VERSION ""

NS_ :

BS_:

BU_: ServiceTool DUT

BO_ 2566764030 DM23: 22 Vector__XXX
 SG_ FlashRedStopLamp : 12|2@1+ (1,0) [0|3] "" Vector__XXX
 SG_ FlashProtectLamp : 8|2@1+ (1,0) [0|3] "" Vector__XXX
 SG_ FlashMalfuncIndicatorLamp : 14|2@1+ (1,0) [0|3] "" Vector__XXX
 SG_ FlashAmberWarningLamp : 10|2@1+ (1,0) [0|3] "" Vector__XXX
 SG_ MalfunctionIndicatorLampStatus : 6|2@1+ (1,0) [0|3] "" Vector__XXX
 SG_ RedStopLampState : 4|2@1+ (1,0) [0|3] "" Vector__XXX
 SG_ AmberWarningLampStatus : 2|2@1+ (1,0) [0|3] "" Vector__XXX
 SG_ ProtectLampStatus : 0|2@1+ (1,0) [0|3] "" Vector__XXX
 SG_ DTC5 : 144|32@1+ (1,0) [0|4294967295] "" Vector__XXX
 SG_ DTC4 : 112|32@1+ (1,0) [0|4294967295] "" Vector__XXX
 SG_ DTC3 : 80|32@1+ (1,0) [0|4294967295] "" Vector__XXX
 SG_ DTC2 : 48|32@1+ (1,0) [0|4294967295] "" Vector__XXX
 SG_ DTC1 : 16|32@1+ (1,0) [0|4294967295] "" Vector__XXX

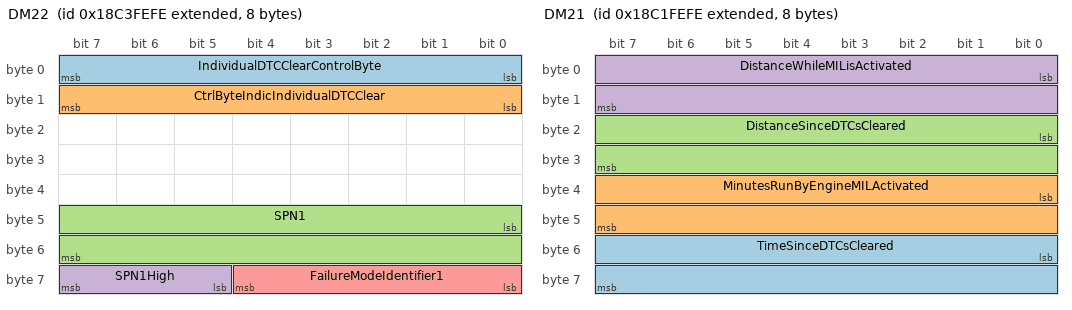
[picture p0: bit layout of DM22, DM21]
BO_ 2562981630 DM22: 8 Vector__XXX
 SG_ IndividualDTCClearControlByte : 0|8@1+ (1,0) [0|255] "" Vector__XXX
 SG_ CtrlByteIndicIndividualDTCClear : 8|8@1+ (1,0) [0|255] "" Vector__XXX
 SG_ SPN1 : 40|16@1+ (1,0) [0|65536] "" Vector__XXX
 SG_ SPN1High : 61|3@1+ (1,0) [0|7] "" Vector__XXX
 SG_ FailureModeIdentifier1 : 56|5@1+ (1,0) [0|0] "" Vector__XXX

BO_ 2562850558 DM21: 8 Vector__XXX
 SG_ TimeSinceDTCsCleared : 48|16@1+ (1,0) [0|64255] "mins" Vector__XXX
 SG_ MinutesRunByEngineMILActivated : 32|16@1+ (1,0) [0|64255] "mins" Vector__XXX
 SG_ DistanceSinceDTCsCleared : 16|16@1+ (1,0) [0|64255] "km" Vector__XXX
 SG_ DistanceWhileMILisActivated : 0|16@1+ (1,0) [0|64255] "km" Vector__XXX

BO_ 2562916094 DM20: 11 Vector__XXX
 SG_ ApplSysMonitorDenominator : 72|16@1+ (1,0) [0|65535] "" Vector__XXX
 SG_ ApplSysMonitorNumerator : 56|16@1+ (1,0) [0|65535] "" Vector__XXX
 SG_ SPNofApplSysMonitor : 32|24@1+ (1,0) [0|524287] "" Vector__XXX
 SG_ OBDMonitoringCondEncountered : 16|16@1+ (1,0) [0|65535] "" Vector__XXX
 SG_ IgnitionCycleCounter : 0|16@1+ (1,0) [0|65535] "" Vector__XXX

BO_ 2566835198 DM2: 22 Vector__XXX
 SG_ MalfunctionIndicatorLampStatus : 6|2@1+ (1,0) [0|3] "" Vector__XXX
 SG_ RedStopLampState : 4|2@1+ (1,0) [0|3] "" Vector__XXX
 SG_ AmberWarningLampStatus : 2|2@1+ (1,0) [0|3] "" Vector__XXX
 SG_ ProtectLampStatus : 0|2@1+ (1,0) [0|3] "" Vector__XXX
 SG_ FlashRedStopLamp : 12|2@1+ (1,0) [0|3] "" Vector__XXX
 SG_ FlashProtectLamp : 8|2@1+ (1,0) [0|3] "" Vector__XXX
 SG_ FlashMalfuncIndicatorLamp : 14|2@1+ (1,0) [0|3] "" Vector__XXX
 SG_ FlashAmberWarningLamp : 10|2@1+ (1,0) [0|3] "" Vector__XXX
 SG_ DTC5 : 144|32@1+ (1,0) [0|4294967295] "" Vector__XXX
 SG_ DTC4 : 112|32@1+ (1,0) [0|4294967295] "" Vector__XXX
 SG_ DTC3 : 80|32@1+ (1,0) [0|4294967295] "" Vector__XXX
 SG_ DTC2 : 48|32@1+ (1,0) [0|4294967295] "" Vector__XXX
 SG_ DTC1 : 16|32@1+ (1,0) [0|4294967295] "" Vector__XXX

BO_ 2564030206 DM19: 20 Vector__XXX
 SG_ CalibrationID4 : 128|32@1+ (1,0) [0|4294967295] "" Vector__XXX
 SG_ CalibrationID3 : 96|32@1+ (1,0) [0|4294967295] "" Vector__XXX
 SG_ CalibrationID2 : 64|32@1+ (1,0) [0|4294967295] "" Vector__XXX
 SG_ CalibrationID1 : 32|32@1+ (1,0) [0|4294967295] "" Vector__XXX
 SG_ CalibrationVerificationNumber : 0|32@1+ (1,0) [0|4294967295] "" Vector__XXX

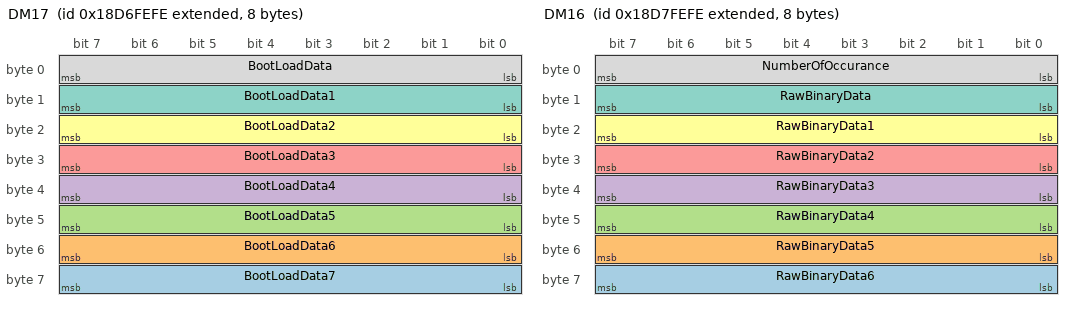
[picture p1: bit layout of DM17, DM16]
BO_ 2564226814 DM17: 8 Vector__XXX
 SG_ BootLoadData7 : 56|8@1- (1,0) [0|0] "" Vector__XXX
 SG_ BootLoadData6 : 48|8@1- (1,0) [0|0] "" Vector__XXX
 SG_ BootLoadData5 : 40|8@1- (1,0) [0|0] "" Vector__XXX
 SG_ BootLoadData4 : 32|8@1- (1,0) [0|0] "" Vector__XXX
 SG_ BootLoadData3 : 24|8@1- (1,0) [0|0] "" Vector__XXX
 SG_ BootLoadData2 : 16|8@1- (1,0) [0|0] "" Vector__XXX
 SG_ BootLoadData1 : 8|8@1- (1,0) [0|0] "" Vector__XXX
 SG_ BootLoadData : 0|8@1- (1,0) [0|0] "" Vector__XXX

BO_ 2564292350 DM16: 8 Vector__XXX
 SG_ RawBinaryData6 : 56|8@1- (1,0) [0|0] "" Vector__XXX
 SG_ RawBinaryData5 : 48|8@1- (1,0) [0|0] "" Vector__XXX
 SG_ RawBinaryData4 : 40|8@1- (1,0) [0|0] "" Vector__XXX
 SG_ RawBinaryData3 : 32|8@1- (1,0) [0|0] "" Vector__XXX
 SG_ RawBinaryData2 : 24|8@1- (1,0) [0|0] "" Vector__XXX
 SG_ RawBinaryData1 : 16|8@1- (1,0) [0|0] "" Vector__XXX
 SG_ RawBinaryData : 8|8@1- (1,0) [0|0] "" Vector__XXX
 SG_ NumberOfOccurance : 0|8@1+ (1,0) [0|0] "" Vector__XXX

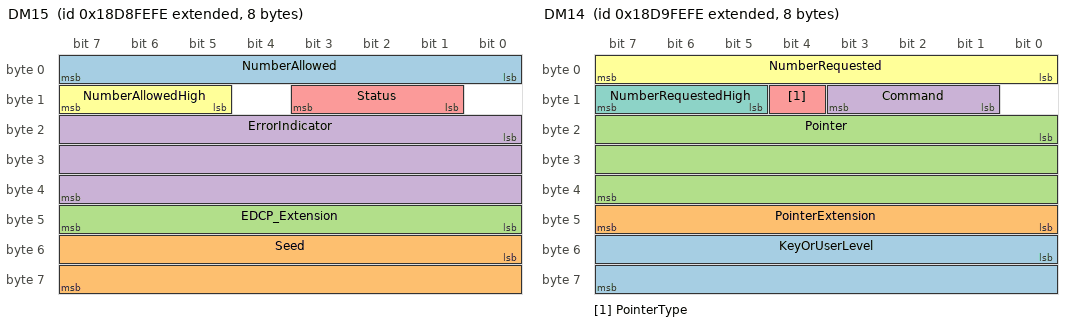
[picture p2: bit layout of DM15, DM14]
BO_ 2564357886 DM15: 8 Vector__XXX
 SG_ NumberAllowed : 0|8@1+ (1,0) [0|2047] "" Vector__XXX
 SG_ Seed : 48|16@1+ (1,0) [0|65535] "" Vector__XXX
 SG_ EDCP_Extension : 40|8@1+ (1,0) [0|255] "" Vector__XXX
 SG_ ErrorIndicator : 16|24@1+ (1,0) [0|16777215] "" Vector__XXX
 SG_ Status : 9|3@1+ (1,0) [0|7] "" Vector__XXX
 SG_ NumberAllowedHigh : 13|3@1+ (1,0) [0|7] "" Vector__XXX

BO_ 2564423422 DM14: 8 Vector__XXX
 SG_ KeyOrUserLevel : 48|16@1+ (1,0) [0|65535] "" Vector__XXX
 SG_ PointerExtension : 40|8@1+ (1,0) [0|255] "" Vector__XXX
 SG_ Pointer : 16|24@1+ (1,0) [0|16777215] "" Vector__XXX
 SG_ Command : 9|3@1+ (1,0) [0|7] "" Vector__XXX
 SG_ PointerType : 12|1@1+ (1,0) [0|1] "" Vector__XXX
 SG_ NumberRequested : 0|8@1+ (1,0) [0|2047] "" Vector__XXX
 SG_ NumberRequestedHigh : 13|3@1+ (1,0) [0|7] "" Vector__XXX

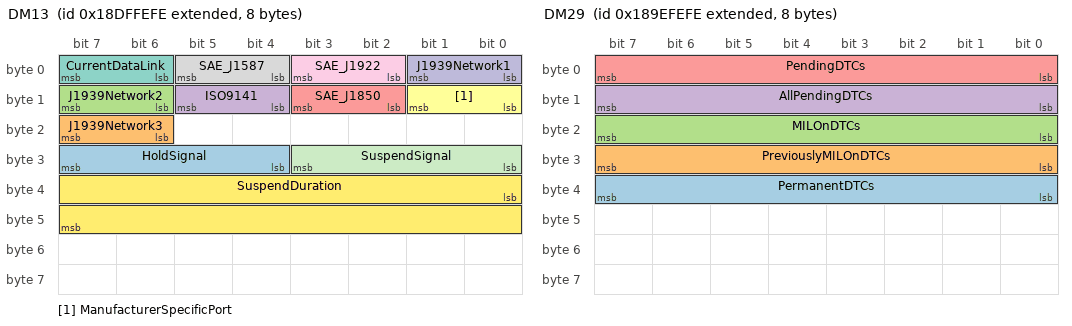
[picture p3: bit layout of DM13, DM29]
BO_ 2564816638 DM13: 8 Vector__XXX
 SG_ HoldSignal : 28|4@1+ (1,0) [0|15] "" Vector__XXX
 SG_ J1939Network3 : 22|2@1+ (1,0) [0|3] "" Vector__XXX
 SG_ J1939Network2 : 14|2@1+ (1,0) [0|3] "" Vector__XXX
 SG_ ISO9141 : 12|2@1+ (1,0) [0|3] "" Vector__XXX
 SG_ SAE_J1850 : 10|2@1+ (1,0) [0|3] "" Vector__XXX
 SG_ ManufacturerSpecificPort : 8|2@1+ (1,0) [0|3] "" Vector__XXX
 SG_ CurrentDataLink : 6|2@1+ (1,0) [0|3] "" Vector__XXX
 SG_ SAE_J1587 : 4|2@1+ (1,0) [0|3] "" Vector__XXX
 SG_ SAE_J1922 : 2|2@1+ (1,0) [0|3] "" Vector__XXX
 SG_ J1939Network1 : 0|2@1+ (1,0) [0|3] "" Vector__XXX
 SG_ SuspendSignal : 24|4@1+ (1,0) [0|15] "" Vector__XXX
 SG_ SuspendDuration : 32|16@1+ (1,0) [0|64255] "sec" Vector__XXX

BO_ 2566837502 DM12: 22 Vector__XXX
 SG_ FlashRedStopLamp : 12|2@1+ (1,0) [0|3] "" Vector__XXX
 SG_ FlashProtectLamp : 8|2@1+ (1,0) [0|3] "" Vector__XXX
 SG_ MalfunctionIndicatorLampStatus : 6|2@1+ (1,0) [0|3] "" Vector__XXX
 SG_ RedStopLampState : 4|2@1+ (1,0) [0|3] "" Vector__XXX
 SG_ AmberWarningLampStatus : 2|2@1+ (1,0) [0|3] "" Vector__XXX
 SG_ ProtectLampStatus : 0|2@1+ (1,0) [0|3] "" Vector__XXX
 SG_ FlashMalfuncIndicatorLamp : 14|2@1+ (1,0) [0|3] "" Vector__XXX
 SG_ FlashAmberWarningLamp : 10|2@1+ (1,0) [0|3] "" Vector__XXX
 SG_ DTC5 : 144|32@1+ (1,0) [0|4294967295] "" Vector__XXX
 SG_ DTC4 : 112|32@1+ (1,0) [0|4294967295] "" Vector__XXX
 SG_ DTC3 : 80|32@1+ (1,0) [0|4294967295] "" Vector__XXX
 SG_ DTC2 : 48|32@1+ (1,0) [0|4294967295] "" Vector__XXX
 SG_ DTC1 : 16|32@1+ (1,0) [0|4294967295] "" Vector__XXX

BO_ 2566837246 DM11: 0 Vector__XXX

BO_ 2566836990 DM10: 8 Vector__XXX
 SG_ TestIdentifierSupported : 0|64@1+ (1,0) [1|1.844674407371E+019] "" Vector__XXX

BO_ 2566834942 DM1: 22 Vector__XXX
 SG_ FlashRedStopLamp : 12|2@1+ (1,0) [0|3] "" Vector__XXX
 SG_ FlashProtectLamp : 8|2@1+ (1,0) [0|3] "" Vector__XXX
 SG_ FlashMalfuncIndicatorLamp : 14|2@1+ (1,0) [0|3] "" Vector__XXX
 SG_ FlashAmberWarningLamp : 10|2@1+ (1,0) [0|3] "" Vector__XXX
 SG_ MalfunctionIndicatorLampStatus : 6|2@1+ (1,0) [0|3] "" Vector__XXX
 SG_ AmberWarningLampStatus : 2|2@1+ (1,0) [0|3] "" Vector__XXX
 SG_ RedStopLampState : 4|2@1+ (1,0) [0|3] "" Vector__XXX
 SG_ ProtectLampStatus : 0|2@1+ (1,0) [0|3] "" Vector__XXX
 SG_ DTC5 : 144|32@1+ (1,0) [0|4294967295] "" Vector__XXX
 SG_ DTC4 : 112|32@1+ (1,0) [0|4294967295] "" Vector__XXX
 SG_ DTC3 : 80|32@1+ (1,0) [0|4294967295] "" Vector__XXX
 SG_ DTC2 : 48|32@1+ (1,0) [0|4294967295] "" Vector__XXX
 SG_ DTC1 : 16|32@1+ (1,0) [0|4294967295] "" Vector__XXX

BO_ 2566838526 CA: 9 Vector__XXX
 SG_ AddressAssignment : 64|8@1+ (1,0) [0|255] "" Vector__XXX
 SG_ ArbitraryAddressCapable : 63|1@1+ (1,0) [0|1] "" Vector__XXX
 SG_ IndustryGroup M : 60|3@1+ (1,0) [0|7] "" Vector__XXX
 SG_ VehicleSystemInstance : 56|4@1+ (1,0) [0|15] "" Vector__XXX
 SG_ Function : 40|8@1+ (1,0) [0|255] "" Vector__XXX
 SG_ VehicleSystem m0 : 49|7@1+ (1,0) [0|127] "" Vector__XXX
 SG_ FunctionInstance : 35|5@1+ (1,0) [0|31] "" Vector__XXX
 SG_ ECUInstance : 32|3@1+ (1,0) [0|7] "" Vector__XXX
 SG_ ManufacturerCode : 21|11@1+ (1,0) [0|2047] "" Vector__XXX
 SG_ IdentityNumber : 0|21@1+ (1,0) [0|2097152] "" Vector__XXX
 SG_ VehicleSystem5 m5 : 49|7@1+ (1,0) [0|127] "" Vector__XXX
 SG_ VehicleSystem4 m4 : 49|7@1+ (1,0) [0|127] "" Vector__XXX
 SG_ VehicleSystem3 m3 : 49|7@1+ (1,0) [0|127] "" Vector__XXX
 SG_ VehicleSystem2 m2 : 49|7@1+ (1,0) [0|127] "" Vector__XXX
 SG_ VehicleSystem1 m1 : 49|7@1+ (1,0) [0|127] "" Vector__XXX

BO_ 2632711934 TPDT: 8 Vector__XXX
 SG_ SequenceNumber : 0|8@1+ (1,0) [0|255] "" Vector__XXX

BO_ 2632777470 TPCM: 8 Vector__XXX
 SG_ TotalNumberOfPacketsEoMA m19 : 24|8@1+ (1,0) [0|255] "" Vector__XXX
 SG_ TotalMessageSizeEoMA m19 : 8|16@1+ (1,0) [0|64255] "counts" Vector__XXX
 SG_ TotalMessageSizeBAM m32 : 8|16@1+ (1,0) [0|64255] "counts" Vector__XXX
 SG_ TotalNumberOfPacketsBAM m32 : 24|8@1+ (1,0) [0|255] "" Vector__XXX
 SG_ ConnectionAbortReason m255 : 8|8@1+ (1,0) [0|255] "" Vector__XXX
 SG_ NextPacketNumberToBeSent m17 : 16|8@1+ (1,0) [0|255] "" Vector__XXX
 SG_ NumberOfPacketsThatCanBeSent m17 : 8|8@1+ (1,0) [0|255] "" Vector__XXX
 SG_ PGNumber : 40|24@1+ (1,0) [0|16777200] "" Vector__XXX
 SG_ MaximumNumberOfPackets m16 : 32|8@1+ (1,0) [0|255] "" Vector__XXX
 SG_ TotalNumberOfPackets m16 : 24|8@1+ (1,0) [0|255] "" Vector__XXX
 SG_ TotalMessageSize m16 : 8|16@1+ (1,0) [0|64255] "counts" Vector__XXX
 SG_ ControlByte M : 0|8@1+ (1,0) [0|255] "" Vector__XXX

BO_ 2565537534 RQST: 3 Vector__XXX
 SG_ ParameterGroupNumber : 0|24@1+ (1,0) [0|16777215] "" Vector__XXX

BO_ 2566739198 DM52: 22 Vector__XXX
 SG_ FlashRedStopLamp : 12|2@1+ (1,0) [0|3] "" Vector__XXX
 SG_ FlashProtectLamp : 8|2@1+ (1,0) [0|3] "" Vector__XXX
 SG_ FlashMalfuncIndicatorLamp : 14|2@1+ (1,0) [0|3] "" Vector__XXX
 SG_ FlashAmberWarningLamp : 10|2@1+ (1,0) [0|3] "" Vector__XXX
 SG_ MalfunctionIndicatorLampStatus : 6|2@1+ (1,0) [0|3] "" Vector__XXX
 SG_ AmberWarningLampStatus : 2|2@1+ (1,0) [0|3] "" Vector__XXX
 SG_ RedStopLampState : 4|2@1+ (1,0) [0|3] "" Vector__XXX
 SG_ ProtectLampStatus : 0|2@1+ (1,0) [0|3] "" Vector__XXX
 SG_ DTC5 : 144|32@1+ (1,0) [0|4294967295] "" Vector__XXX
 SG_ DTC4 : 112|32@1+ (1,0) [0|4294967295] "" Vector__XXX
 SG_ DTC3 : 80|32@1+ (1,0) [0|4294967295] "" Vector__XXX
 SG_ DTC2 : 48|32@1+ (1,0) [0|4294967295] "" Vector__XXX
 SG_ DTC1 : 16|32@1+ (1,0) [0|4294967295] "" Vector__XXX

BO_ 2566739454 DM51: 22 Vector__XXX
 SG_ FlashRedStopLamp : 12|2@1+ (1,0) [0|3] "" Vector__XXX
 SG_ FlashProtectLamp : 8|2@1+ (1,0) [0|3] "" Vector__XXX
 SG_ FlashMalfuncIndicatorLamp : 14|2@1+ (1,0) [0|3] "" Vector__XXX
 SG_ FlashAmberWarningLamp : 10|2@1+ (1,0) [0|3] "" Vector__XXX
 SG_ MalfunctionIndicatorLampStatus : 6|2@1+ (1,0) [0|3] "" Vector__XXX
 SG_ AmberWarningLampStatus : 2|2@1+ (1,0) [0|3] "" Vector__XXX
 SG_ RedStopLampState : 4|2@1+ (1,0) [0|3] "" Vector__XXX
 SG_ ProtectLampStatus : 0|2@1+ (1,0) [0|3] "" Vector__XXX
 SG_ DTC5 : 144|32@1+ (1,0) [0|4294967295] "" Vector__XXX
 SG_ DTC4 : 112|32@1+ (1,0) [0|4294967295] "" Vector__XXX
 SG_ DTC3 : 80|32@1+ (1,0) [0|4294967295] "" Vector__XXX
 SG_ DTC2 : 48|32@1+ (1,0) [0|4294967295] "" Vector__XXX
 SG_ DTC1 : 16|32@1+ (1,0) [0|4294967295] "" Vector__XXX

BO_ 2566739710 DM50: 22 Vector__XXX
 SG_ FlashRedStopLamp : 12|2@1+ (1,0) [0|3] "" Vector__XXX
 SG_ FlashProtectLamp : 8|2@1+ (1,0) [0|3] "" Vector__XXX
 SG_ FlashMalfuncIndicatorLamp : 14|2@1+ (1,0) [0|3] "" Vector__XXX
 SG_ FlashAmberWarningLamp : 10|2@1+ (1,0) [0|3] "" Vector__XXX
 SG_ MalfunctionIndicatorLampStatus : 6|2@1+ (1,0) [0|3] "" Vector__XXX
 SG_ AmberWarningLampStatus : 2|2@1+ (1,0) [0|3] "" Vector__XXX
 SG_ RedStopLampState : 4|2@1+ (1,0) [0|3] "" Vector__XXX
 SG_ ProtectLampStatus : 0|2@1+ (1,0) [0|3] "" Vector__XXX
 SG_ DTC5 : 144|32@1+ (1,0) [0|4294967295] "" Vector__XXX
 SG_ DTC4 : 112|32@1+ (1,0) [0|4294967295] "" Vector__XXX
 SG_ DTC3 : 80|32@1+ (1,0) [0|4294967295] "" Vector__XXX
 SG_ DTC2 : 48|32@1+ (1,0) [0|4294967295] "" Vector__XXX
 SG_ DTC1 : 16|32@1+ (1,0) [0|4294967295] "" Vector__XXX

BO_ 2566739966 DM49: 22 Vector__XXX
 SG_ FlashRedStopLamp : 12|2@1+ (1,0) [0|3] "" Vector__XXX
 SG_ FlashProtectLamp : 8|2@1+ (1,0) [0|3] "" Vector__XXX
 SG_ FlashMalfuncIndicatorLamp : 14|2@1+ (1,0) [0|3] "" Vector__XXX
 SG_ FlashAmberWarningLamp : 10|2@1+ (1,0) [0|3] "" Vector__XXX
 SG_ MalfunctionIndicatorLampStatus : 6|2@1+ (1,0) [0|3] "" Vector__XXX
 SG_ AmberWarningLampStatus : 2|2@1+ (1,0) [0|3] "" Vector__XXX
 SG_ RedStopLampState : 4|2@1+ (1,0) [0|3] "" Vector__XXX
 SG_ ProtectLampStatus : 0|2@1+ (1,0) [0|3] "" Vector__XXX
 SG_ DTC5 : 144|32@1+ (1,0) [0|4294967295] "" Vector__XXX
 SG_ DTC4 : 112|32@1+ (1,0) [0|4294967295] "" Vector__XXX
 SG_ DTC3 : 80|32@1+ (1,0) [0|4294967295] "" Vector__XXX
 SG_ DTC2 : 48|32@1+ (1,0) [0|4294967295] "" Vector__XXX
 SG_ DTC1 : 16|32@1+ (1,0) [0|4294967295] "" Vector__XXX

BO_ 2566740222 DM48: 22 Vector__XXX
 SG_ FlashRedStopLamp : 12|2@1+ (1,0) [0|3] "" Vector__XXX
 SG_ FlashProtectLamp : 8|2@1+ (1,0) [0|3] "" Vector__XXX
 SG_ FlashMalfuncIndicatorLamp : 14|2@1+ (1,0) [0|3] "" Vector__XXX
 SG_ FlashAmberWarningLamp : 10|2@1+ (1,0) [0|3] "" Vector__XXX
 SG_ MalfunctionIndicatorLampStatus : 6|2@1+ (1,0) [0|3] "" Vector__XXX
 SG_ AmberWarningLampStatus : 2|2@1+ (1,0) [0|3] "" Vector__XXX
 SG_ RedStopLampState : 4|2@1+ (1,0) [0|3] "" Vector__XXX
 SG_ ProtectLampStatus : 0|2@1+ (1,0) [0|3] "" Vector__XXX
 SG_ DTC5 : 144|32@1+ (1,0) [0|4294967295] "" Vector__XXX
 SG_ DTC4 : 112|32@1+ (1,0) [0|4294967295] "" Vector__XXX
 SG_ DTC3 : 80|32@1+ (1,0) [0|4294967295] "" Vector__XXX
 SG_ DTC2 : 48|32@1+ (1,0) [0|4294967295] "" Vector__XXX
 SG_ DTC1 : 16|32@1+ (1,0) [0|4294967295] "" Vector__XXX

BO_ 2566740478 DM47: 22 Vector__XXX
 SG_ FlashRedStopLamp : 12|2@1+ (1,0) [0|3] "" Vector__XXX
 SG_ FlashProtectLamp : 8|2@1+ (1,0) [0|3] "" Vector__XXX
 SG_ FlashMalfuncIndicatorLamp : 14|2@1+ (1,0) [0|3] "" Vector__XXX
 SG_ FlashAmberWarningLamp : 10|2@1+ (1,0) [0|3] "" Vector__XXX
 SG_ MalfunctionIndicatorLampStatus : 6|2@1+ (1,0) [0|3] "" Vector__XXX
 SG_ AmberWarningLampStatus : 2|2@1+ (1,0) [0|3] "" Vector__XXX
 SG_ RedStopLampState : 4|2@1+ (1,0) [0|3] "" Vector__XXX
 SG_ ProtectLampStatus : 0|2@1+ (1,0) [0|3] "" Vector__XXX
 SG_ DTC5 : 144|32@1+ (1,0) [0|4294967295] "" Vector__XXX
 SG_ DTC4 : 112|32@1+ (1,0) [0|4294967295] "" Vector__XXX
 SG_ DTC3 : 80|32@1+ (1,0) [0|4294967295] "" Vector__XXX
 SG_ DTC2 : 48|32@1+ (1,0) [0|4294967295] "" Vector__XXX
 SG_ DTC1 : 16|32@1+ (1,0) [0|4294967295] "" Vector__XXX

BO_ 2566740734 DM46: 22 Vector__XXX
 SG_ FlashRedStopLamp : 12|2@1+ (1,0) [0|3] "" Vector__XXX
 SG_ FlashProtectLamp : 8|2@1+ (1,0) [0|3] "" Vector__XXX
 SG_ FlashMalfuncIndicatorLamp : 14|2@1+ (1,0) [0|3] "" Vector__XXX
 SG_ FlashAmberWarningLamp : 10|2@1+ (1,0) [0|3] "" Vector__XXX
 SG_ MalfunctionIndicatorLampStatus : 6|2@1+ (1,0) [0|3] "" Vector__XXX
 SG_ AmberWarningLampStatus : 2|2@1+ (1,0) [0|3] "" Vector__XXX
 SG_ RedStopLampState : 4|2@1+ (1,0) [0|3] "" Vector__XXX
 SG_ ProtectLampStatus : 0|2@1+ (1,0) [0|3] "" Vector__XXX
 SG_ DTC5 : 144|32@1+ (1,0) [0|4294967295] "" Vector__XXX
 SG_ DTC4 : 112|32@1+ (1,0) [0|4294967295] "" Vector__XXX
 SG_ DTC3 : 80|32@1+ (1,0) [0|4294967295] "" Vector__XXX
 SG_ DTC2 : 48|32@1+ (1,0) [0|4294967295] "" Vector__XXX
 SG_ DTC1 : 16|32@1+ (1,0) [0|4294967295] "" Vector__XXX

BO_ 2566740990 DM45: 22 Vector__XXX
 SG_ FlashRedStopLamp : 12|2@1+ (1,0) [0|3] "" Vector__XXX
 SG_ FlashProtectLamp : 8|2@1+ (1,0) [0|3] "" Vector__XXX
 SG_ FlashMalfuncIndicatorLamp : 14|2@1+ (1,0) [0|3] "" Vector__XXX
 SG_ FlashAmberWarningLamp : 10|2@1+ (1,0) [0|3] "" Vector__XXX
 SG_ MalfunctionIndicatorLampStatus : 6|2@1+ (1,0) [0|3] "" Vector__XXX
 SG_ AmberWarningLampStatus : 2|2@1+ (1,0) [0|3] "" Vector__XXX
 SG_ RedStopLampState : 4|2@1+ (1,0) [0|3] "" Vector__XXX
 SG_ ProtectLampStatus : 0|2@1+ (1,0) [0|3] "" Vector__XXX
 SG_ DTC5 : 144|32@1+ (1,0) [0|4294967295] "" Vector__XXX
 SG_ DTC4 : 112|32@1+ (1,0) [0|4294967295] "" Vector__XXX
 SG_ DTC3 : 80|32@1+ (1,0) [0|4294967295] "" Vector__XXX
 SG_ DTC2 : 48|32@1+ (1,0) [0|4294967295] "" Vector__XXX
 SG_ DTC1 : 16|32@1+ (1,0) [0|4294967295] "" Vector__XXX

BO_ 2566741246 DM44: 22 Vector__XXX
 SG_ FlashRedStopLamp : 12|2@1+ (1,0) [0|3] "" Vector__XXX
 SG_ FlashProtectLamp : 8|2@1+ (1,0) [0|3] "" Vector__XXX
 SG_ FlashMalfuncIndicatorLamp : 14|2@1+ (1,0) [0|3] "" Vector__XXX
 SG_ FlashAmberWarningLamp : 10|2@1+ (1,0) [0|3] "" Vector__XXX
 SG_ MalfunctionIndicatorLampStatus : 6|2@1+ (1,0) [0|3] "" Vector__XXX
 SG_ AmberWarningLampStatus : 2|2@1+ (1,0) [0|3] "" Vector__XXX
 SG_ RedStopLampState : 4|2@1+ (1,0) [0|3] "" Vector__XXX
 SG_ ProtectLampStatus : 0|2@1+ (1,0) [0|3] "" Vector__XXX
 SG_ DTC5 : 144|32@1+ (1,0) [0|4294967295] "" Vector__XXX
 SG_ DTC4 : 112|32@1+ (1,0) [0|4294967295] "" Vector__XXX
 SG_ DTC3 : 80|32@1+ (1,0) [0|4294967295] "" Vector__XXX
 SG_ DTC2 : 48|32@1+ (1,0) [0|4294967295] "" Vector__XXX
 SG_ DTC1 : 16|32@1+ (1,0) [0|4294967295] "" Vector__XXX

BO_ 2566741502 DM43: 22 Vector__XXX
 SG_ FlashRedStopLamp : 12|2@1+ (1,0) [0|3] "" Vector__XXX
 SG_ FlashProtectLamp : 8|2@1+ (1,0) [0|3] "" Vector__XXX
 SG_ FlashMalfuncIndicatorLamp : 14|2@1+ (1,0) [0|3] "" Vector__XXX
 SG_ FlashAmberWarningLamp : 10|2@1+ (1,0) [0|3] "" Vector__XXX
 SG_ MalfunctionIndicatorLampStatus : 6|2@1+ (1,0) [0|3] "" Vector__XXX
 SG_ AmberWarningLampStatus : 2|2@1+ (1,0) [0|3] "" Vector__XXX
 SG_ RedStopLampState : 4|2@1+ (1,0) [0|3] "" Vector__XXX
 SG_ ProtectLampStatus : 0|2@1+ (1,0) [0|3] "" Vector__XXX
 SG_ DTC5 : 144|32@1+ (1,0) [0|4294967295] "" Vector__XXX
 SG_ DTC4 : 112|32@1+ (1,0) [0|4294967295] "" Vector__XXX
 SG_ DTC3 : 80|32@1+ (1,0) [0|4294967295] "" Vector__XXX
 SG_ DTC2 : 48|32@1+ (1,0) [0|4294967295] "" Vector__XXX
 SG_ DTC1 : 16|32@1+ (1,0) [0|4294967295] "" Vector__XXX

BO_ 2566741758 DM42: 22 Vector__XXX
 SG_ FlashRedStopLamp : 12|2@1+ (1,0) [0|3] "" Vector__XXX
 SG_ FlashProtectLamp : 8|2@1+ (1,0) [0|3] "" Vector__XXX
 SG_ FlashMalfuncIndicatorLamp : 14|2@1+ (1,0) [0|3] "" Vector__XXX
 SG_ FlashAmberWarningLamp : 10|2@1+ (1,0) [0|3] "" Vector__XXX
 SG_ MalfunctionIndicatorLampStatus : 6|2@1+ (1,0) [0|3] "" Vector__XXX
 SG_ AmberWarningLampStatus : 2|2@1+ (1,0) [0|3] "" Vector__XXX
 SG_ RedStopLampState : 4|2@1+ (1,0) [0|3] "" Vector__XXX
 SG_ ProtectLampStatus : 0|2@1+ (1,0) [0|3] "" Vector__XXX
 SG_ DTC5 : 144|32@1+ (1,0) [0|4294967295] "" Vector__XXX
 SG_ DTC4 : 112|32@1+ (1,0) [0|4294967295] "" Vector__XXX
 SG_ DTC3 : 80|32@1+ (1,0) [0|4294967295] "" Vector__XXX
 SG_ DTC2 : 48|32@1+ (1,0) [0|4294967295] "" Vector__XXX
 SG_ DTC1 : 16|32@1+ (1,0) [0|4294967295] "" Vector__XXX

BO_ 2566742014 DM41: 22 Vector__XXX
 SG_ FlashRedStopLamp : 12|2@1+ (1,0) [0|3] "" Vector__XXX
 SG_ FlashProtectLamp : 8|2@1+ (1,0) [0|3] "" Vector__XXX
 SG_ FlashMalfuncIndicatorLamp : 14|2@1+ (1,0) [0|3] "" Vector__XXX
 SG_ FlashAmberWarningLamp : 10|2@1+ (1,0) [0|3] "" Vector__XXX
 SG_ MalfunctionIndicatorLampStatus : 6|2@1+ (1,0) [0|3] "" Vector__XXX
 SG_ AmberWarningLampStatus : 2|2@1+ (1,0) [0|3] "" Vector__XXX
 SG_ RedStopLampState : 4|2@1+ (1,0) [0|3] "" Vector__XXX
 SG_ ProtectLampStatus : 0|2@1+ (1,0) [0|3] "" Vector__XXX
 SG_ DTC5 : 144|32@1+ (1,0) [0|4294967295] "" Vector__XXX
 SG_ DTC4 : 112|32@1+ (1,0) [0|4294967295] "" Vector__XXX
 SG_ DTC3 : 80|32@1+ (1,0) [0|4294967295] "" Vector__XXX
 SG_ DTC2 : 48|32@1+ (1,0) [0|4294967295] "" Vector__XXX
 SG_ DTC1 : 16|32@1+ (1,0) [0|4294967295] "" Vector__XXX

BO_ 2560622334 DM35: 22 Vector__XXX
 SG_ FlashRedStopLamp : 12|2@1+ (1,0) [0|3] "" Vector__XXX
 SG_ FlashProtectLamp : 8|2@1+ (1,0) [0|3] "" Vector__XXX
 SG_ FlashMalfuncIndicatorLamp : 14|2@1+ (1,0) [0|3] "" Vector__XXX
 SG_ FlashAmberWarningLamp : 10|2@1+ (1,0) [0|3] "" Vector__XXX
 SG_ MalfunctionIndicatorLampStatus : 6|2@1+ (1,0) [0|3] "" Vector__XXX
 SG_ AmberWarningLampStatus : 2|2@1+ (1,0) [0|3] "" Vector__XXX
 SG_ RedStopLampState : 4|2@1+ (1,0) [0|3] "" Vector__XXX
 SG_ ProtectLampStatus : 0|2@1+ (1,0) [0|3] "" Vector__XXX
 SG_ DTC5 : 144|32@1+ (1,0) [0|4294967295] "" Vector__XXX
 SG_ DTC4 : 112|32@1+ (1,0) [0|4294967295] "" Vector__XXX
 SG_ DTC3 : 80|32@1+ (1,0) [0|4294967295] "" Vector__XXX
 SG_ DTC2 : 48|32@1+ (1,0) [0|4294967295] "" Vector__XXX
 SG_ DTC1 : 16|32@1+ (1,0) [0|4294967295] "" Vector__XXX

BO_ 2560556798 DM29: 8 Vector__XXX
 SG_ PermanentDTCs : 32|8@1+ (1,0) [0|255] "" Vector__XXX
 SG_ PreviouslyMILOnDTCs : 24|8@1+ (1,0) [0|255] "" Vector__XXX
 SG_ MILOnDTCs : 16|8@1+ (1,0) [0|255] "" Vector__XXX
 SG_ AllPendingDTCs : 8|8@1+ (1,0) [0|255] "" Vector__XXX
 SG_ PendingDTCs : 0|8@1+ (1,0) [0|255] "" Vector__XXX

BO_ 2566750462 DM28: 22 Vector__XXX
 SG_ FlashRedStopLamp : 12|2@1+ (1,0) [0|3] "" Vector__XXX
 SG_ FlashProtectLamp : 8|2@1+ (1,0) [0|3] "" Vector__XXX
 SG_ FlashMalfuncIndicatorLamp : 14|2@1+ (1,0) [0|3] "" Vector__XXX
 SG_ FlashAmberWarningLamp : 10|2@1+ (1,0) [0|3] "" Vector__XXX
 SG_ MalfunctionIndicatorLampStatus : 6|2@1+ (1,0) [0|3] "" Vector__XXX
 SG_ AmberWarningLampStatus : 2|2@1+ (1,0) [0|3] "" Vector__XXX
 SG_ RedStopLampState : 4|2@1+ (1,0) [0|3] "" Vector__XXX
 SG_ ProtectLampStatus : 0|2@1+ (1,0) [0|3] "" Vector__XXX
 SG_ DTC5 : 144|32@1+ (1,0) [0|4294967295] "" Vector__XXX
 SG_ DTC4 : 112|32@1+ (1,0) [0|4294967295] "" Vector__XXX
 SG_ DTC3 : 80|32@1+ (1,0) [0|4294967295] "" Vector__XXX
 SG_ DTC2 : 48|32@1+ (1,0) [0|4294967295] "" Vector__XXX
 SG_ DTC1 : 16|32@1+ (1,0) [0|4294967295] "" Vector__XXX

BO_ 2566750974 DM27: 22 Vector__XXX
 SG_ FlashRedStopLamp : 12|2@1+ (1,0) [0|3] "" Vector__XXX
 SG_ FlashProtectLamp : 8|2@1+ (1,0) [0|3] "" Vector__XXX
 SG_ FlashMalfuncIndicatorLamp : 14|2@1+ (1,0) [0|3] "" Vector__XXX
 SG_ FlashAmberWarningLamp : 10|2@1+ (1,0) [0|3] "" Vector__XXX
 SG_ MalfunctionIndicatorLampStatus : 6|2@1+ (1,0) [0|3] "" Vector__XXX
 SG_ AmberWarningLampStatus : 2|2@1+ (1,0) [0|3] "" Vector__XXX
 SG_ RedStopLampState : 4|2@1+ (1,0) [0|3] "" Vector__XXX
 SG_ ProtectLampStatus : 0|2@1+ (1,0) [0|3] "" Vector__XXX
 SG_ DTC5 : 144|32@1+ (1,0) [0|4294967295] "" Vector__XXX
 SG_ DTC4 : 112|32@1+ (1,0) [0|4294967295] "" Vector__XXX
 SG_ DTC3 : 80|32@1+ (1,0) [0|4294967295] "" Vector__XXX
 SG_ DTC2 : 48|32@1+ (1,0) [0|4294967295] "" Vector__XXX
 SG_ DTC1 : 16|32@1+ (1,0) [0|4294967295] "" Vector__XXX

CM_ BO_ 2566764030 "Previously active emission related faults.";
CM_ SG_ 2566764030 FlashRedStopLamp "This parameter provides the capability to flash the RSL (SPN 3039).";
CM_ SG_ 2566764030 FlashProtectLamp "This parameter provides the capability to flash the engine protect lamp (SPN 3041).";
CM_ SG_ 2566764030 FlashMalfuncIndicatorLamp "This parameter provides the capability to flash the MIL (SPN 3038).";
CM_ SG_ 2566764030 FlashAmberWarningLamp "This parameter provides the capability to flash the AWL (SPN 3040). ";
CM_ SG_ 2566764030 MalfunctionIndicatorLampStatus "A lamp used to relay only emissions-related trouble code information.";
CM_ SG_ 2566764030 RedStopLampState "This lamp is uesed to relay trouble code information that is of a severe enought condition that it warrants stopping the vehicle.";
CM_ SG_ 2566764030 AmberWarningLampStatus "This lamp is used to relay trouble code information that is reporting a problem with the vehicle system but the vehicle need
not be immediately stopped.";
CM_ SG_ 2566764030 ProtectLampStatus "This lamp is used to relay trouble code informatio that is reporting a problem with a vehicle system that is most
probably not electronic subsystem related.";
CM_ SG_ 2566764030 DTC5 "Diagnostic Trouble Code";
CM_ SG_ 2566764030 DTC4 "Diagnostic Trouble Code";
CM_ SG_ 2566764030 DTC3 "Diagnostic Trouble Code";
CM_ SG_ 2566764030 DTC2 "Diagnostic Trouble Code";
CM_ SG_ 2566764030 DTC1 "Diagnostic Trouble Code";
CM_ BO_ 2562981630 "Individual Clear/Reset of active and previously active DTC.";
CM_ SG_ 2562981630 SPN1 "SPN #1 (Conversion Version 4)";
CM_ SG_ 2562981630 SPN1High "SPN #1 (Conversion Version 4)";
CM_ SG_ 2562981630 FailureModeIdentifier1 "The FMI defines the type of failure detected in the subsystem identified by an SPN.";
CM_ BO_ 2562850558 "Diagnostic readiness 2";
CM_ SG_ 2562850558 TimeSinceDTCsCleared "Time accumulated since DTCs were cleared (via an external test equipment or possibly, a battery disconnect) (SPN=?).";
CM_ SG_ 2562850558 MinutesRunByEngineMILActivated "Accumulated count (in minutes) while the MIL is activated (on) (SPN=?).";
CM_ SG_ 2562850558 DistanceSinceDTCsCleared "Distance accumulated since DTCs were cleared (SPN=?).";
CM_ SG_ 2562850558 DistanceWhileMILisActivated "The kilometers accumulated while the MIL is activated (SPN 3060).";
CM_ BO_ 2562916094 "Monitor Performance Ratio";
CM_ SG_ 2562916094 ApplSysMonitorDenominator "The number of times a vehicle has been operated that constitutes a driving cycle where this Applicable System Monitor could be operated per regulatory requirements (SPN 3068).";
CM_ SG_ 2562916094 ApplSysMonitorNumerator "The number of times a vehicle has been operated such that all conditions necessary for the Applicable System Monitor to detect a malfunction have been encountered (SPN 3067).";
CM_ SG_ 2562916094 SPNofApplSysMonitor "Contain the SPN of the system monitor for which Monitor ratio is being reported (SPN 3066).";
CM_ SG_ 2562916094 OBDMonitoringCondEncountered "Displays the number of times that the vehicle has been operated in the specified OBD monitoring conditions (SPN 3049).";
CM_ SG_ 2562916094 IgnitionCycleCounter "A single counter that defines the number of ignition cycles (SPN 3048).";
CM_ BO_ 2566835198 "Previously active diagnostic trouble codes";
CM_ SG_ 2566835198 MalfunctionIndicatorLampStatus "A lamp used to relay only emissions-related trouble code information.";
CM_ SG_ 2566835198 RedStopLampState "This lamp is uesed to relay trouble code information that is of a severe enought condition that it warrants stopping the vehicle.";
CM_ SG_ 2566835198 AmberWarningLampStatus "This lamp is used to relay trouble code information that is reporting a problem with the vehicle system but the vehicle need
not be immediately stopped.";
CM_ SG_ 2566835198 ProtectLampStatus "This lamp is used to relay trouble code informatio that is reporting a problem with a vehicle system that is most
probably not electronic subsystem related.";
CM_ SG_ 2566835198 FlashRedStopLamp "This parameter provides the capability to flash the RSL (SPN 3039).";
CM_ SG_ 2566835198 FlashProtectLamp "This parameter provides the capability to flash the engine protect lamp (SPN 3041).";
CM_ SG_ 2566835198 FlashMalfuncIndicatorLamp "This parameter provides the capability to flash the MIL (SPN 3038).";
CM_ SG_ 2566835198 FlashAmberWarningLamp "This parameter provides the capability to flash the AWL (SPN 3040). ";
CM_ SG_ 2566835198 DTC5 "Diagnostic Trouble Code";
CM_ SG_ 2566835198 DTC4 "Diagnostic Trouble Code";
CM_ SG_ 2566835198 DTC3 "Diagnostic Trouble Code";
CM_ SG_ 2566835198 DTC2 "Diagnostic Trouble Code";
CM_ SG_ 2566835198 DTC1 "Diagnostic Trouble Code";
CM_ BO_ 2564030206 "Calibration Information";
CM_ BO_ 2564226814 "Boot Load Data";
CM_ BO_ 2564292350 "Binary Data Transfer";
CM_ SG_ 2564292350 NumberOfOccurance "Number of occurance of raw binary data";
CM_ BO_ 2564357886 "Memory Access Response";
CM_ SG_ 2564357886 ErrorIndicator "Error Indicator/EDC Parameter";
CM_ BO_ 2564423422 "Memory Access Request";
CM_ SG_ 2564423422 KeyOrUserLevel "Key/User Level";
CM_ SG_ 2564423422 NumberRequested "Length/Number Requested";
CM_ SG_ 2564423422 NumberRequestedHigh "Length/Number Requested";
CM_ BO_ 2564816638 "Stop start broadcast";
CM_ SG_ 2564816638 HoldSignal "Indicator to all nodes that the communication ports that have been acted upon by the 'Stop start broadcast'
PGN are remaining in the modified state.";
CM_ SG_ 2564816638 J1939Network3 "Identifies the action to be performed on the SAE J1939 Network #3.";
CM_ SG_ 2564816638 J1939Network2 "Identifies the action to be performed on the SAE J1939 Network #2.";
CM_ SG_ 2564816638 ISO9141 "Identifies the action to be performed on the ISO9141 communications port.";
CM_ SG_ 2564816638 SAE_J1850 "Identifies the action to be performed on the SAE J1850 communications port.";
CM_ SG_ 2564816638 ManufacturerSpecificPort "Identifies the action to be performed on 'Other, manufacturer specific port' communications port.";
CM_ SG_ 2564816638 CurrentDataLink "Identifies the action to be performed on the communications port that this parameter was received.";
CM_ SG_ 2564816638 SAE_J1587 "Identifies the action to be performed on the SAE J1587 communications port.";
CM_ SG_ 2564816638 SAE_J1922 "Identifies the action to be performed on the SAE J1922 communications port.";
CM_ SG_ 2564816638 J1939Network1 "Identifies the action to be performed on the SAE J1939 Network #1, Primary vehicle communications port.";
CM_ BO_ 2566837502 "Emissions-related active diagnostic trouble codes.";
CM_ SG_ 2566837502 FlashRedStopLamp "This parameter provides the capability to flash the RSL (SPN 3039).";
CM_ SG_ 2566837502 FlashProtectLamp "This parameter provides the capability to flash the engine protect lamp (SPN 3041).";
CM_ SG_ 2566837502 MalfunctionIndicatorLampStatus "A lamp used to relay only emissions-related trouble code information.";
CM_ SG_ 2566837502 RedStopLampState "This lamp is uesed to relay trouble code information that is of a severe enought condition that it warrants stopping the vehicle.";
CM_ SG_ 2566837502 AmberWarningLampStatus "This lamp is used to relay trouble code information that is reporting a problem with the vehicle system but the vehicle need
not be immediately stopped.";
CM_ SG_ 2566837502 ProtectLampStatus "This lamp is used to relay trouble code informatio that is reporting a problem with a vehicle system that is most
probably not electronic subsystem related.";
CM_ SG_ 2566837502 FlashMalfuncIndicatorLamp "This parameter provides the capability to flash the MIL (SPN 3038).";
CM_ SG_ 2566837502 FlashAmberWarningLamp "This parameter provides the capability to flash the AWL (SPN 3040). ";
CM_ SG_ 2566837502 DTC5 "Diagnostic Trouble Code";
CM_ SG_ 2566837502 DTC4 "Diagnostic Trouble Code";
CM_ SG_ 2566837502 DTC3 "Diagnostic Trouble Code";
CM_ SG_ 2566837502 DTC2 "Diagnostic Trouble Code";
CM_ SG_ 2566837502 DTC1 "Diagnostic Trouble Code";
CM_ BO_ 2566837246 "Diagnostic data clear/Reset for active DTCs";
CM_ BO_ 2566836990 "Non-continously monitored systems test identifiers support";
CM_ SG_ 2566836990 TestIdentifierSupported "Indicates the test identifiers that the controller supports.";
CM_ BO_ 2566834942 "Active diagnostic trouble codes";
CM_ SG_ 2566834942 FlashRedStopLamp "This parameter provides the capability to flash the RSL (SPN 3039).";
CM_ SG_ 2566834942 FlashProtectLamp "This parameter provides the capability to flash the engine protect lamp (SPN 3041).";
CM_ SG_ 2566834942 FlashMalfuncIndicatorLamp "This parameter provides the capability to flash the MIL (SPN 3038).";
CM_ SG_ 2566834942 FlashAmberWarningLamp "This parameter provides the capability to flash the AWL (SPN 3040). ";
CM_ SG_ 2566834942 MalfunctionIndicatorLampStatus "A lamp used to relay only emissions-related trouble code information.";
CM_ SG_ 2566834942 AmberWarningLampStatus "This lamp is used to relay trouble code information that is reporting a problem with the vehicle system but the vehicle need
not be immediately stopped.";
CM_ SG_ 2566834942 RedStopLampState "This lamp is uesed to relay trouble code information that is of a severe enought condition that it warrants stopping the vehicle.";
CM_ SG_ 2566834942 ProtectLampStatus "This lamp is used to relay trouble code informatio that is reporting a problem with a vehicle system that is most
probably not electronic subsystem related.";
CM_ SG_ 2566834942 DTC5 "Diagnostic Trouble Code";
CM_ SG_ 2566834942 DTC4 "Diagnostic Trouble Code";
CM_ SG_ 2566834942 DTC3 "Diagnostic Trouble Code";
CM_ SG_ 2566834942 DTC2 "Diagnostic Trouble Code";
CM_ SG_ 2566834942 DTC1 "Diagnostic Trouble Code";
CM_ BO_ 2566838526 "Commanded Address";
CM_ SG_ 2566838526 AddressAssignment "The source address that is to be assigned to the CA that has the NAME corresponding to the one conveyed in the first eight bytes of this Commanded Address message.";
CM_ SG_ 2566838526 IndustryGroup "0 = Global; 
   1  = On-Highway; 
   2  = Agricultural and Forestry; 
   3  = Construction; 
   4  = Marine;
   5  = Industrial - Process
          Control - Stationary (Gen-Sets)
   6  = Reserve for SAE
   7  = Reserve for SAE";
CM_ SG_ 2566838526 ManufacturerCode "Assigned by NMEA 2000 Committee";
CM_ BO_ 2632711934 "Transport Protocol - Data Transfer";
CM_ BO_ 2632777470 "Transport Protocol - Connection Management";
CM_ SG_ 2632777470 TotalNumberOfPacketsEoMA "Total number of packets for BAM message.Total number of packets received for RTS/CTS message.Total number of packets for RTS/CTS message.";
CM_ SG_ 2632777470 TotalMessageSizeEoMA "Total message size (in bytes) for BAM message.Total message size (in bytes) for RTS/CTS message.Total message size (in bytes) for RTS/CTS message.";
CM_ SG_ 2632777470 TotalMessageSizeBAM "Total message size (in bytes) for BAM message.Total message size (in bytes) for RTS/CTS message.Total message size (in bytes) for RTS/CTS message.";
CM_ SG_ 2632777470 TotalNumberOfPacketsBAM "Total number of packets for BAM message.Total number of packets received for RTS/CTS message.Total number of packets for RTS/CTS message.";
CM_ SG_ 2632777470 ConnectionAbortReason "Reason for connection abort message.";
CM_ SG_ 2632777470 NextPacketNumberToBeSent "Next Packet Number to be sent (TP.CM_CTS)";
CM_ SG_ 2632777470 NumberOfPacketsThatCanBeSent "Number of Packets that can be sent (TP.CM_CTS)";
CM_ SG_ 2632777470 MaximumNumberOfPackets "Maximum number of packets for RTS/CTS message.";
CM_ SG_ 2632777470 TotalNumberOfPackets "Total number of packets for BAM message.Total number of packets received for RTS/CTS message.Total number of packets for RTS/CTS message.";
CM_ SG_ 2632777470 TotalMessageSize "Total message size (in bytes) for BAM message.Total message size (in bytes) for RTS/CTS message.Total message size (in bytes) for RTS/CTS message.";
CM_ BO_ 2565537534 "Request";
CM_ SG_ 2565537534 ParameterGroupNumber "PGN which is requested by Request2 message";
CM_ BO_ 2566739198 "Class C, Previously Active";
CM_ SG_ 2566739198 FlashRedStopLamp "This parameter provides the capability to flash the RSL (SPN 3039).";
CM_ SG_ 2566739198 FlashProtectLamp "This parameter provides the capability to flash the engine protect lamp (SPN 3041).";
CM_ SG_ 2566739198 FlashMalfuncIndicatorLamp "This parameter provides the capability to flash the MIL (SPN 3038).";
CM_ SG_ 2566739198 FlashAmberWarningLamp "This parameter provides the capability to flash the AWL (SPN 3040). ";
CM_ SG_ 2566739198 MalfunctionIndicatorLampStatus "A lamp used to relay only emissions-related trouble code information.";
CM_ SG_ 2566739198 AmberWarningLampStatus "This lamp is used to relay trouble code information that is reporting a problem with the vehicle system but the vehicle need
not be immediately stopped.";
CM_ SG_ 2566739198 RedStopLampState "This lamp is uesed to relay trouble code information that is of a severe enought condition that it warrants stopping the vehicle.";
CM_ SG_ 2566739198 ProtectLampStatus "This lamp is used to relay trouble code informatio that is reporting a problem with a vehicle system that is most
probably not electronic subsystem related.";
CM_ SG_ 2566739198 DTC5 "Diagnostic Trouble Code";
CM_ SG_ 2566739198 DTC4 "Diagnostic Trouble Code";
CM_ SG_ 2566739198 DTC3 "Diagnostic Trouble Code";
CM_ SG_ 2566739198 DTC2 "Diagnostic Trouble Code";
CM_ SG_ 2566739198 DTC1 "Diagnostic Trouble Code";
CM_ BO_ 2566739454 "Class C, Confirmed and Active";
CM_ SG_ 2566739454 FlashRedStopLamp "This parameter provides the capability to flash the RSL (SPN 3039).";
CM_ SG_ 2566739454 FlashProtectLamp "This parameter provides the capability to flash the engine protect lamp (SPN 3041).";
CM_ SG_ 2566739454 FlashMalfuncIndicatorLamp "This parameter provides the capability to flash the MIL (SPN 3038).";
CM_ SG_ 2566739454 FlashAmberWarningLamp "This parameter provides the capability to flash the AWL (SPN 3040). ";
CM_ SG_ 2566739454 MalfunctionIndicatorLampStatus "A lamp used to relay only emissions-related trouble code information.";
CM_ SG_ 2566739454 AmberWarningLampStatus "This lamp is used to relay trouble code information that is reporting a problem with the vehicle system but the vehicle need
not be immediately stopped.";
CM_ SG_ 2566739454 RedStopLampState "This lamp is uesed to relay trouble code information that is of a severe enought condition that it warrants stopping the vehicle.";
CM_ SG_ 2566739454 ProtectLampStatus "This lamp is used to relay trouble code informatio that is reporting a problem with a vehicle system that is most
probably not electronic subsystem related.";
CM_ SG_ 2566739454 DTC5 "Diagnostic Trouble Code";
CM_ SG_ 2566739454 DTC4 "Diagnostic Trouble Code";
CM_ SG_ 2566739454 DTC3 "Diagnostic Trouble Code";
CM_ SG_ 2566739454 DTC2 "Diagnostic Trouble Code";
CM_ SG_ 2566739454 DTC1 "Diagnostic Trouble Code";
CM_ BO_ 2566739710 "Class C, Pending";
CM_ SG_ 2566739710 FlashRedStopLamp "This parameter provides the capability to flash the RSL (SPN 3039).";
CM_ SG_ 2566739710 FlashProtectLamp "This parameter provides the capability to flash the engine protect lamp (SPN 3041).";
CM_ SG_ 2566739710 FlashMalfuncIndicatorLamp "This parameter provides the capability to flash the MIL (SPN 3038).";
CM_ SG_ 2566739710 FlashAmberWarningLamp "This parameter provides the capability to flash the AWL (SPN 3040). ";
CM_ SG_ 2566739710 MalfunctionIndicatorLampStatus "A lamp used to relay only emissions-related trouble code information.";
CM_ SG_ 2566739710 AmberWarningLampStatus "This lamp is used to relay trouble code information that is reporting a problem with the vehicle system but the vehicle need
not be immediately stopped.";
CM_ SG_ 2566739710 RedStopLampState "This lamp is uesed to relay trouble code information that is of a severe enought condition that it warrants stopping the vehicle.";
CM_ SG_ 2566739710 ProtectLampStatus "This lamp is used to relay trouble code informatio that is reporting a problem with a vehicle system that is most
probably not electronic subsystem related.";
CM_ SG_ 2566739710 DTC5 "Diagnostic Trouble Code";
CM_ SG_ 2566739710 DTC4 "Diagnostic Trouble Code";
CM_ SG_ 2566739710 DTC3 "Diagnostic Trouble Code";
CM_ SG_ 2566739710 DTC2 "Diagnostic Trouble Code";
CM_ SG_ 2566739710 DTC1 "Diagnostic Trouble Code";
CM_ BO_ 2566739966 "Class B2, Previously Active";
CM_ SG_ 2566739966 FlashRedStopLamp "This parameter provides the capability to flash the RSL (SPN 3039).";
CM_ SG_ 2566739966 FlashProtectLamp "This parameter provides the capability to flash the engine protect lamp (SPN 3041).";
CM_ SG_ 2566739966 FlashMalfuncIndicatorLamp "This parameter provides the capability to flash the MIL (SPN 3038).";
CM_ SG_ 2566739966 FlashAmberWarningLamp "This parameter provides the capability to flash the AWL (SPN 3040). ";
CM_ SG_ 2566739966 MalfunctionIndicatorLampStatus "A lamp used to relay only emissions-related trouble code information.";
CM_ SG_ 2566739966 AmberWarningLampStatus "This lamp is used to relay trouble code information that is reporting a problem with the vehicle system but the vehicle need
not be immediately stopped.";
CM_ SG_ 2566739966 RedStopLampState "This lamp is uesed to relay trouble code information that is of a severe enought condition that it warrants stopping the vehicle.";
CM_ SG_ 2566739966 ProtectLampStatus "This lamp is used to relay trouble code informatio that is reporting a problem with a vehicle system that is most
probably not electronic subsystem related.";
CM_ SG_ 2566739966 DTC5 "Diagnostic Trouble Code";
CM_ SG_ 2566739966 DTC4 "Diagnostic Trouble Code";
CM_ SG_ 2566739966 DTC3 "Diagnostic Trouble Code";
CM_ SG_ 2566739966 DTC2 "Diagnostic Trouble Code";
CM_ SG_ 2566739966 DTC1 "Diagnostic Trouble Code";
CM_ BO_ 2566740222 "Class B2, Confirmed and Active";
CM_ SG_ 2566740222 FlashRedStopLamp "This parameter provides the capability to flash the RSL (SPN 3039).";
CM_ SG_ 2566740222 FlashProtectLamp "This parameter provides the capability to flash the engine protect lamp (SPN 3041).";
CM_ SG_ 2566740222 FlashMalfuncIndicatorLamp "This parameter provides the capability to flash the MIL (SPN 3038).";
CM_ SG_ 2566740222 FlashAmberWarningLamp "This parameter provides the capability to flash the AWL (SPN 3040). ";
CM_ SG_ 2566740222 MalfunctionIndicatorLampStatus "A lamp used to relay only emissions-related trouble code information.";
CM_ SG_ 2566740222 AmberWarningLampStatus "This lamp is used to relay trouble code information that is reporting a problem with the vehicle system but the vehicle need
not be immediately stopped.";
CM_ SG_ 2566740222 RedStopLampState "This lamp is uesed to relay trouble code information that is of a severe enought condition that it warrants stopping the vehicle.";
CM_ SG_ 2566740222 ProtectLampStatus "This lamp is used to relay trouble code informatio that is reporting a problem with a vehicle system that is most
probably not electronic subsystem related.";
CM_ SG_ 2566740222 DTC5 "Diagnostic Trouble Code";
CM_ SG_ 2566740222 DTC4 "Diagnostic Trouble Code";
CM_ SG_ 2566740222 DTC3 "Diagnostic Trouble Code";
CM_ SG_ 2566740222 DTC2 "Diagnostic Trouble Code";
CM_ SG_ 2566740222 DTC1 "Diagnostic Trouble Code";
CM_ BO_ 2566740478 "Class B2, Pending";
CM_ SG_ 2566740478 FlashRedStopLamp "This parameter provides the capability to flash the RSL (SPN 3039).";
CM_ SG_ 2566740478 FlashProtectLamp "This parameter provides the capability to flash the engine protect lamp (SPN 3041).";
CM_ SG_ 2566740478 FlashMalfuncIndicatorLamp "This parameter provides the capability to flash the MIL (SPN 3038).";
CM_ SG_ 2566740478 FlashAmberWarningLamp "This parameter provides the capability to flash the AWL (SPN 3040). ";
CM_ SG_ 2566740478 MalfunctionIndicatorLampStatus "A lamp used to relay only emissions-related trouble code information.";
CM_ SG_ 2566740478 AmberWarningLampStatus "This lamp is used to relay trouble code information that is reporting a problem with the vehicle system but the vehicle need
not be immediately stopped.";
CM_ SG_ 2566740478 RedStopLampState "This lamp is uesed to relay trouble code information that is of a severe enought condition that it warrants stopping the vehicle.";
CM_ SG_ 2566740478 ProtectLampStatus "This lamp is used to relay trouble code informatio that is reporting a problem with a vehicle system that is most
probably not electronic subsystem related.";
CM_ SG_ 2566740478 DTC5 "Diagnostic Trouble Code";
CM_ SG_ 2566740478 DTC4 "Diagnostic Trouble Code";
CM_ SG_ 2566740478 DTC3 "Diagnostic Trouble Code";
CM_ SG_ 2566740478 DTC2 "Diagnostic Trouble Code";
CM_ SG_ 2566740478 DTC1 "Diagnostic Trouble Code";
CM_ BO_ 2566740734 "Class B1, Previously Active";
CM_ SG_ 2566740734 FlashRedStopLamp "This parameter provides the capability to flash the RSL (SPN 3039).";
CM_ SG_ 2566740734 FlashProtectLamp "This parameter provides the capability to flash the engine protect lamp (SPN 3041).";
CM_ SG_ 2566740734 FlashMalfuncIndicatorLamp "This parameter provides the capability to flash the MIL (SPN 3038).";
CM_ SG_ 2566740734 FlashAmberWarningLamp "This parameter provides the capability to flash the AWL (SPN 3040). ";
CM_ SG_ 2566740734 MalfunctionIndicatorLampStatus "A lamp used to relay only emissions-related trouble code information.";
CM_ SG_ 2566740734 AmberWarningLampStatus "This lamp is used to relay trouble code information that is reporting a problem with the vehicle system but the vehicle need
not be immediately stopped.";
CM_ SG_ 2566740734 RedStopLampState "This lamp is uesed to relay trouble code information that is of a severe enought condition that it warrants stopping the vehicle.";
CM_ SG_ 2566740734 ProtectLampStatus "This lamp is used to relay trouble code informatio that is reporting a problem with a vehicle system that is most
probably not electronic subsystem related.";
CM_ SG_ 2566740734 DTC5 "Diagnostic Trouble Code";
CM_ SG_ 2566740734 DTC4 "Diagnostic Trouble Code";
CM_ SG_ 2566740734 DTC3 "Diagnostic Trouble Code";
CM_ SG_ 2566740734 DTC2 "Diagnostic Trouble Code";
CM_ SG_ 2566740734 DTC1 "Diagnostic Trouble Code";
CM_ BO_ 2566740990 "Class B1, Confirmed and Active";
CM_ SG_ 2566740990 FlashRedStopLamp "This parameter provides the capability to flash the RSL (SPN 3039).";
CM_ SG_ 2566740990 FlashProtectLamp "This parameter provides the capability to flash the engine protect lamp (SPN 3041).";
CM_ SG_ 2566740990 FlashMalfuncIndicatorLamp "This parameter provides the capability to flash the MIL (SPN 3038).";
CM_ SG_ 2566740990 FlashAmberWarningLamp "This parameter provides the capability to flash the AWL (SPN 3040). ";
CM_ SG_ 2566740990 MalfunctionIndicatorLampStatus "A lamp used to relay only emissions-related trouble code information.";
CM_ SG_ 2566740990 AmberWarningLampStatus "This lamp is used to relay trouble code information that is reporting a problem with the vehicle system but the vehicle need
not be immediately stopped.";
CM_ SG_ 2566740990 RedStopLampState "This lamp is uesed to relay trouble code information that is of a severe enought condition that it warrants stopping the vehicle.";
CM_ SG_ 2566740990 ProtectLampStatus "This lamp is used to relay trouble code informatio that is reporting a problem with a vehicle system that is most
probably not electronic subsystem related.";
CM_ SG_ 2566740990 DTC5 "Diagnostic Trouble Code";
CM_ SG_ 2566740990 DTC4 "Diagnostic Trouble Code";
CM_ SG_ 2566740990 DTC3 "Diagnostic Trouble Code";
CM_ SG_ 2566740990 DTC2 "Diagnostic Trouble Code";
CM_ SG_ 2566740990 DTC1 "Diagnostic Trouble Code";
CM_ BO_ 2566741246 "Class B1, Pending";
CM_ SG_ 2566741246 FlashRedStopLamp "This parameter provides the capability to flash the RSL (SPN 3039).";
CM_ SG_ 2566741246 FlashProtectLamp "This parameter provides the capability to flash the engine protect lamp (SPN 3041).";
CM_ SG_ 2566741246 FlashMalfuncIndicatorLamp "This parameter provides the capability to flash the MIL (SPN 3038).";
CM_ SG_ 2566741246 FlashAmberWarningLamp "This parameter provides the capability to flash the AWL (SPN 3040). ";
CM_ SG_ 2566741246 MalfunctionIndicatorLampStatus "A lamp used to relay only emissions-related trouble code information.";
CM_ SG_ 2566741246 AmberWarningLampStatus "This lamp is used to relay trouble code information that is reporting a problem with the vehicle system but the vehicle need
not be immediately stopped.";
CM_ SG_ 2566741246 RedStopLampState "This lamp is uesed to relay trouble code information that is of a severe enought condition that it warrants stopping the vehicle.";
CM_ SG_ 2566741246 ProtectLampStatus "This lamp is used to relay trouble code informatio that is reporting a problem with a vehicle system that is most
probably not electronic subsystem related.";
CM_ SG_ 2566741246 DTC5 "Diagnostic Trouble Code";
CM_ SG_ 2566741246 DTC4 "Diagnostic Trouble Code";
CM_ SG_ 2566741246 DTC3 "Diagnostic Trouble Code";
CM_ SG_ 2566741246 DTC2 "Diagnostic Trouble Code";
CM_ SG_ 2566741246 DTC1 "Diagnostic Trouble Code";
CM_ BO_ 2566741502 "Class A, Previously Active";
CM_ SG_ 2566741502 FlashRedStopLamp "This parameter provides the capability to flash the RSL (SPN 3039).";
CM_ SG_ 2566741502 FlashProtectLamp "This parameter provides the capability to flash the engine protect lamp (SPN 3041).";
CM_ SG_ 2566741502 FlashMalfuncIndicatorLamp "This parameter provides the capability to flash the MIL (SPN 3038).";
CM_ SG_ 2566741502 FlashAmberWarningLamp "This parameter provides the capability to flash the AWL (SPN 3040). ";
CM_ SG_ 2566741502 MalfunctionIndicatorLampStatus "A lamp used to relay only emissions-related trouble code information.";
CM_ SG_ 2566741502 AmberWarningLampStatus "This lamp is used to relay trouble code information that is reporting a problem with the vehicle system but the vehicle need
not be immediately stopped.";
CM_ SG_ 2566741502 RedStopLampState "This lamp is uesed to relay trouble code information that is of a severe enought condition that it warrants stopping the vehicle.";
CM_ SG_ 2566741502 ProtectLampStatus "This lamp is used to relay trouble code informatio that is reporting a problem with a vehicle system that is most
probably not electronic subsystem related.";
CM_ SG_ 2566741502 DTC5 "Diagnostic Trouble Code";
CM_ SG_ 2566741502 DTC4 "Diagnostic Trouble Code";
CM_ SG_ 2566741502 DTC3 "Diagnostic Trouble Code";
CM_ SG_ 2566741502 DTC2 "Diagnostic Trouble Code";
CM_ SG_ 2566741502 DTC1 "Diagnostic Trouble Code";
CM_ BO_ 2566741758 "Class A, Confirmed and Active";
CM_ SG_ 2566741758 FlashRedStopLamp "This parameter provides the capability to flash the RSL (SPN 3039).";
CM_ SG_ 2566741758 FlashProtectLamp "This parameter provides the capability to flash the engine protect lamp (SPN 3041).";
CM_ SG_ 2566741758 FlashMalfuncIndicatorLamp "This parameter provides the capability to flash the MIL (SPN 3038).";
CM_ SG_ 2566741758 FlashAmberWarningLamp "This parameter provides the capability to flash the AWL (SPN 3040). ";
CM_ SG_ 2566741758 MalfunctionIndicatorLampStatus "A lamp used to relay only emissions-related trouble code information.";
CM_ SG_ 2566741758 AmberWarningLampStatus "This lamp is used to relay trouble code information that is reporting a problem with the vehicle system but the vehicle need
not be immediately stopped.";
CM_ SG_ 2566741758 RedStopLampState "This lamp is uesed to relay trouble code information that is of a severe enought condition that it warrants stopping the vehicle.";
CM_ SG_ 2566741758 ProtectLampStatus "This lamp is used to relay trouble code informatio that is reporting a problem with a vehicle system that is most
probably not electronic subsystem related.";
CM_ SG_ 2566741758 DTC5 "Diagnostic Trouble Code";
CM_ SG_ 2566741758 DTC4 "Diagnostic Trouble Code";
CM_ SG_ 2566741758 DTC3 "Diagnostic Trouble Code";
CM_ SG_ 2566741758 DTC2 "Diagnostic Trouble Code";
CM_ SG_ 2566741758 DTC1 "Diagnostic Trouble Code";
CM_ BO_ 2566742014 "Class A, Pending";
CM_ SG_ 2566742014 FlashRedStopLamp "This parameter provides the capability to flash the RSL (SPN 3039).";
CM_ SG_ 2566742014 FlashProtectLamp "This parameter provides the capability to flash the engine protect lamp (SPN 3041).";
CM_ SG_ 2566742014 FlashMalfuncIndicatorLamp "This parameter provides the capability to flash the MIL (SPN 3038).";
CM_ SG_ 2566742014 FlashAmberWarningLamp "This parameter provides the capability to flash the AWL (SPN 3040). ";
CM_ SG_ 2566742014 MalfunctionIndicatorLampStatus "A lamp used to relay only emissions-related trouble code information.";
CM_ SG_ 2566742014 AmberWarningLampStatus "This lamp is used to relay trouble code information that is reporting a problem with the vehicle system but the vehicle need
not be immediately stopped.";
CM_ SG_ 2566742014 RedStopLampState "This lamp is uesed to relay trouble code information that is of a severe enought condition that it warrants stopping the vehicle.";
CM_ SG_ 2566742014 ProtectLampStatus "This lamp is used to relay trouble code informatio that is reporting a problem with a vehicle system that is most
probably not electronic subsystem related.";
CM_ SG_ 2566742014 DTC5 "Diagnostic Trouble Code";
CM_ SG_ 2566742014 DTC4 "Diagnostic Trouble Code";
CM_ SG_ 2566742014 DTC3 "Diagnostic Trouble Code";
CM_ SG_ 2566742014 DTC2 "Diagnostic Trouble Code";
CM_ SG_ 2566742014 DTC1 "Diagnostic Trouble Code";
CM_ BO_ 2560622334 "Immediate Fault Status ";
CM_ SG_ 2560622334 FlashRedStopLamp "This parameter provides the capability to flash the RSL (SPN 3039).";
CM_ SG_ 2560622334 FlashProtectLamp "This parameter provides the capability to flash the engine protect lamp (SPN 3041).";
CM_ SG_ 2560622334 FlashMalfuncIndicatorLamp "This parameter provides the capability to flash the MIL (SPN 3038).";
CM_ SG_ 2560622334 FlashAmberWarningLamp "This parameter provides the capability to flash the AWL (SPN 3040). ";
CM_ SG_ 2560622334 MalfunctionIndicatorLampStatus "A lamp used to relay only emissions-related trouble code information.";
CM_ SG_ 2560622334 AmberWarningLampStatus "This lamp is used to relay trouble code information that is reporting a problem with the vehicle system but the vehicle need
not be immediately stopped.";
CM_ SG_ 2560622334 RedStopLampState "This lamp is uesed to relay trouble code information that is of a severe enought condition that it warrants stopping the vehicle.";
CM_ SG_ 2560622334 ProtectLampStatus "This lamp is used to relay trouble code informatio that is reporting a problem with a vehicle system that is most
probably not electronic subsystem related.";
CM_ SG_ 2560622334 DTC5 "Diagnostic Trouble Code";
CM_ SG_ 2560622334 DTC4 "Diagnostic Trouble Code";
CM_ SG_ 2560622334 DTC3 "Diagnostic Trouble Code";
CM_ SG_ 2560622334 DTC2 "Diagnostic Trouble Code";
CM_ SG_ 2560622334 DTC1 "Diagnostic Trouble Code";
CM_ BO_ 2560556798 "DTC Counts";
CM_ SG_ 2560556798 PermanentDTCs "Identifies the current number of permanent DTCs";
CM_ SG_ 2560556798 PreviouslyMILOnDTCs "Identifies the current number of previously MIL-On DTCs";
CM_ SG_ 2560556798 MILOnDTCs "Identifies the current number of MIL-On DTCs";
CM_ SG_ 2560556798 AllPendingDTCs "Identifies the current total number of pending DTCs, including emission related";
CM_ SG_ 2560556798 PendingDTCs "Identifies the current number of emission related pending DTCs";
CM_ BO_ 2566750462 "Permanent DTCs";
CM_ SG_ 2566750462 FlashRedStopLamp "This parameter provides the capability to flash the RSL (SPN 3039).";
CM_ SG_ 2566750462 FlashProtectLamp "This parameter provides the capability to flash the engine protect lamp (SPN 3041).";
CM_ SG_ 2566750462 FlashMalfuncIndicatorLamp "This parameter provides the capability to flash the MIL (SPN 3038).";
CM_ SG_ 2566750462 FlashAmberWarningLamp "This parameter provides the capability to flash the AWL (SPN 3040). ";
CM_ SG_ 2566750462 MalfunctionIndicatorLampStatus "A lamp used to relay only emissions-related trouble code information.";
CM_ SG_ 2566750462 AmberWarningLampStatus "This lamp is used to relay trouble code information that is reporting a problem with the vehicle system but the vehicle need
not be immediately stopped.";
CM_ SG_ 2566750462 RedStopLampState "This lamp is uesed to relay trouble code information that is of a severe enought condition that it warrants stopping the vehicle.";
CM_ SG_ 2566750462 ProtectLampStatus "This lamp is used to relay trouble code informatio that is reporting a problem with a vehicle system that is most
probably not electronic subsystem related.";
CM_ SG_ 2566750462 DTC5 "Diagnostic Trouble Code";
CM_ SG_ 2566750462 DTC4 "Diagnostic Trouble Code";
CM_ SG_ 2566750462 DTC3 "Diagnostic Trouble Code";
CM_ SG_ 2566750462 DTC2 "Diagnostic Trouble Code";
CM_ SG_ 2566750462 DTC1 "Diagnostic Trouble Code";
CM_ BO_ 2566750974 "All Pending DTCs";
CM_ SG_ 2566750974 FlashRedStopLamp "This parameter provides the capability to flash the RSL (SPN 3039).";
CM_ SG_ 2566750974 FlashProtectLamp "This parameter provides the capability to flash the engine protect lamp (SPN 3041).";
CM_ SG_ 2566750974 FlashMalfuncIndicatorLamp "This parameter provides the capability to flash the MIL (SPN 3038).";
CM_ SG_ 2566750974 FlashAmberWarningLamp "This parameter provides the capability to flash the AWL (SPN 3040). ";
CM_ SG_ 2566750974 MalfunctionIndicatorLampStatus "A lamp used to relay only emissions-related trouble code information.";
CM_ SG_ 2566750974 AmberWarningLampStatus "This lamp is used to relay trouble code information that is reporting a problem with the vehicle system but the vehicle need
not be immediately stopped.";
CM_ SG_ 2566750974 RedStopLampState "This lamp is uesed to relay trouble code information that is of a severe enought condition that it warrants stopping the vehicle.";
CM_ SG_ 2566750974 ProtectLampStatus "This lamp is used to relay trouble code informatio that is reporting a problem with a vehicle system that is most
probably not electronic subsystem related.";
CM_ SG_ 2566750974 DTC5 "Diagnostic Trouble Code";
CM_ SG_ 2566750974 DTC4 "Diagnostic Trouble Code";
CM_ SG_ 2566750974 DTC3 "Diagnostic Trouble Code";
CM_ SG_ 2566750974 DTC2 "Diagnostic Trouble Code";
CM_ SG_ 2566750974 DTC1 "Diagnostic Trouble Code";
BA_DEF_ SG_  "SigType" ENUM  "Default","Range","RangeSigned","ASCII","Discrete","Control","ReferencePGN","DTC","StringDelimiter","StringLength","StringLengthControl";
BA_DEF_ SG_  "GenSigStartValue" INT 0 10000;
BA_DEF_ SG_  "GenSigSendType" ENUM  "Cyclic","OnWrite","reserved","OnChange","reserved","reserved","reserved","NoSigSendType";
BA_DEF_ SG_  "GenSigILSupport" ENUM  "Yes","No";
BA_DEF_ SG_  "GenSigEVName" STRING ;
BA_DEF_ SG_  "SPN" INT 0 524287;
BA_DEF_ SG_  "SAEDocument" STRING ;
BA_DEF_ BO_  "GenMsgILSupport" ENUM  "Yes","No";
BA_DEF_ BO_  "GenMsgRequestable" INT 0 1;
BA_DEF_ BO_  "GenMsgSendType" ENUM  "cyclic","reserved","cyclicIfActive","reserved","reserved","reserved","reserved","reserved","noMsgSendType";
BA_DEF_ BO_  "VFrameFormat" ENUM  "StandardCAN","ExtendedCAN","reserved","J1939PG";
BA_DEF_ BO_  "SingleFrame" INT 0 1;
BA_DEF_ BO_  "SAE_Document" STRING ;
BA_DEF_ SG_  "SystemSignalLongSymbol" STRING ;
BA_DEF_DEF_  "SigType" "Default";
BA_DEF_DEF_  "GenSigStartValue" 0;
BA_DEF_DEF_  "GenSigSendType" "NoSigSendType";
BA_DEF_DEF_  "GenSigILSupport" "Yes";
BA_DEF_DEF_  "GenSigEVName" "Env@Nodename_@Signame";
BA_DEF_DEF_  "SPN" 0;
BA_DEF_DEF_  "SAEDocument" "";
BA_DEF_DEF_  "GenMsgILSupport" "Yes";
BA_DEF_DEF_  "GenMsgRequestable" 1;
BA_DEF_DEF_  "GenMsgSendType" "noMsgSendType";
BA_DEF_DEF_  "VFrameFormat" "J1939PG";
BA_DEF_DEF_  "SingleFrame" 1;
BA_DEF_DEF_  "SAE_Document" "";
BA_DEF_DEF_  "SystemSignalLongSymbol" "";
BA_ "SAE_Document" BO_ 2566764030 "J1939-73";
BA_ "SAE_Document" BO_ 2562981630 "J1939-73";
BA_ "SAE_Document" BO_ 2562850558 "J1939-73";
BA_ "SAE_Document" BO_ 2562916094 "J1939-73";
BA_ "SAE_Document" BO_ 2566835198 "J1939-73";
BA_ "SAE_Document" BO_ 2564030206 "J1939-73";
BA_ "SAE_Document" BO_ 2564226814 "J1939-73";
BA_ "SAE_Document" BO_ 2564292350 "J1939-73";
BA_ "SAE_Document" BO_ 2564357886 "J1939-73";
BA_ "SAE_Document" BO_ 2564423422 "J1939-73";
BA_ "SAE_Document" BO_ 2564816638 "J1939-73";
BA_ "SAE_Document" BO_ 2566837502 "J1939-73";
BA_ "SAE_Document" BO_ 2566837246 "J1939-73";
BA_ "SAE_Document" BO_ 2566836990 "J1939-73";
BA_ "SAE_Document" BO_ 2566834942 "J1939-73";
BA_ "SAE_Document" BO_ 2566838526 "J1939-81";
BA_ "SAE_Document" BO_ 2632711934 "J1939-21";
BA_ "SAE_Document" BO_ 2632777470 "J1939-21";
BA_ "SAE_Document" BO_ 2565537534 "J1939-21";
BA_ "SAE_Document" BO_ 2566739198 "J1939-73";
BA_ "SAE_Document" BO_ 2566739454 "J1939-73";
BA_ "SAE_Document" BO_ 2566739710 "J1939-73";
BA_ "SAE_Document" BO_ 2566739966 "J1939-73";
BA_ "SAE_Document" BO_ 2566740222 "J1939-73";
BA_ "SAE_Document" BO_ 2566740478 "J1939-73";
BA_ "SAE_Document" BO_ 2566740734 "J1939-73";
BA_ "SAE_Document" BO_ 2566740990 "J1939-73";
BA_ "SAE_Document" BO_ 2566741246 "J1939-73";
BA_ "SAE_Document" BO_ 2566741502 "J1939-73";
BA_ "SAE_Document" BO_ 2566741758 "J1939-73";
BA_ "SAE_Document" BO_ 2566742014 "J1939-73";
BA_ "SAE_Document" BO_ 2560622334 "J1939-73";
BA_ "SAE_Document" BO_ 2560556798 "J1939-73";
BA_ "SAE_Document" BO_ 2566750462 "J1939-73";
BA_ "SAE_Document" BO_ 2566750974 "J1939-73";
BA_ "SigType" SG_ 2566764030 FlashRedStopLamp 4;
BA_ "SPN" SG_ 2566764030 FlashRedStopLamp 3039;
BA_ "SAEDocument" SG_ 2566764030 FlashRedStopLamp "J1939-73";
BA_ "SigType" SG_ 2566764030 FlashProtectLamp 4;
BA_ "SPN" SG_ 2566764030 FlashProtectLamp 3041;
BA_ "SAEDocument" SG_ 2566764030 FlashProtectLamp "J1939-73";
BA_ "SigType" SG_ 2566764030 FlashMalfuncIndicatorLamp 4;
BA_ "SPN" SG_ 2566764030 FlashMalfuncIndicatorLamp 3038;
BA_ "SAEDocument" SG_ 2566764030 FlashMalfuncIndicatorLamp "J1939-73";
BA_ "SigType" SG_ 2566764030 FlashAmberWarningLamp 4;
BA_ "SPN" SG_ 2566764030 FlashAmberWarningLamp 3040;
BA_ "SAEDocument" SG_ 2566764030 FlashAmberWarningLamp "J1939-73";
BA_ "SigType" SG_ 2566764030 MalfunctionIndicatorLampStatus 4;
BA_ "SPN" SG_ 2566764030 MalfunctionIndicatorLampStatus 1213;
BA_ "SAEDocument" SG_ 2566764030 MalfunctionIndicatorLampStatus "J1939-73";
BA_ "SigType" SG_ 2566764030 RedStopLampState 4;
BA_ "SPN" SG_ 2566764030 RedStopLampState 623;
BA_ "SAEDocument" SG_ 2566764030 RedStopLampState "J1939-73";
BA_ "SigType" SG_ 2566764030 AmberWarningLampStatus 4;
BA_ "SPN" SG_ 2566764030 AmberWarningLampStatus 624;
BA_ "SAEDocument" SG_ 2566764030 AmberWarningLampStatus "J1939-73";
BA_ "SigType" SG_ 2566764030 ProtectLampStatus 4;
BA_ "SPN" SG_ 2566764030 ProtectLampStatus 987;
BA_ "SAEDocument" SG_ 2566764030 ProtectLampStatus "J1939-73";
BA_ "SigType" SG_ 2566764030 DTC5 7;
BA_ "SAEDocument" SG_ 2566764030 DTC5 "J1939-73";
BA_ "SigType" SG_ 2566764030 DTC4 7;
BA_ "SAEDocument" SG_ 2566764030 DTC4 "J1939-73";
BA_ "SigType" SG_ 2566764030 DTC3 7;
BA_ "SAEDocument" SG_ 2566764030 DTC3 "J1939-73";
BA_ "SigType" SG_ 2566764030 DTC2 7;
BA_ "SAEDocument" SG_ 2566764030 DTC2 "J1939-73";
BA_ "SigType" SG_ 2566764030 DTC1 7;
BA_ "SAEDocument" SG_ 2566764030 DTC1 "J1939-73";
BA_ "SPN" SG_ 2562981630 IndividualDTCClearControlByte 3034;
BA_ "SAEDocument" SG_ 2562981630 IndividualDTCClearControlByte "J1939-73";
BA_ "SPN" SG_ 2562981630 CtrlByteIndicIndividualDTCClear 3035;
BA_ "SAEDocument" SG_ 2562981630 CtrlByteIndicIndividualDTCClear "J1939-73";
BA_ "SPN" SG_ 2562981630 SPN1 1214;
BA_ "SAEDocument" SG_ 2562981630 SPN1 "J1939-73";
BA_ "SAEDocument" SG_ 2562981630 SPN1High "J1939-73";
BA_ "SPN" SG_ 2562981630 FailureModeIdentifier1 1215;
BA_ "SAEDocument" SG_ 2562981630 FailureModeIdentifier1 "J1939-73";
BA_ "SigType" SG_ 2562850558 TimeSinceDTCsCleared 1;
BA_ "SPN" SG_ 2562850558 TimeSinceDTCsCleared 3296;
BA_ "SAEDocument" SG_ 2562850558 TimeSinceDTCsCleared "J1939-73";
BA_ "SigType" SG_ 2562850558 MinutesRunByEngineMILActivated 1;
BA_ "SPN" SG_ 2562850558 MinutesRunByEngineMILActivated 3295;
BA_ "SAEDocument" SG_ 2562850558 MinutesRunByEngineMILActivated "J1939-73";
BA_ "SigType" SG_ 2562850558 DistanceSinceDTCsCleared 1;
BA_ "SPN" SG_ 2562850558 DistanceSinceDTCsCleared 3294;
BA_ "SAEDocument" SG_ 2562850558 DistanceSinceDTCsCleared "J1939-73";
BA_ "SigType" SG_ 2562850558 DistanceWhileMILisActivated 1;
BA_ "SPN" SG_ 2562850558 DistanceWhileMILisActivated 3069;
BA_ "SAEDocument" SG_ 2562850558 DistanceWhileMILisActivated "J1939-73";
BA_ "SigType" SG_ 2562916094 ApplSysMonitorDenominator 1;
BA_ "SPN" SG_ 2562916094 ApplSysMonitorDenominator 3068;
BA_ "SAEDocument" SG_ 2562916094 ApplSysMonitorDenominator "J1939-73";
BA_ "SigType" SG_ 2562916094 ApplSysMonitorNumerator 1;
BA_ "SPN" SG_ 2562916094 ApplSysMonitorNumerator 3067;
BA_ "SAEDocument" SG_ 2562916094 ApplSysMonitorNumerator "J1939-73";
BA_ "SigType" SG_ 2562916094 SPNofApplSysMonitor 1;
BA_ "SPN" SG_ 2562916094 SPNofApplSysMonitor 3066;
BA_ "SAEDocument" SG_ 2562916094 SPNofApplSysMonitor "J1939-73";
BA_ "SigType" SG_ 2562916094 OBDMonitoringCondEncountered 1;
BA_ "SPN" SG_ 2562916094 OBDMonitoringCondEncountered 3049;
BA_ "SAEDocument" SG_ 2562916094 OBDMonitoringCondEncountered "J1939-73";
BA_ "SigType" SG_ 2562916094 IgnitionCycleCounter 1;
BA_ "SPN" SG_ 2562916094 IgnitionCycleCounter 3048;
BA_ "SAEDocument" SG_ 2562916094 IgnitionCycleCounter "J1939-73";
BA_ "SigType" SG_ 2566835198 MalfunctionIndicatorLampStatus 4;
BA_ "SPN" SG_ 2566835198 MalfunctionIndicatorLampStatus 1213;
BA_ "SAEDocument" SG_ 2566835198 MalfunctionIndicatorLampStatus "J1939-73";
BA_ "SigType" SG_ 2566835198 RedStopLampState 4;
BA_ "SPN" SG_ 2566835198 RedStopLampState 623;
BA_ "SAEDocument" SG_ 2566835198 RedStopLampState "J1939-73";
BA_ "SigType" SG_ 2566835198 AmberWarningLampStatus 4;
BA_ "SPN" SG_ 2566835198 AmberWarningLampStatus 624;
BA_ "SAEDocument" SG_ 2566835198 AmberWarningLampStatus "J1939-73";
BA_ "SigType" SG_ 2566835198 ProtectLampStatus 4;
BA_ "SPN" SG_ 2566835198 ProtectLampStatus 987;
BA_ "SAEDocument" SG_ 2566835198 ProtectLampStatus "J1939-73";
BA_ "SigType" SG_ 2566835198 FlashRedStopLamp 4;
BA_ "SPN" SG_ 2566835198 FlashRedStopLamp 3039;
BA_ "SAEDocument" SG_ 2566835198 FlashRedStopLamp "J1939-73";
BA_ "SigType" SG_ 2566835198 FlashProtectLamp 4;
BA_ "SPN" SG_ 2566835198 FlashProtectLamp 3041;
BA_ "SAEDocument" SG_ 2566835198 FlashProtectLamp "J1939-73";
BA_ "SigType" SG_ 2566835198 FlashMalfuncIndicatorLamp 4;
BA_ "SPN" SG_ 2566835198 FlashMalfuncIndicatorLamp 3038;
BA_ "SAEDocument" SG_ 2566835198 FlashMalfuncIndicatorLamp "J1939-73";
BA_ "SigType" SG_ 2566835198 FlashAmberWarningLamp 4;
BA_ "SPN" SG_ 2566835198 FlashAmberWarningLamp 3040;
BA_ "SAEDocument" SG_ 2566835198 FlashAmberWarningLamp "J1939-73";
BA_ "SigType" SG_ 2566835198 DTC5 7;
BA_ "SAEDocument" SG_ 2566835198 DTC5 "J1939-73";
BA_ "SigType" SG_ 2566835198 DTC4 7;
BA_ "SAEDocument" SG_ 2566835198 DTC4 "J1939-73";
BA_ "SigType" SG_ 2566835198 DTC3 7;
BA_ "SAEDocument" SG_ 2566835198 DTC3 "J1939-73";
BA_ "SigType" SG_ 2566835198 DTC2 7;
BA_ "SAEDocument" SG_ 2566835198 DTC2 "J1939-73";
BA_ "SigType" SG_ 2566835198 DTC1 7;
BA_ "SAEDocument" SG_ 2566835198 DTC1 "J1939-73";
BA_ "SAEDocument" SG_ 2564030206 CalibrationID4 "J1939-73";
BA_ "SAEDocument" SG_ 2564030206 CalibrationID3 "J1939-73";
BA_ "SAEDocument" SG_ 2564030206 CalibrationID2 "J1939-73";
BA_ "SPN" SG_ 2564030206 CalibrationID1 1635;
BA_ "SAEDocument" SG_ 2564030206 CalibrationID1 "J1939-73";
BA_ "SigType" SG_ 2564030206 CalibrationVerificationNumber 1;
BA_ "SPN" SG_ 2564030206 CalibrationVerificationNumber 1634;
BA_ "SAEDocument" SG_ 2564030206 CalibrationVerificationNumber "J1939-73";
BA_ "SAEDocument" SG_ 2564226814 BootLoadData7 "J1939-73";
BA_ "SAEDocument" SG_ 2564226814 BootLoadData6 "J1939-73";
BA_ "SAEDocument" SG_ 2564226814 BootLoadData5 "J1939-73";
BA_ "SAEDocument" SG_ 2564226814 BootLoadData4 "J1939-73";
BA_ "SAEDocument" SG_ 2564226814 BootLoadData3 "J1939-73";
BA_ "SAEDocument" SG_ 2564226814 BootLoadData2 "J1939-73";
BA_ "SAEDocument" SG_ 2564226814 BootLoadData1 "J1939-73";
BA_ "SAEDocument" SG_ 2564226814 BootLoadData "J1939-73";
BA_ "SAEDocument" SG_ 2564292350 RawBinaryData6 "J1939-73";
BA_ "SAEDocument" SG_ 2564292350 RawBinaryData5 "J1939-73";
BA_ "SAEDocument" SG_ 2564292350 RawBinaryData4 "J1939-73";
BA_ "SAEDocument" SG_ 2564292350 RawBinaryData3 "J1939-73";
BA_ "SAEDocument" SG_ 2564292350 RawBinaryData2 "J1939-73";
BA_ "SAEDocument" SG_ 2564292350 RawBinaryData1 "J1939-73";
BA_ "SAEDocument" SG_ 2564292350 RawBinaryData "J1939-73";
BA_ "SAEDocument" SG_ 2564292350 NumberOfOccurance "J1939-73";
BA_ "SAEDocument" SG_ 2564357886 NumberAllowed "J1939-73";
BA_ "SAEDocument" SG_ 2564357886 Seed "J1939-73";
BA_ "SAEDocument" SG_ 2564357886 EDCP_Extension "J1939-73";
BA_ "SAEDocument" SG_ 2564357886 ErrorIndicator "J1939-73";
BA_ "SAEDocument" SG_ 2564357886 Status "J1939-73";
BA_ "SAEDocument" SG_ 2564357886 NumberAllowedHigh "J1939-73";
BA_ "SPN" SG_ 2564423422 KeyOrUserLevel 1645;
BA_ "SAEDocument" SG_ 2564423422 KeyOrUserLevel "J1939-73";
BA_ "SPN" SG_ 2564423422 PointerExtension 1643;
BA_ "SAEDocument" SG_ 2564423422 PointerExtension "J1939-73";
BA_ "SPN" SG_ 2564423422 Pointer 1644;
BA_ "SAEDocument" SG_ 2564423422 Pointer "J1939-73";
BA_ "SPN" SG_ 2564423422 Command 1642;
BA_ "SAEDocument" SG_ 2564423422 Command "J1939-73";
BA_ "SPN" SG_ 2564423422 PointerType 1641;
BA_ "SAEDocument" SG_ 2564423422 PointerType "J1939-73";
BA_ "SPN" SG_ 2564423422 NumberRequested 1640;
BA_ "SAEDocument" SG_ 2564423422 NumberRequested "J1939-73";
BA_ "SAEDocument" SG_ 2564423422 NumberRequestedHigh "J1939-73";
BA_ "SPN" SG_ 2564816638 HoldSignal 1236;
BA_ "SAEDocument" SG_ 2564816638 HoldSignal "J1939-73";
BA_ "SigType" SG_ 2564816638 J1939Network3 4;
BA_ "SPN" SG_ 2564816638 J1939Network3 1235;
BA_ "SAEDocument" SG_ 2564816638 J1939Network3 "J1939-73";
BA_ "SigType" SG_ 2564816638 J1939Network2 4;
BA_ "SPN" SG_ 2564816638 J1939Network2 1231;
BA_ "SAEDocument" SG_ 2564816638 J1939Network2 "J1939-73";
BA_ "SigType" SG_ 2564816638 ISO9141 4;
BA_ "SPN" SG_ 2564816638 ISO9141 1232;
BA_ "SAEDocument" SG_ 2564816638 ISO9141 "J1939-73";
BA_ "SigType" SG_ 2564816638 SAE_J1850 4;
BA_ "SPN" SG_ 2564816638 SAE_J1850 1233;
BA_ "SAEDocument" SG_ 2564816638 SAE_J1850 "J1939-73";
BA_ "SigType" SG_ 2564816638 ManufacturerSpecificPort 4;
BA_ "SPN" SG_ 2564816638 ManufacturerSpecificPort 1234;
BA_ "SAEDocument" SG_ 2564816638 ManufacturerSpecificPort "J1939-73";
BA_ "SigType" SG_ 2564816638 CurrentDataLink 4;
BA_ "SPN" SG_ 2564816638 CurrentDataLink 1230;
BA_ "SAEDocument" SG_ 2564816638 CurrentDataLink "J1939-73";
BA_ "SigType" SG_ 2564816638 SAE_J1587 4;
BA_ "SPN" SG_ 2564816638 SAE_J1587 608;
BA_ "SAEDocument" SG_ 2564816638 SAE_J1587 "J1939-73";
BA_ "SigType" SG_ 2564816638 SAE_J1922 4;
BA_ "SPN" SG_ 2564816638 SAE_J1922 622;
BA_ "SAEDocument" SG_ 2564816638 SAE_J1922 "J1939-73";
BA_ "SigType" SG_ 2564816638 J1939Network1 4;
BA_ "SPN" SG_ 2564816638 J1939Network1 639;
BA_ "SAEDocument" SG_ 2564816638 J1939Network1 "J1939-73";
BA_ "SPN" SG_ 2564816638 SuspendSignal 2618;
BA_ "SAEDocument" SG_ 2564816638 SuspendSignal "J1939-73";
BA_ "SPN" SG_ 2564816638 SuspendDuration 2619;
BA_ "SAEDocument" SG_ 2564816638 SuspendDuration "J1939-73";
BA_ "SigType" SG_ 2566837502 FlashRedStopLamp 4;
BA_ "SPN" SG_ 2566837502 FlashRedStopLamp 3039;
BA_ "SAEDocument" SG_ 2566837502 FlashRedStopLamp "J1939-73";
BA_ "SigType" SG_ 2566837502 FlashProtectLamp 4;
BA_ "SPN" SG_ 2566837502 FlashProtectLamp 3041;
BA_ "SAEDocument" SG_ 2566837502 FlashProtectLamp "J1939-73";
BA_ "SigType" SG_ 2566837502 MalfunctionIndicatorLampStatus 4;
BA_ "SPN" SG_ 2566837502 MalfunctionIndicatorLampStatus 1213;
BA_ "SAEDocument" SG_ 2566837502 MalfunctionIndicatorLampStatus "J1939-73";
BA_ "SigType" SG_ 2566837502 RedStopLampState 4;
BA_ "SPN" SG_ 2566837502 RedStopLampState 623;
BA_ "SAEDocument" SG_ 2566837502 RedStopLampState "J1939-73";
BA_ "SigType" SG_ 2566837502 AmberWarningLampStatus 4;
BA_ "SPN" SG_ 2566837502 AmberWarningLampStatus 624;
BA_ "SAEDocument" SG_ 2566837502 AmberWarningLampStatus "J1939-73";
BA_ "SigType" SG_ 2566837502 ProtectLampStatus 4;
BA_ "SPN" SG_ 2566837502 ProtectLampStatus 987;
BA_ "SAEDocument" SG_ 2566837502 ProtectLampStatus "J1939-73";
BA_ "SigType" SG_ 2566837502 FlashMalfuncIndicatorLamp 4;
BA_ "SPN" SG_ 2566837502 FlashMalfuncIndicatorLamp 3038;
BA_ "SAEDocument" SG_ 2566837502 FlashMalfuncIndicatorLamp "J1939-73";
BA_ "SigType" SG_ 2566837502 FlashAmberWarningLamp 4;
BA_ "SPN" SG_ 2566837502 FlashAmberWarningLamp 3040;
BA_ "SAEDocument" SG_ 2566837502 FlashAmberWarningLamp "J1939-73";
BA_ "SigType" SG_ 2566837502 DTC5 7;
BA_ "SAEDocument" SG_ 2566837502 DTC5 "J1939-73";
BA_ "SigType" SG_ 2566837502 DTC4 7;
BA_ "SAEDocument" SG_ 2566837502 DTC4 "J1939-73";
BA_ "SigType" SG_ 2566837502 DTC3 7;
BA_ "SAEDocument" SG_ 2566837502 DTC3 "J1939-73";
BA_ "SigType" SG_ 2566837502 DTC2 7;
BA_ "SAEDocument" SG_ 2566837502 DTC2 "J1939-73";
BA_ "SigType" SG_ 2566837502 DTC1 7;
BA_ "SAEDocument" SG_ 2566837502 DTC1 "J1939-73";
BA_ "SigType" SG_ 2566836990 TestIdentifierSupported 1;
BA_ "GenSigStartValue" SG_ 2566836990 TestIdentifierSupported 1;
BA_ "SPN" SG_ 2566836990 TestIdentifierSupported 1229;
BA_ "SAEDocument" SG_ 2566836990 TestIdentifierSupported "J1939-73";
BA_ "SigType" SG_ 2566834942 FlashRedStopLamp 4;
BA_ "SPN" SG_ 2566834942 FlashRedStopLamp 3039;
BA_ "SAEDocument" SG_ 2566834942 FlashRedStopLamp "J1939-73";
BA_ "SigType" SG_ 2566834942 FlashProtectLamp 4;
BA_ "SPN" SG_ 2566834942 FlashProtectLamp 3041;
BA_ "SAEDocument" SG_ 2566834942 FlashProtectLamp "J1939-73";
BA_ "SigType" SG_ 2566834942 FlashMalfuncIndicatorLamp 4;
BA_ "SPN" SG_ 2566834942 FlashMalfuncIndicatorLamp 3038;
BA_ "SAEDocument" SG_ 2566834942 FlashMalfuncIndicatorLamp "J1939-73";
BA_ "SigType" SG_ 2566834942 FlashAmberWarningLamp 4;
BA_ "SPN" SG_ 2566834942 FlashAmberWarningLamp 3040;
BA_ "SAEDocument" SG_ 2566834942 FlashAmberWarningLamp "J1939-73";
BA_ "SigType" SG_ 2566834942 MalfunctionIndicatorLampStatus 4;
BA_ "SPN" SG_ 2566834942 MalfunctionIndicatorLampStatus 1213;
BA_ "SAEDocument" SG_ 2566834942 MalfunctionIndicatorLampStatus "J1939-73";
BA_ "SigType" SG_ 2566834942 AmberWarningLampStatus 4;
BA_ "SPN" SG_ 2566834942 AmberWarningLampStatus 624;
BA_ "SAEDocument" SG_ 2566834942 AmberWarningLampStatus "J1939-73";
BA_ "SigType" SG_ 2566834942 RedStopLampState 4;
BA_ "SPN" SG_ 2566834942 RedStopLampState 623;
BA_ "SAEDocument" SG_ 2566834942 RedStopLampState "J1939-73";
BA_ "SigType" SG_ 2566834942 ProtectLampStatus 4;
BA_ "SPN" SG_ 2566834942 ProtectLampStatus 987;
BA_ "SAEDocument" SG_ 2566834942 ProtectLampStatus "J1939-73";
BA_ "SigType" SG_ 2566834942 DTC5 7;
BA_ "SAEDocument" SG_ 2566834942 DTC5 "J1939-73";
BA_ "SigType" SG_ 2566834942 DTC4 7;
BA_ "SAEDocument" SG_ 2566834942 DTC4 "J1939-73";
BA_ "SigType" SG_ 2566834942 DTC3 7;
BA_ "SAEDocument" SG_ 2566834942 DTC3 "J1939-73";
BA_ "SigType" SG_ 2566834942 DTC2 7;
BA_ "SAEDocument" SG_ 2566834942 DTC2 "J1939-73";
BA_ "SigType" SG_ 2566834942 DTC1 7;
BA_ "SAEDocument" SG_ 2566834942 DTC1 "J1939-73";
BA_ "SigType" SG_ 2566838526 AddressAssignment 1;
BA_ "SPN" SG_ 2566838526 AddressAssignment 2847;
BA_ "SAEDocument" SG_ 2566838526 AddressAssignment "J1939-81";
BA_ "SPN" SG_ 2566838526 ArbitraryAddressCapable 2844;
BA_ "SAEDocument" SG_ 2566838526 ArbitraryAddressCapable "J1939-81";
BA_ "SPN" SG_ 2566838526 IndustryGroup 2846;
BA_ "SAEDocument" SG_ 2566838526 IndustryGroup "NMEA2000";
BA_ "SPN" SG_ 2566838526 VehicleSystemInstance 2843;
BA_ "SAEDocument" SG_ 2566838526 VehicleSystemInstance "J1939-81";
BA_ "SPN" SG_ 2566838526 Function 2841;
BA_ "SAEDocument" SG_ 2566838526 Function "J1939-81";
BA_ "SAEDocument" SG_ 2566838526 VehicleSystem "J1939-81";
BA_ "SPN" SG_ 2566838526 FunctionInstance 2839;
BA_ "SAEDocument" SG_ 2566838526 FunctionInstance "J1939-81";
BA_ "SPN" SG_ 2566838526 ECUInstance 2840;
BA_ "SAEDocument" SG_ 2566838526 ECUInstance "J1939-81";
BA_ "SigType" SG_ 2566838526 ManufacturerCode 1;
BA_ "SPN" SG_ 2566838526 ManufacturerCode 2838;
BA_ "SAEDocument" SG_ 2566838526 ManufacturerCode "NMEA2000";
BA_ "SPN" SG_ 2566838526 IdentityNumber 2837;
BA_ "SAEDocument" SG_ 2566838526 IdentityNumber "J1939-81";
BA_ "SAEDocument" SG_ 2566838526 VehicleSystem5 "J1939-81";
BA_ "SAEDocument" SG_ 2566838526 VehicleSystem4 "J1939-81";
BA_ "SAEDocument" SG_ 2566838526 VehicleSystem3 "J1939-81";
BA_ "SAEDocument" SG_ 2566838526 VehicleSystem2 "J1939-81";
BA_ "SAEDocument" SG_ 2566838526 VehicleSystem1 "J1939-81";
BA_ "SPN" SG_ 2632711934 SequenceNumber 2572;
BA_ "SAEDocument" SG_ 2632711934 SequenceNumber "J1939-21";
BA_ "SAEDocument" SG_ 2632777470 TotalNumberOfPacketsEoMA "J1939-21";
BA_ "SAEDocument" SG_ 2632777470 TotalMessageSizeEoMA "J1939-21";
BA_ "SAEDocument" SG_ 2632777470 TotalMessageSizeBAM "J1939-21";
BA_ "SAEDocument" SG_ 2632777470 TotalNumberOfPacketsBAM "J1939-21";
BA_ "SPN" SG_ 2632777470 ConnectionAbortReason 2570;
BA_ "SAEDocument" SG_ 2632777470 ConnectionAbortReason "J1939-21";
BA_ "SPN" SG_ 2632777470 NextPacketNumberToBeSent 2562;
BA_ "SAEDocument" SG_ 2632777470 NextPacketNumberToBeSent "J1939-21";
BA_ "SPN" SG_ 2632777470 NumberOfPacketsThatCanBeSent 2561;
BA_ "SAEDocument" SG_ 2632777470 NumberOfPacketsThatCanBeSent "J1939-21";
BA_ "SigType" SG_ 2632777470 PGNumber 6;
BA_ "SPN" SG_ 2632777470 PGNumber 2560;
BA_ "SAEDocument" SG_ 2632777470 PGNumber "J1939-21";
BA_ "SPN" SG_ 2632777470 MaximumNumberOfPackets 2559;
BA_ "SAEDocument" SG_ 2632777470 MaximumNumberOfPackets "J1939-21";
BA_ "SPN" SG_ 2632777470 TotalNumberOfPackets 2558;
BA_ "SAEDocument" SG_ 2632777470 TotalNumberOfPackets "J1939-21";
BA_ "SPN" SG_ 2632777470 TotalMessageSize 2557;
BA_ "SAEDocument" SG_ 2632777470 TotalMessageSize "J1939-21";
BA_ "SPN" SG_ 2632777470 ControlByte 2556;
BA_ "SAEDocument" SG_ 2632777470 ControlByte "J1939-21";
BA_ "SigType" SG_ 2565537534 ParameterGroupNumber 6;
BA_ "SPN" SG_ 2565537534 ParameterGroupNumber 2574;
BA_ "SAEDocument" SG_ 2565537534 ParameterGroupNumber "J1939-21";
BA_ "SigType" SG_ 2566739198 FlashRedStopLamp 4;
BA_ "SPN" SG_ 2566739198 FlashRedStopLamp 3039;
BA_ "SAEDocument" SG_ 2566739198 FlashRedStopLamp "J1939-73";
BA_ "SigType" SG_ 2566739198 FlashProtectLamp 4;
BA_ "SPN" SG_ 2566739198 FlashProtectLamp 3041;
BA_ "SAEDocument" SG_ 2566739198 FlashProtectLamp "J1939-73";
BA_ "SigType" SG_ 2566739198 FlashMalfuncIndicatorLamp 4;
BA_ "SPN" SG_ 2566739198 FlashMalfuncIndicatorLamp 3038;
BA_ "SAEDocument" SG_ 2566739198 FlashMalfuncIndicatorLamp "J1939-73";
BA_ "SigType" SG_ 2566739198 FlashAmberWarningLamp 4;
BA_ "SPN" SG_ 2566739198 FlashAmberWarningLamp 3040;
BA_ "SAEDocument" SG_ 2566739198 FlashAmberWarningLamp "J1939-73";
BA_ "SigType" SG_ 2566739198 MalfunctionIndicatorLampStatus 4;
BA_ "SPN" SG_ 2566739198 MalfunctionIndicatorLampStatus 1213;
BA_ "SAEDocument" SG_ 2566739198 MalfunctionIndicatorLampStatus "J1939-73";
BA_ "SigType" SG_ 2566739198 AmberWarningLampStatus 4;
BA_ "SPN" SG_ 2566739198 AmberWarningLampStatus 624;
BA_ "SAEDocument" SG_ 2566739198 AmberWarningLampStatus "J1939-73";
BA_ "SigType" SG_ 2566739198 RedStopLampState 4;
BA_ "SPN" SG_ 2566739198 RedStopLampState 623;
BA_ "SAEDocument" SG_ 2566739198 RedStopLampState "J1939-73";
BA_ "SigType" SG_ 2566739198 ProtectLampStatus 4;
BA_ "SPN" SG_ 2566739198 ProtectLampStatus 987;
BA_ "SAEDocument" SG_ 2566739198 ProtectLampStatus "J1939-73";
BA_ "SigType" SG_ 2566739198 DTC5 7;
BA_ "SAEDocument" SG_ 2566739198 DTC5 "J1939-73";
BA_ "SigType" SG_ 2566739198 DTC4 7;
BA_ "SAEDocument" SG_ 2566739198 DTC4 "J1939-73";
BA_ "SigType" SG_ 2566739198 DTC3 7;
BA_ "SAEDocument" SG_ 2566739198 DTC3 "J1939-73";
BA_ "SigType" SG_ 2566739198 DTC2 7;
BA_ "SAEDocument" SG_ 2566739198 DTC2 "J1939-73";
BA_ "SigType" SG_ 2566739198 DTC1 7;
BA_ "SAEDocument" SG_ 2566739198 DTC1 "J1939-73";
BA_ "SigType" SG_ 2566739454 FlashRedStopLamp 4;
BA_ "SPN" SG_ 2566739454 FlashRedStopLamp 3039;
BA_ "SAEDocument" SG_ 2566739454 FlashRedStopLamp "J1939-73";
BA_ "SigType" SG_ 2566739454 FlashProtectLamp 4;
BA_ "SPN" SG_ 2566739454 FlashProtectLamp 3041;
BA_ "SAEDocument" SG_ 2566739454 FlashProtectLamp "J1939-73";
BA_ "SigType" SG_ 2566739454 FlashMalfuncIndicatorLamp 4;
BA_ "SPN" SG_ 2566739454 FlashMalfuncIndicatorLamp 3038;
BA_ "SAEDocument" SG_ 2566739454 FlashMalfuncIndicatorLamp "J1939-73";
BA_ "SigType" SG_ 2566739454 FlashAmberWarningLamp 4;
BA_ "SPN" SG_ 2566739454 FlashAmberWarningLamp 3040;
BA_ "SAEDocument" SG_ 2566739454 FlashAmberWarningLamp "J1939-73";
BA_ "SigType" SG_ 2566739454 MalfunctionIndicatorLampStatus 4;
BA_ "SPN" SG_ 2566739454 MalfunctionIndicatorLampStatus 1213;
BA_ "SAEDocument" SG_ 2566739454 MalfunctionIndicatorLampStatus "J1939-73";
BA_ "SigType" SG_ 2566739454 AmberWarningLampStatus 4;
BA_ "SPN" SG_ 2566739454 AmberWarningLampStatus 624;
BA_ "SAEDocument" SG_ 2566739454 AmberWarningLampStatus "J1939-73";
BA_ "SigType" SG_ 2566739454 RedStopLampState 4;
BA_ "SPN" SG_ 2566739454 RedStopLampState 623;
BA_ "SAEDocument" SG_ 2566739454 RedStopLampState "J1939-73";
BA_ "SigType" SG_ 2566739454 ProtectLampStatus 4;
BA_ "SPN" SG_ 2566739454 ProtectLampStatus 987;
BA_ "SAEDocument" SG_ 2566739454 ProtectLampStatus "J1939-73";
BA_ "SigType" SG_ 2566739454 DTC5 7;
BA_ "SAEDocument" SG_ 2566739454 DTC5 "J1939-73";
BA_ "SigType" SG_ 2566739454 DTC4 7;
BA_ "SAEDocument" SG_ 2566739454 DTC4 "J1939-73";
BA_ "SigType" SG_ 2566739454 DTC3 7;
BA_ "SAEDocument" SG_ 2566739454 DTC3 "J1939-73";
BA_ "SigType" SG_ 2566739454 DTC2 7;
BA_ "SAEDocument" SG_ 2566739454 DTC2 "J1939-73";
BA_ "SigType" SG_ 2566739454 DTC1 7;
BA_ "SAEDocument" SG_ 2566739454 DTC1 "J1939-73";
BA_ "SigType" SG_ 2566739710 FlashRedStopLamp 4;
BA_ "SPN" SG_ 2566739710 FlashRedStopLamp 3039;
BA_ "SAEDocument" SG_ 2566739710 FlashRedStopLamp "J1939-73";
BA_ "SigType" SG_ 2566739710 FlashProtectLamp 4;
BA_ "SPN" SG_ 2566739710 FlashProtectLamp 3041;
BA_ "SAEDocument" SG_ 2566739710 FlashProtectLamp "J1939-73";
BA_ "SigType" SG_ 2566739710 FlashMalfuncIndicatorLamp 4;
BA_ "SPN" SG_ 2566739710 FlashMalfuncIndicatorLamp 3038;
BA_ "SAEDocument" SG_ 2566739710 FlashMalfuncIndicatorLamp "J1939-73";
BA_ "SigType" SG_ 2566739710 FlashAmberWarningLamp 4;
BA_ "SPN" SG_ 2566739710 FlashAmberWarningLamp 3040;
BA_ "SAEDocument" SG_ 2566739710 FlashAmberWarningLamp "J1939-73";
BA_ "SigType" SG_ 2566739710 MalfunctionIndicatorLampStatus 4;
BA_ "SPN" SG_ 2566739710 MalfunctionIndicatorLampStatus 1213;
BA_ "SAEDocument" SG_ 2566739710 MalfunctionIndicatorLampStatus "J1939-73";
BA_ "SigType" SG_ 2566739710 AmberWarningLampStatus 4;
BA_ "SPN" SG_ 2566739710 AmberWarningLampStatus 624;
BA_ "SAEDocument" SG_ 2566739710 AmberWarningLampStatus "J1939-73";
BA_ "SigType" SG_ 2566739710 RedStopLampState 4;
BA_ "SPN" SG_ 2566739710 RedStopLampState 623;
BA_ "SAEDocument" SG_ 2566739710 RedStopLampState "J1939-73";
BA_ "SigType" SG_ 2566739710 ProtectLampStatus 4;
BA_ "SPN" SG_ 2566739710 ProtectLampStatus 987;
BA_ "SAEDocument" SG_ 2566739710 ProtectLampStatus "J1939-73";
BA_ "SigType" SG_ 2566739710 DTC5 7;
BA_ "SAEDocument" SG_ 2566739710 DTC5 "J1939-73";
BA_ "SigType" SG_ 2566739710 DTC4 7;
BA_ "SAEDocument" SG_ 2566739710 DTC4 "J1939-73";
BA_ "SigType" SG_ 2566739710 DTC3 7;
BA_ "SAEDocument" SG_ 2566739710 DTC3 "J1939-73";
BA_ "SigType" SG_ 2566739710 DTC2 7;
BA_ "SAEDocument" SG_ 2566739710 DTC2 "J1939-73";
BA_ "SigType" SG_ 2566739710 DTC1 7;
BA_ "SAEDocument" SG_ 2566739710 DTC1 "J1939-73";
BA_ "SigType" SG_ 2566739966 FlashRedStopLamp 4;
BA_ "SPN" SG_ 2566739966 FlashRedStopLamp 3039;
BA_ "SAEDocument" SG_ 2566739966 FlashRedStopLamp "J1939-73";
BA_ "SigType" SG_ 2566739966 FlashProtectLamp 4;
BA_ "SPN" SG_ 2566739966 FlashProtectLamp 3041;
BA_ "SAEDocument" SG_ 2566739966 FlashProtectLamp "J1939-73";
BA_ "SigType" SG_ 2566739966 FlashMalfuncIndicatorLamp 4;
BA_ "SPN" SG_ 2566739966 FlashMalfuncIndicatorLamp 3038;
BA_ "SAEDocument" SG_ 2566739966 FlashMalfuncIndicatorLamp "J1939-73";
BA_ "SigType" SG_ 2566739966 FlashAmberWarningLamp 4;
BA_ "SPN" SG_ 2566739966 FlashAmberWarningLamp 3040;
BA_ "SAEDocument" SG_ 2566739966 FlashAmberWarningLamp "J1939-73";
BA_ "SigType" SG_ 2566739966 MalfunctionIndicatorLampStatus 4;
BA_ "SPN" SG_ 2566739966 MalfunctionIndicatorLampStatus 1213;
BA_ "SAEDocument" SG_ 2566739966 MalfunctionIndicatorLampStatus "J1939-73";
BA_ "SigType" SG_ 2566739966 AmberWarningLampStatus 4;
BA_ "SPN" SG_ 2566739966 AmberWarningLampStatus 624;
BA_ "SAEDocument" SG_ 2566739966 AmberWarningLampStatus "J1939-73";
BA_ "SigType" SG_ 2566739966 RedStopLampState 4;
BA_ "SPN" SG_ 2566739966 RedStopLampState 623;
BA_ "SAEDocument" SG_ 2566739966 RedStopLampState "J1939-73";
BA_ "SigType" SG_ 2566739966 ProtectLampStatus 4;
BA_ "SPN" SG_ 2566739966 ProtectLampStatus 987;
BA_ "SAEDocument" SG_ 2566739966 ProtectLampStatus "J1939-73";
BA_ "SigType" SG_ 2566739966 DTC5 7;
BA_ "SAEDocument" SG_ 2566739966 DTC5 "J1939-73";
BA_ "SigType" SG_ 2566739966 DTC4 7;
BA_ "SAEDocument" SG_ 2566739966 DTC4 "J1939-73";
BA_ "SigType" SG_ 2566739966 DTC3 7;
BA_ "SAEDocument" SG_ 2566739966 DTC3 "J1939-73";
BA_ "SigType" SG_ 2566739966 DTC2 7;
BA_ "SAEDocument" SG_ 2566739966 DTC2 "J1939-73";
BA_ "SigType" SG_ 2566739966 DTC1 7;
BA_ "SAEDocument" SG_ 2566739966 DTC1 "J1939-73";
BA_ "SigType" SG_ 2566740222 FlashRedStopLamp 4;
BA_ "SPN" SG_ 2566740222 FlashRedStopLamp 3039;
BA_ "SAEDocument" SG_ 2566740222 FlashRedStopLamp "J1939-73";
BA_ "SigType" SG_ 2566740222 FlashProtectLamp 4;
BA_ "SPN" SG_ 2566740222 FlashProtectLamp 3041;
BA_ "SAEDocument" SG_ 2566740222 FlashProtectLamp "J1939-73";
BA_ "SigType" SG_ 2566740222 FlashMalfuncIndicatorLamp 4;
BA_ "SPN" SG_ 2566740222 FlashMalfuncIndicatorLamp 3038;
BA_ "SAEDocument" SG_ 2566740222 FlashMalfuncIndicatorLamp "J1939-73";
BA_ "SigType" SG_ 2566740222 FlashAmberWarningLamp 4;
BA_ "SPN" SG_ 2566740222 FlashAmberWarningLamp 3040;
BA_ "SAEDocument" SG_ 2566740222 FlashAmberWarningLamp "J1939-73";
BA_ "SigType" SG_ 2566740222 MalfunctionIndicatorLampStatus 4;
BA_ "SPN" SG_ 2566740222 MalfunctionIndicatorLampStatus 1213;
BA_ "SAEDocument" SG_ 2566740222 MalfunctionIndicatorLampStatus "J1939-73";
BA_ "SigType" SG_ 2566740222 AmberWarningLampStatus 4;
BA_ "SPN" SG_ 2566740222 AmberWarningLampStatus 624;
BA_ "SAEDocument" SG_ 2566740222 AmberWarningLampStatus "J1939-73";
BA_ "SigType" SG_ 2566740222 RedStopLampState 4;
BA_ "SPN" SG_ 2566740222 RedStopLampState 623;
BA_ "SAEDocument" SG_ 2566740222 RedStopLampState "J1939-73";
BA_ "SigType" SG_ 2566740222 ProtectLampStatus 4;
BA_ "SPN" SG_ 2566740222 ProtectLampStatus 987;
BA_ "SAEDocument" SG_ 2566740222 ProtectLampStatus "J1939-73";
BA_ "SigType" SG_ 2566740222 DTC5 7;
BA_ "SAEDocument" SG_ 2566740222 DTC5 "J1939-73";
BA_ "SigType" SG_ 2566740222 DTC4 7;
BA_ "SAEDocument" SG_ 2566740222 DTC4 "J1939-73";
BA_ "SigType" SG_ 2566740222 DTC3 7;
BA_ "SAEDocument" SG_ 2566740222 DTC3 "J1939-73";
BA_ "SigType" SG_ 2566740222 DTC2 7;
BA_ "SAEDocument" SG_ 2566740222 DTC2 "J1939-73";
BA_ "SigType" SG_ 2566740222 DTC1 7;
BA_ "SAEDocument" SG_ 2566740222 DTC1 "J1939-73";
BA_ "SigType" SG_ 2566740478 FlashRedStopLamp 4;
BA_ "SPN" SG_ 2566740478 FlashRedStopLamp 3039;
BA_ "SAEDocument" SG_ 2566740478 FlashRedStopLamp "J1939-73";
BA_ "SigType" SG_ 2566740478 FlashProtectLamp 4;
BA_ "SPN" SG_ 2566740478 FlashProtectLamp 3041;
BA_ "SAEDocument" SG_ 2566740478 FlashProtectLamp "J1939-73";
BA_ "SigType" SG_ 2566740478 FlashMalfuncIndicatorLamp 4;
BA_ "SPN" SG_ 2566740478 FlashMalfuncIndicatorLamp 3038;
BA_ "SAEDocument" SG_ 2566740478 FlashMalfuncIndicatorLamp "J1939-73";
BA_ "SigType" SG_ 2566740478 FlashAmberWarningLamp 4;
BA_ "SPN" SG_ 2566740478 FlashAmberWarningLamp 3040;
BA_ "SAEDocument" SG_ 2566740478 FlashAmberWarningLamp "J1939-73";
BA_ "SigType" SG_ 2566740478 MalfunctionIndicatorLampStatus 4;
BA_ "SPN" SG_ 2566740478 MalfunctionIndicatorLampStatus 1213;
BA_ "SAEDocument" SG_ 2566740478 MalfunctionIndicatorLampStatus "J1939-73";
BA_ "SigType" SG_ 2566740478 AmberWarningLampStatus 4;
BA_ "SPN" SG_ 2566740478 AmberWarningLampStatus 624;
BA_ "SAEDocument" SG_ 2566740478 AmberWarningLampStatus "J1939-73";
BA_ "SigType" SG_ 2566740478 RedStopLampState 4;
BA_ "SPN" SG_ 2566740478 RedStopLampState 623;
BA_ "SAEDocument" SG_ 2566740478 RedStopLampState "J1939-73";
BA_ "SigType" SG_ 2566740478 ProtectLampStatus 4;
BA_ "SPN" SG_ 2566740478 ProtectLampStatus 987;
BA_ "SAEDocument" SG_ 2566740478 ProtectLampStatus "J1939-73";
BA_ "SigType" SG_ 2566740478 DTC5 7;
BA_ "SAEDocument" SG_ 2566740478 DTC5 "J1939-73";
BA_ "SigType" SG_ 2566740478 DTC4 7;
BA_ "SAEDocument" SG_ 2566740478 DTC4 "J1939-73";
BA_ "SigType" SG_ 2566740478 DTC3 7;
BA_ "SAEDocument" SG_ 2566740478 DTC3 "J1939-73";
BA_ "SigType" SG_ 2566740478 DTC2 7;
BA_ "SAEDocument" SG_ 2566740478 DTC2 "J1939-73";
BA_ "SigType" SG_ 2566740478 DTC1 7;
BA_ "SAEDocument" SG_ 2566740478 DTC1 "J1939-73";
BA_ "SigType" SG_ 2566740734 FlashRedStopLamp 4;
BA_ "SPN" SG_ 2566740734 FlashRedStopLamp 3039;
BA_ "SAEDocument" SG_ 2566740734 FlashRedStopLamp "J1939-73";
BA_ "SigType" SG_ 2566740734 FlashProtectLamp 4;
BA_ "SPN" SG_ 2566740734 FlashProtectLamp 3041;
BA_ "SAEDocument" SG_ 2566740734 FlashProtectLamp "J1939-73";
BA_ "SigType" SG_ 2566740734 FlashMalfuncIndicatorLamp 4;
BA_ "SPN" SG_ 2566740734 FlashMalfuncIndicatorLamp 3038;
BA_ "SAEDocument" SG_ 2566740734 FlashMalfuncIndicatorLamp "J1939-73";
BA_ "SigType" SG_ 2566740734 FlashAmberWarningLamp 4;
BA_ "SPN" SG_ 2566740734 FlashAmberWarningLamp 3040;
BA_ "SAEDocument" SG_ 2566740734 FlashAmberWarningLamp "J1939-73";
BA_ "SigType" SG_ 2566740734 MalfunctionIndicatorLampStatus 4;
BA_ "SPN" SG_ 2566740734 MalfunctionIndicatorLampStatus 1213;
BA_ "SAEDocument" SG_ 2566740734 MalfunctionIndicatorLampStatus "J1939-73";
BA_ "SigType" SG_ 2566740734 AmberWarningLampStatus 4;
BA_ "SPN" SG_ 2566740734 AmberWarningLampStatus 624;
BA_ "SAEDocument" SG_ 2566740734 AmberWarningLampStatus "J1939-73";
BA_ "SigType" SG_ 2566740734 RedStopLampState 4;
BA_ "SPN" SG_ 2566740734 RedStopLampState 623;
BA_ "SAEDocument" SG_ 2566740734 RedStopLampState "J1939-73";
BA_ "SigType" SG_ 2566740734 ProtectLampStatus 4;
BA_ "SPN" SG_ 2566740734 ProtectLampStatus 987;
BA_ "SAEDocument" SG_ 2566740734 ProtectLampStatus "J1939-73";
BA_ "SigType" SG_ 2566740734 DTC5 7;
BA_ "SAEDocument" SG_ 2566740734 DTC5 "J1939-73";
BA_ "SigType" SG_ 2566740734 DTC4 7;
BA_ "SAEDocument" SG_ 2566740734 DTC4 "J1939-73";
BA_ "SigType" SG_ 2566740734 DTC3 7;
BA_ "SAEDocument" SG_ 2566740734 DTC3 "J1939-73";
BA_ "SigType" SG_ 2566740734 DTC2 7;
BA_ "SAEDocument" SG_ 2566740734 DTC2 "J1939-73";
BA_ "SigType" SG_ 2566740734 DTC1 7;
BA_ "SAEDocument" SG_ 2566740734 DTC1 "J1939-73";
BA_ "SigType" SG_ 2566740990 FlashRedStopLamp 4;
BA_ "SPN" SG_ 2566740990 FlashRedStopLamp 3039;
BA_ "SAEDocument" SG_ 2566740990 FlashRedStopLamp "J1939-73";
BA_ "SigType" SG_ 2566740990 FlashProtectLamp 4;
BA_ "SPN" SG_ 2566740990 FlashProtectLamp 3041;
BA_ "SAEDocument" SG_ 2566740990 FlashProtectLamp "J1939-73";
BA_ "SigType" SG_ 2566740990 FlashMalfuncIndicatorLamp 4;
BA_ "SPN" SG_ 2566740990 FlashMalfuncIndicatorLamp 3038;
BA_ "SAEDocument" SG_ 2566740990 FlashMalfuncIndicatorLamp "J1939-73";
BA_ "SigType" SG_ 2566740990 FlashAmberWarningLamp 4;
BA_ "SPN" SG_ 2566740990 FlashAmberWarningLamp 3040;
BA_ "SAEDocument" SG_ 2566740990 FlashAmberWarningLamp "J1939-73";
BA_ "SigType" SG_ 2566740990 MalfunctionIndicatorLampStatus 4;
BA_ "SPN" SG_ 2566740990 MalfunctionIndicatorLampStatus 1213;
BA_ "SAEDocument" SG_ 2566740990 MalfunctionIndicatorLampStatus "J1939-73";
BA_ "SigType" SG_ 2566740990 AmberWarningLampStatus 4;
BA_ "SPN" SG_ 2566740990 AmberWarningLampStatus 624;
BA_ "SAEDocument" SG_ 2566740990 AmberWarningLampStatus "J1939-73";
BA_ "SigType" SG_ 2566740990 RedStopLampState 4;
BA_ "SPN" SG_ 2566740990 RedStopLampState 623;
BA_ "SAEDocument" SG_ 2566740990 RedStopLampState "J1939-73";
BA_ "SigType" SG_ 2566740990 ProtectLampStatus 4;
BA_ "SPN" SG_ 2566740990 ProtectLampStatus 987;
BA_ "SAEDocument" SG_ 2566740990 ProtectLampStatus "J1939-73";
BA_ "SigType" SG_ 2566740990 DTC5 7;
BA_ "SAEDocument" SG_ 2566740990 DTC5 "J1939-73";
BA_ "SigType" SG_ 2566740990 DTC4 7;
BA_ "SAEDocument" SG_ 2566740990 DTC4 "J1939-73";
BA_ "SigType" SG_ 2566740990 DTC3 7;
BA_ "SAEDocument" SG_ 2566740990 DTC3 "J1939-73";
BA_ "SigType" SG_ 2566740990 DTC2 7;
BA_ "SAEDocument" SG_ 2566740990 DTC2 "J1939-73";
BA_ "SigType" SG_ 2566740990 DTC1 7;
BA_ "SAEDocument" SG_ 2566740990 DTC1 "J1939-73";
BA_ "SigType" SG_ 2566741246 FlashRedStopLamp 4;
BA_ "SPN" SG_ 2566741246 FlashRedStopLamp 3039;
BA_ "SAEDocument" SG_ 2566741246 FlashRedStopLamp "J1939-73";
BA_ "SigType" SG_ 2566741246 FlashProtectLamp 4;
BA_ "SPN" SG_ 2566741246 FlashProtectLamp 3041;
BA_ "SAEDocument" SG_ 2566741246 FlashProtectLamp "J1939-73";
BA_ "SigType" SG_ 2566741246 FlashMalfuncIndicatorLamp 4;
BA_ "SPN" SG_ 2566741246 FlashMalfuncIndicatorLamp 3038;
BA_ "SAEDocument" SG_ 2566741246 FlashMalfuncIndicatorLamp "J1939-73";
BA_ "SigType" SG_ 2566741246 FlashAmberWarningLamp 4;
BA_ "SPN" SG_ 2566741246 FlashAmberWarningLamp 3040;
BA_ "SAEDocument" SG_ 2566741246 FlashAmberWarningLamp "J1939-73";
BA_ "SigType" SG_ 2566741246 MalfunctionIndicatorLampStatus 4;
BA_ "SPN" SG_ 2566741246 MalfunctionIndicatorLampStatus 1213;
BA_ "SAEDocument" SG_ 2566741246 MalfunctionIndicatorLampStatus "J1939-73";
BA_ "SigType" SG_ 2566741246 AmberWarningLampStatus 4;
BA_ "SPN" SG_ 2566741246 AmberWarningLampStatus 624;
BA_ "SAEDocument" SG_ 2566741246 AmberWarningLampStatus "J1939-73";
BA_ "SigType" SG_ 2566741246 RedStopLampState 4;
BA_ "SPN" SG_ 2566741246 RedStopLampState 623;
BA_ "SAEDocument" SG_ 2566741246 RedStopLampState "J1939-73";
BA_ "SigType" SG_ 2566741246 ProtectLampStatus 4;
BA_ "SPN" SG_ 2566741246 ProtectLampStatus 987;
BA_ "SAEDocument" SG_ 2566741246 ProtectLampStatus "J1939-73";
BA_ "SigType" SG_ 2566741246 DTC5 7;
BA_ "SAEDocument" SG_ 2566741246 DTC5 "J1939-73";
BA_ "SigType" SG_ 2566741246 DTC4 7;
BA_ "SAEDocument" SG_ 2566741246 DTC4 "J1939-73";
BA_ "SigType" SG_ 2566741246 DTC3 7;
BA_ "SAEDocument" SG_ 2566741246 DTC3 "J1939-73";
BA_ "SigType" SG_ 2566741246 DTC2 7;
BA_ "SAEDocument" SG_ 2566741246 DTC2 "J1939-73";
BA_ "SigType" SG_ 2566741246 DTC1 7;
BA_ "SAEDocument" SG_ 2566741246 DTC1 "J1939-73";
BA_ "SigType" SG_ 2566741502 FlashRedStopLamp 4;
BA_ "SPN" SG_ 2566741502 FlashRedStopLamp 3039;
BA_ "SAEDocument" SG_ 2566741502 FlashRedStopLamp "J1939-73";
BA_ "SigType" SG_ 2566741502 FlashProtectLamp 4;
BA_ "SPN" SG_ 2566741502 FlashProtectLamp 3041;
BA_ "SAEDocument" SG_ 2566741502 FlashProtectLamp "J1939-73";
BA_ "SigType" SG_ 2566741502 FlashMalfuncIndicatorLamp 4;
BA_ "SPN" SG_ 2566741502 FlashMalfuncIndicatorLamp 3038;
BA_ "SAEDocument" SG_ 2566741502 FlashMalfuncIndicatorLamp "J1939-73";
BA_ "SigType" SG_ 2566741502 FlashAmberWarningLamp 4;
BA_ "SPN" SG_ 2566741502 FlashAmberWarningLamp 3040;
BA_ "SAEDocument" SG_ 2566741502 FlashAmberWarningLamp "J1939-73";
BA_ "SigType" SG_ 2566741502 MalfunctionIndicatorLampStatus 4;
BA_ "SPN" SG_ 2566741502 MalfunctionIndicatorLampStatus 1213;
BA_ "SAEDocument" SG_ 2566741502 MalfunctionIndicatorLampStatus "J1939-73";
BA_ "SigType" SG_ 2566741502 AmberWarningLampStatus 4;
BA_ "SPN" SG_ 2566741502 AmberWarningLampStatus 624;
BA_ "SAEDocument" SG_ 2566741502 AmberWarningLampStatus "J1939-73";
BA_ "SigType" SG_ 2566741502 RedStopLampState 4;
BA_ "SPN" SG_ 2566741502 RedStopLampState 623;
BA_ "SAEDocument" SG_ 2566741502 RedStopLampState "J1939-73";
BA_ "SigType" SG_ 2566741502 ProtectLampStatus 4;
BA_ "SPN" SG_ 2566741502 ProtectLampStatus 987;
BA_ "SAEDocument" SG_ 2566741502 ProtectLampStatus "J1939-73";
BA_ "SigType" SG_ 2566741502 DTC5 7;
BA_ "SAEDocument" SG_ 2566741502 DTC5 "J1939-73";
BA_ "SigType" SG_ 2566741502 DTC4 7;
BA_ "SAEDocument" SG_ 2566741502 DTC4 "J1939-73";
BA_ "SigType" SG_ 2566741502 DTC3 7;
BA_ "SAEDocument" SG_ 2566741502 DTC3 "J1939-73";
BA_ "SigType" SG_ 2566741502 DTC2 7;
BA_ "SAEDocument" SG_ 2566741502 DTC2 "J1939-73";
BA_ "SigType" SG_ 2566741502 DTC1 7;
BA_ "SAEDocument" SG_ 2566741502 DTC1 "J1939-73";
BA_ "SigType" SG_ 2566741758 FlashRedStopLamp 4;
BA_ "SPN" SG_ 2566741758 FlashRedStopLamp 3039;
BA_ "SAEDocument" SG_ 2566741758 FlashRedStopLamp "J1939-73";
BA_ "SigType" SG_ 2566741758 FlashProtectLamp 4;
BA_ "SPN" SG_ 2566741758 FlashProtectLamp 3041;
BA_ "SAEDocument" SG_ 2566741758 FlashProtectLamp "J1939-73";
BA_ "SigType" SG_ 2566741758 FlashMalfuncIndicatorLamp 4;
BA_ "SPN" SG_ 2566741758 FlashMalfuncIndicatorLamp 3038;
BA_ "SAEDocument" SG_ 2566741758 FlashMalfuncIndicatorLamp "J1939-73";
BA_ "SigType" SG_ 2566741758 FlashAmberWarningLamp 4;
BA_ "SPN" SG_ 2566741758 FlashAmberWarningLamp 3040;
BA_ "SAEDocument" SG_ 2566741758 FlashAmberWarningLamp "J1939-73";
BA_ "SigType" SG_ 2566741758 MalfunctionIndicatorLampStatus 4;
BA_ "SPN" SG_ 2566741758 MalfunctionIndicatorLampStatus 1213;
BA_ "SAEDocument" SG_ 2566741758 MalfunctionIndicatorLampStatus "J1939-73";
BA_ "SigType" SG_ 2566741758 AmberWarningLampStatus 4;
BA_ "SPN" SG_ 2566741758 AmberWarningLampStatus 624;
BA_ "SAEDocument" SG_ 2566741758 AmberWarningLampStatus "J1939-73";
BA_ "SigType" SG_ 2566741758 RedStopLampState 4;
BA_ "SPN" SG_ 2566741758 RedStopLampState 623;
BA_ "SAEDocument" SG_ 2566741758 RedStopLampState "J1939-73";
BA_ "SigType" SG_ 2566741758 ProtectLampStatus 4;
BA_ "SPN" SG_ 2566741758 ProtectLampStatus 987;
BA_ "SAEDocument" SG_ 2566741758 ProtectLampStatus "J1939-73";
BA_ "SigType" SG_ 2566741758 DTC5 7;
BA_ "SAEDocument" SG_ 2566741758 DTC5 "J1939-73";
BA_ "SigType" SG_ 2566741758 DTC4 7;
BA_ "SAEDocument" SG_ 2566741758 DTC4 "J1939-73";
BA_ "SigType" SG_ 2566741758 DTC3 7;
BA_ "SAEDocument" SG_ 2566741758 DTC3 "J1939-73";
BA_ "SigType" SG_ 2566741758 DTC2 7;
BA_ "SAEDocument" SG_ 2566741758 DTC2 "J1939-73";
BA_ "SigType" SG_ 2566741758 DTC1 7;
BA_ "SAEDocument" SG_ 2566741758 DTC1 "J1939-73";
BA_ "SigType" SG_ 2566742014 FlashRedStopLamp 4;
BA_ "SPN" SG_ 2566742014 FlashRedStopLamp 3039;
BA_ "SAEDocument" SG_ 2566742014 FlashRedStopLamp "J1939-73";
BA_ "SigType" SG_ 2566742014 FlashProtectLamp 4;
BA_ "SPN" SG_ 2566742014 FlashProtectLamp 3041;
BA_ "SAEDocument" SG_ 2566742014 FlashProtectLamp "J1939-73";
BA_ "SigType" SG_ 2566742014 FlashMalfuncIndicatorLamp 4;
BA_ "SPN" SG_ 2566742014 FlashMalfuncIndicatorLamp 3038;
BA_ "SAEDocument" SG_ 2566742014 FlashMalfuncIndicatorLamp "J1939-73";
BA_ "SigType" SG_ 2566742014 FlashAmberWarningLamp 4;
BA_ "SPN" SG_ 2566742014 FlashAmberWarningLamp 3040;
BA_ "SAEDocument" SG_ 2566742014 FlashAmberWarningLamp "J1939-73";
BA_ "SigType" SG_ 2566742014 MalfunctionIndicatorLampStatus 4;
BA_ "SPN" SG_ 2566742014 MalfunctionIndicatorLampStatus 1213;
BA_ "SAEDocument" SG_ 2566742014 MalfunctionIndicatorLampStatus "J1939-73";
BA_ "SigType" SG_ 2566742014 AmberWarningLampStatus 4;
BA_ "SPN" SG_ 2566742014 AmberWarningLampStatus 624;
BA_ "SAEDocument" SG_ 2566742014 AmberWarningLampStatus "J1939-73";
BA_ "SigType" SG_ 2566742014 RedStopLampState 4;
BA_ "SPN" SG_ 2566742014 RedStopLampState 623;
BA_ "SAEDocument" SG_ 2566742014 RedStopLampState "J1939-73";
BA_ "SigType" SG_ 2566742014 ProtectLampStatus 4;
BA_ "SPN" SG_ 2566742014 ProtectLampStatus 987;
BA_ "SAEDocument" SG_ 2566742014 ProtectLampStatus "J1939-73";
BA_ "SigType" SG_ 2566742014 DTC5 7;
BA_ "SAEDocument" SG_ 2566742014 DTC5 "J1939-73";
BA_ "SigType" SG_ 2566742014 DTC4 7;
BA_ "SAEDocument" SG_ 2566742014 DTC4 "J1939-73";
BA_ "SigType" SG_ 2566742014 DTC3 7;
BA_ "SAEDocument" SG_ 2566742014 DTC3 "J1939-73";
BA_ "SigType" SG_ 2566742014 DTC2 7;
BA_ "SAEDocument" SG_ 2566742014 DTC2 "J1939-73";
BA_ "SigType" SG_ 2566742014 DTC1 7;
BA_ "SAEDocument" SG_ 2566742014 DTC1 "J1939-73";
BA_ "SigType" SG_ 2560622334 FlashRedStopLamp 4;
BA_ "SPN" SG_ 2560622334 FlashRedStopLamp 3039;
BA_ "SAEDocument" SG_ 2560622334 FlashRedStopLamp "J1939-73";
BA_ "SigType" SG_ 2560622334 FlashProtectLamp 4;
BA_ "SPN" SG_ 2560622334 FlashProtectLamp 3041;
BA_ "SAEDocument" SG_ 2560622334 FlashProtectLamp "J1939-73";
BA_ "SigType" SG_ 2560622334 FlashMalfuncIndicatorLamp 4;
BA_ "SPN" SG_ 2560622334 FlashMalfuncIndicatorLamp 3038;
BA_ "SAEDocument" SG_ 2560622334 FlashMalfuncIndicatorLamp "J1939-73";
BA_ "SigType" SG_ 2560622334 FlashAmberWarningLamp 4;
BA_ "SPN" SG_ 2560622334 FlashAmberWarningLamp 3040;
BA_ "SAEDocument" SG_ 2560622334 FlashAmberWarningLamp "J1939-73";
BA_ "SigType" SG_ 2560622334 MalfunctionIndicatorLampStatus 4;
BA_ "SPN" SG_ 2560622334 MalfunctionIndicatorLampStatus 1213;
BA_ "SAEDocument" SG_ 2560622334 MalfunctionIndicatorLampStatus "J1939-73";
BA_ "SigType" SG_ 2560622334 AmberWarningLampStatus 4;
BA_ "SPN" SG_ 2560622334 AmberWarningLampStatus 624;
BA_ "SAEDocument" SG_ 2560622334 AmberWarningLampStatus "J1939-73";
BA_ "SigType" SG_ 2560622334 RedStopLampState 4;
BA_ "SPN" SG_ 2560622334 RedStopLampState 623;
BA_ "SAEDocument" SG_ 2560622334 RedStopLampState "J1939-73";
BA_ "SigType" SG_ 2560622334 ProtectLampStatus 4;
BA_ "SPN" SG_ 2560622334 ProtectLampStatus 987;
BA_ "SAEDocument" SG_ 2560622334 ProtectLampStatus "J1939-73";
BA_ "SigType" SG_ 2560622334 DTC5 7;
BA_ "SAEDocument" SG_ 2560622334 DTC5 "J1939-73";
BA_ "SigType" SG_ 2560622334 DTC4 7;
BA_ "SAEDocument" SG_ 2560622334 DTC4 "J1939-73";
BA_ "SigType" SG_ 2560622334 DTC3 7;
BA_ "SAEDocument" SG_ 2560622334 DTC3 "J1939-73";
BA_ "SigType" SG_ 2560622334 DTC2 7;
BA_ "SAEDocument" SG_ 2560622334 DTC2 "J1939-73";
BA_ "SigType" SG_ 2560622334 DTC1 7;
BA_ "SAEDocument" SG_ 2560622334 DTC1 "J1939-73";
BA_ "SigType" SG_ 2560556798 PermanentDTCs 1;
BA_ "SPN" SG_ 2560556798 PermanentDTCs 4108;
BA_ "SAEDocument" SG_ 2560556798 PermanentDTCs "J1939-73";
BA_ "SigType" SG_ 2560556798 PreviouslyMILOnDTCs 1;
BA_ "SPN" SG_ 2560556798 PreviouslyMILOnDTCs 4107;
BA_ "SAEDocument" SG_ 2560556798 PreviouslyMILOnDTCs "J1939-73";
BA_ "SigType" SG_ 2560556798 MILOnDTCs 1;
BA_ "SPN" SG_ 2560556798 MILOnDTCs 4106;
BA_ "SAEDocument" SG_ 2560556798 MILOnDTCs "J1939-73";
BA_ "SigType" SG_ 2560556798 AllPendingDTCs 1;
BA_ "SPN" SG_ 2560556798 AllPendingDTCs 4105;
BA_ "SAEDocument" SG_ 2560556798 AllPendingDTCs "J1939-73";
BA_ "SigType" SG_ 2560556798 PendingDTCs 1;
BA_ "SPN" SG_ 2560556798 PendingDTCs 4104;
BA_ "SAEDocument" SG_ 2560556798 PendingDTCs "J1939-73";
BA_ "SigType" SG_ 2566750462 FlashRedStopLamp 4;
BA_ "SPN" SG_ 2566750462 FlashRedStopLamp 3039;
BA_ "SAEDocument" SG_ 2566750462 FlashRedStopLamp "J1939-73";
BA_ "SigType" SG_ 2566750462 FlashProtectLamp 4;
BA_ "SPN" SG_ 2566750462 FlashProtectLamp 3041;
BA_ "SAEDocument" SG_ 2566750462 FlashProtectLamp "J1939-73";
BA_ "SigType" SG_ 2566750462 FlashMalfuncIndicatorLamp 4;
BA_ "SPN" SG_ 2566750462 FlashMalfuncIndicatorLamp 3038;
BA_ "SAEDocument" SG_ 2566750462 FlashMalfuncIndicatorLamp "J1939-73";
BA_ "SigType" SG_ 2566750462 FlashAmberWarningLamp 4;
BA_ "SPN" SG_ 2566750462 FlashAmberWarningLamp 3040;
BA_ "SAEDocument" SG_ 2566750462 FlashAmberWarningLamp "J1939-73";
BA_ "SigType" SG_ 2566750462 MalfunctionIndicatorLampStatus 4;
BA_ "SPN" SG_ 2566750462 MalfunctionIndicatorLampStatus 1213;
BA_ "SAEDocument" SG_ 2566750462 MalfunctionIndicatorLampStatus "J1939-73";
BA_ "SigType" SG_ 2566750462 AmberWarningLampStatus 4;
BA_ "SPN" SG_ 2566750462 AmberWarningLampStatus 624;
BA_ "SAEDocument" SG_ 2566750462 AmberWarningLampStatus "J1939-73";
BA_ "SigType" SG_ 2566750462 RedStopLampState 4;
BA_ "SPN" SG_ 2566750462 RedStopLampState 623;
BA_ "SAEDocument" SG_ 2566750462 RedStopLampState "J1939-73";
BA_ "SigType" SG_ 2566750462 ProtectLampStatus 4;
BA_ "SPN" SG_ 2566750462 ProtectLampStatus 987;
BA_ "SAEDocument" SG_ 2566750462 ProtectLampStatus "J1939-73";
BA_ "SigType" SG_ 2566750462 DTC5 7;
BA_ "SAEDocument" SG_ 2566750462 DTC5 "J1939-73";
BA_ "SigType" SG_ 2566750462 DTC4 7;
BA_ "SAEDocument" SG_ 2566750462 DTC4 "J1939-73";
BA_ "SigType" SG_ 2566750462 DTC3 7;
BA_ "SAEDocument" SG_ 2566750462 DTC3 "J1939-73";
BA_ "SigType" SG_ 2566750462 DTC2 7;
BA_ "SAEDocument" SG_ 2566750462 DTC2 "J1939-73";
BA_ "SigType" SG_ 2566750462 DTC1 7;
BA_ "SAEDocument" SG_ 2566750462 DTC1 "J1939-73";
BA_ "SigType" SG_ 2566750974 FlashRedStopLamp 4;
BA_ "SPN" SG_ 2566750974 FlashRedStopLamp 3039;
BA_ "SAEDocument" SG_ 2566750974 FlashRedStopLamp "J1939-73";
BA_ "SigType" SG_ 2566750974 FlashProtectLamp 4;
BA_ "SPN" SG_ 2566750974 FlashProtectLamp 3041;
BA_ "SAEDocument" SG_ 2566750974 FlashProtectLamp "J1939-73";
BA_ "SigType" SG_ 2566750974 FlashMalfuncIndicatorLamp 4;
BA_ "SPN" SG_ 2566750974 FlashMalfuncIndicatorLamp 3038;
BA_ "SAEDocument" SG_ 2566750974 FlashMalfuncIndicatorLamp "J1939-73";
BA_ "SigType" SG_ 2566750974 FlashAmberWarningLamp 4;
BA_ "SPN" SG_ 2566750974 FlashAmberWarningLamp 3040;
BA_ "SAEDocument" SG_ 2566750974 FlashAmberWarningLamp "J1939-73";
BA_ "SigType" SG_ 2566750974 MalfunctionIndicatorLampStatus 4;
BA_ "SPN" SG_ 2566750974 MalfunctionIndicatorLampStatus 1213;
BA_ "SAEDocument" SG_ 2566750974 MalfunctionIndicatorLampStatus "J1939-73";
BA_ "SigType" SG_ 2566750974 AmberWarningLampStatus 4;
BA_ "SPN" SG_ 2566750974 AmberWarningLampStatus 624;
BA_ "SAEDocument" SG_ 2566750974 AmberWarningLampStatus "J1939-73";
BA_ "SigType" SG_ 2566750974 RedStopLampState 4;
BA_ "SPN" SG_ 2566750974 RedStopLampState 623;
BA_ "SAEDocument" SG_ 2566750974 RedStopLampState "J1939-73";
BA_ "SigType" SG_ 2566750974 ProtectLampStatus 4;
BA_ "SPN" SG_ 2566750974 ProtectLampStatus 987;
BA_ "SAEDocument" SG_ 2566750974 ProtectLampStatus "J1939-73";
BA_ "SigType" SG_ 2566750974 DTC5 7;
BA_ "SAEDocument" SG_ 2566750974 DTC5 "J1939-73";
BA_ "SigType" SG_ 2566750974 DTC4 7;
BA_ "SAEDocument" SG_ 2566750974 DTC4 "J1939-73";
BA_ "SigType" SG_ 2566750974 DTC3 7;
BA_ "SAEDocument" SG_ 2566750974 DTC3 "J1939-73";
BA_ "SigType" SG_ 2566750974 DTC2 7;
BA_ "SAEDocument" SG_ 2566750974 DTC2 "J1939-73";
BA_ "SigType" SG_ 2566750974 DTC1 7;
BA_ "SAEDocument" SG_ 2566750974 DTC1 "J1939-73";
VAL_ 2566764030 FlashRedStopLamp 3 "Unavailable / Do Not Flash" 2 "Reserved" 1 "Fast Flash" 0 "Slow Flash" ;
VAL_ 2566764030 FlashProtectLamp 3 "Unavailable / Do Not Flash" 2 "Reserved" 1 "Fast Flash" 0 "Slow Flash" ;
VAL_ 2566764030 FlashMalfuncIndicatorLamp 3 "Unavailable / Do Not Flash" 2 "Reserved" 1 "Fast Flash" 0 "Slow Flash" ;
VAL_ 2566764030 FlashAmberWarningLamp 3 "Unavailable / Do Not Flash" 2 "Reserved" 1 "Fast Flash" 0 "Slow Flash" ;
VAL_ 2566764030 MalfunctionIndicatorLampStatus 3 "Not available" 2 "Reserved" 1 "Lamp on" 0 "Lamp off" ;
VAL_ 2566764030 RedStopLampState 3 "Not available" 2 "Reserved" 1 "Lamp on" 0 "Lamp off" ;
VAL_ 2566764030 AmberWarningLampStatus 3 "Not available" 2 "Reserved" 1 "Lamp on" 0 "Lamp off" ;
VAL_ 2566764030 ProtectLampStatus 3 "Not available" 2 "Reserved" 1 "Lamp on" 0 "Lamp off" ;
VAL_ 2562981630 FailureModeIdentifier1 31 "Not available" 19 "Received network data in error" 18 "Below normal (moderately severe)" 17 "Below normal (least severe)" 16 "Above normal (moderately severe)" 15 "Above normal (least severe)" 14 "Special intstructions" 13 "Out of calibration" 12 "Bad intelligent device" 11 "Root cause not known" 10 "Abnormal rate of change" 9 "Abnormal update rate" 8 "Abnormal frequency" 7 "Mechanical system not responding" 6 "Current above normal" 5 "Current below normal" 4 "Voltage below normal" 3 "Voltage above normal" 2 "Data erratic" 1 "Below normal (most severe)" 0 "Above normal (most severe)" ;
VAL_ 2566835198 MalfunctionIndicatorLampStatus 3 "Not available" 2 "Reserved" 1 "Lamp on" 0 "Lamp off" ;
VAL_ 2566835198 RedStopLampState 3 "Not available" 2 "Reserved" 1 "Lamp on" 0 "Lamp off" ;
VAL_ 2566835198 AmberWarningLampStatus 3 "Not available" 2 "Reserved" 1 "Lamp on" 0 "Lamp off" ;
VAL_ 2566835198 ProtectLampStatus 3 "Not available" 2 "Reserved" 1 "Lamp on" 0 "Lamp off" ;
VAL_ 2566835198 FlashRedStopLamp 3 "Unavailable / Do Not Flash" 2 "Reserved" 1 "Fast Flash" 0 "Slow Flash" ;
VAL_ 2566835198 FlashProtectLamp 3 "Unavailable / Do Not Flash" 2 "Reserved" 1 "Fast Flash" 0 "Slow Flash" ;
VAL_ 2566835198 FlashMalfuncIndicatorLamp 3 "Unavailable / Do Not Flash" 2 "Reserved" 1 "Fast Flash" 0 "Slow Flash" ;
VAL_ 2566835198 FlashAmberWarningLamp 3 "Unavailable / Do Not Flash" 2 "Reserved" 1 "Fast Flash" 0 "Slow Flash" ;
VAL_ 2564357886 Seed 255 "NoFurtherKeyRequiredOfTool" 1 "UseLongSeedOrKeyFromDataSecMsg" 0 "SeedCompleted_BeginSendingKey" ;
VAL_ 2564357886 EDCP_Extension 9 "DataInErrIndAndDataInSeedIsTime" 6 "DataInErrorIndicator" 3 "ConcatenateDataAsLowerEDCParam" 2 "ConcatenateDataAsHigherEDCParam" 0 "Completed" 255 "NoErrIndicator/EDCParamAvailable" ;
VAL_ 2564357886 ErrorIndicator 16777215 "NoErrorIndicatorAvailable" 65540 "TransprtNotComplWithinTimeAllowd" 65539 "TransportNotInitWithinTimeAllowd" 65538 "NoResponseInTheTimeAllowed" 65537 "ModuleExceedingNumberOfRetries" 65536 "AbortFromExtToNormalSoftwareProc" 4103 "VehicleNotInParkOrNotStationary" 4102 "EngineRunning" 4101 "NotInEngineeringOrDevelopmentMode" 4100 "NotInDiagnosticMode" 4099 "InvalidKey" 4098 "InvalidUserLevel" 4097 "InvalidPassword" 4096 "SecurityErrorGeneral" 266 "NameDoesNotConformToExpectdValue" 265 "DataDoesNotConformToValueRanges" 264 "AddrForBootLoadExeInvalidBoundary" 263 "AddrForBootLoadExeOutsideExeMem" 262 "OpReqExeTransfAndEraseOfProgMem" 261 "OpRequiresPriorEraseOfProgramMem" 260 "OpRequiresPriorEraseOfDataMem" 259 "ReqMemoryExceededAvailableMemory" 258 "LengthNotValidForMemStructAndOp" 257 "AddressNotOnValidBoundary" 256 "AddressingOrDataGeneralError" 36 "InternalFailurePreventingReq" 35 "PROMDidNotVerifyOnWrite" 34 "FLASHDidNotVerifyOnWrite" 33 "RAMDidNotVerifyOnWrite" 32 "EDCParaNotCorrectForDataStream" 31 "ProcessUnspecReqFromThisAddress" 23 "ProcessingEDCPGenerationReq" 22 "ProcessingBootLoadReq" 19 "ProcessingStatusReq" 18 "ProcessingWriteReq" 17 "ProcessingReadReq" 16 "ProcessingEraseReq" 2 "ProcessingForSomeoneElse" 1 "ErrorNotIdentified" 0 "NoError" ;
VAL_ 2564357886 Status 7 "Reserved" 6 "Reserved" 5 "OperationFailed" 4 "OperationCompleted" 3 "Reserved" 2 "Reserved" 1 "Busy" 0 "Proceed" ;
VAL_ 2564423422 KeyOrUserLevel 65535 "NoKeyAvailable" 0 "UseLongSeedOrKey" ;
VAL_ 2564423422 PointerExtension 0 "SPN_SPACE" ;
VAL_ 2564423422 Command 7 "EDCP_Generation" 6 "BootLoad" 5 "OperationFailed" 4 "OperationCompleted" 3 "StatusRequest" 2 "Write" 1 "Read" 0 "Erase" ;
VAL_ 2564423422 PointerType 1 "DirectedSpatialAddressing" 0 "DirectMemoryAddressing" ;
VAL_ 2564816638 HoldSignal 15 "Not available" 1 "Devices whose broadcast state ha" 0 "All devices" ;
VAL_ 2564816638 J1939Network3 3 "Don't care" 2 "Reserved" 1 "Start broadcast" 0 "Stop broadcast" ;
VAL_ 2564816638 J1939Network2 3 "Don't care" 2 "Reserved" 1 "Start broadcast" 0 "Stop broadcast" ;
VAL_ 2564816638 ISO9141 3 "Don't care" 2 "Reserved" 1 "Start broadcast" 0 "Stop broadcast" ;
VAL_ 2564816638 SAE_J1850 3 "Don't care" 2 "Reserved" 1 "Start broadcast" 0 "Stop broadcast" ;
VAL_ 2564816638 ManufacturerSpecificPort 3 "Don't care" 2 "Reserved" 1 "Start broadcast" 0 "Stop broadcast" ;
VAL_ 2564816638 CurrentDataLink 3 "Don't care" 2 "Reserved" 1 "Start broadcast" 0 "Stop broadcast" ;
VAL_ 2564816638 SAE_J1587 3 "Don't care" 2 "Reserved" 1 "Start broadcast" 0 "Stop broadcast" ;
VAL_ 2564816638 SAE_J1922 3 "Don't care" 2 "Reserved" 1 "Start broadcast" 0 "Stop broadcast" ;
VAL_ 2564816638 J1939Network1 3 "Don't care" 2 "Reserved" 1 "Start broadcast" 0 "Stop broadcast" ;
VAL_ 2564816638 SuspendSignal 15 "NotAvailable" 14 "ResumingNormalBroadcastPattern" 3 "TemporarySuspensionOfSomeMessages" 2 "TemporarySuspensionOfAllBroadcasts" 1 "IndefiniteSuspensionOfSomeMessages" 0 "IndefiniteSuspensionOfAllBroadcasts" ;
VAL_ 2566837502 FlashRedStopLamp 3 "Unavailable / Do Not Flash" 2 "Reserved" 1 "Fast Flash" 0 "Slow Flash" ;
VAL_ 2566837502 FlashProtectLamp 3 "Unavailable / Do Not Flash" 2 "Reserved" 1 "Fast Flash" 0 "Slow Flash" ;
VAL_ 2566837502 MalfunctionIndicatorLampStatus 3 "Not available" 2 "Reserved" 1 "Lamp on" 0 "Lamp off" ;
VAL_ 2566837502 RedStopLampState 3 "Not available" 2 "Reserved" 1 "Lamp on" 0 "Lamp off" ;
VAL_ 2566837502 AmberWarningLampStatus 3 "Not available" 2 "Reserved" 1 "Lamp on" 0 "Lamp off" ;
VAL_ 2566837502 ProtectLampStatus 3 "Not available" 2 "Reserved" 1 "Lamp on" 0 "Lamp off" ;
VAL_ 2566837502 FlashMalfuncIndicatorLamp 3 "Unavailable / Do Not Flash" 2 "Reserved" 1 "Fast Flash" 0 "Slow Flash" ;
VAL_ 2566837502 FlashAmberWarningLamp 3 "Unavailable / Do Not Flash" 2 "Reserved" 1 "Fast Flash" 0 "Slow Flash" ;
VAL_ 2566834942 FlashRedStopLamp 3 "Unavailable / Do Not Flash" 2 "Reserved" 1 "Fast Flash" 0 "Slow Flash" ;
VAL_ 2566834942 FlashProtectLamp 3 "Unavailable / Do Not Flash" 2 "Reserved" 1 "Fast Flash" 0 "Slow Flash" ;
VAL_ 2566834942 FlashMalfuncIndicatorLamp 3 "Unavailable / Do Not Flash" 2 "Reserved" 1 "Fast Flash" 0 "Slow Flash" ;
VAL_ 2566834942 FlashAmberWarningLamp 3 "Unavailable / Do Not Flash" 2 "Reserved" 1 "Fast Flash" 0 "Slow Flash" ;
VAL_ 2566834942 MalfunctionIndicatorLampStatus 3 "Not available" 2 "Reserved" 1 "Lamp on" 0 "Lamp off" ;
VAL_ 2566834942 AmberWarningLampStatus 3 "Not available" 2 "Reserved" 1 "Lamp on" 0 "Lamp off" ;
VAL_ 2566834942 RedStopLampState 3 "Not available" 2 "Reserved" 1 "Lamp on" 0 "Lamp off" ;
VAL_ 2566834942 ProtectLampStatus 3 "Not available" 2 "Reserved" 1 "Lamp on" 0 "Lamp off" ;
VAL_ 2566838526 IndustryGroup 6 "Reserved for SAE" 7 "Reserved for SAE" 5 "IndustrialProcessCtrlStationary" 4 "Marine" 3 "Construction" 2 "Agricultural and Forestry" 1 "On-Highway" 0 "Global" ;
VAL_ 2566838526 Function 127 "Reserved" 126 "Reserved" 125 "Reserved" 124 "Reserved" 123 "Reserved" 122 "Reserved" 121 "Reserved" 120 "Reserved" 119 "Reserved" 118 "Reserved" 117 "Reserved" 116 "Reserved" 115 "Reserved" 114 "Reserved" 113 "Reserved" 112 "Reserved" 111 "Reserved" 110 "Reserved" 109 "Reserved" 108 "Reserved" 107 "Reserved" 106 "Reserved" 105 "Reserved" 104 "Reserved" 103 "Reserved" 102 "Reserved" 101 "Reserved" 42 "Water Pump Control" 41 "Lighting - Operator Controls" 40 "Seat Control" 39 "Ignition Control Module" 38 "Tire Pressure Control" 37 "Cab Controller" 36 "Pneumatic - System Controller" 35 "Suspension - System Controller" 34 "Hydraulic Pump Controller" 33 "System Monitor" 32 "Headway Controller" 31 "Propulsion Battery Charger" 30 "Management Computer" 29 "Virtual Terminal (in cab)" 28 "Off Vehicle Gateway" 27 "Power TakeOff (Secondary or Front)" 26 "Body Controller" 25 "Network Interconnect ECU" 24 "Vehicle Security" 23 "Vehicle Navigation" 22 "Aerodynamic Control" 21 "Cab Climate Control" 20 "Trip Recorder" 19 "Instrument Cluster" 18 "Suspension - Drive Axle" 17 "Suspension - Steer Axle" 16 "Steering Controller" 15 "Fuel System" 14 "Cruise Control" 13 "Retarder - Driveline" 12 "Retarder - Engine" 11 "Brakes - Drive Axle" 10 "Brakes - Steer Axle" 9 "Brakes - System Controller" 8 "Axle - Drive" 7 "Axle - Steering" 6 "Power TakeOff - (Main or Rear)" 5 "Shift Control/Console" 4 "Battery Pack Monitor" 3 "Transmission" 2 "Electric Propulsion Control" 1 "Auxiliary Power Unit (APU)" 0 "Engine" 100 "Reserved" 99 "Reserved" 98 "Reserved" 97 "Reserved" 96 "Reserved" 95 "Reserved" 94 "Reserved" 93 "Reserved" 92 "Reserved" 91 "Reserved" 90 "Reserved" 89 "Reserved" 88 "Reserved" 87 "Reserved" 86 "Reserved" 85 "Reserved" 84 "Reserved" 83 "Reserved" 82 "Reserved" 81 "Reserved" 80 "Reserved" 79 "Reserved" 78 "Reserved" 77 "Reserved" 76 "Reserved" 75 "Supplemental Fan" 74 "Lubrication System" 73 "Rollover Detection Control" 72 "Coolant Valve Controller" 71 "Transfer Case Control" 70 "Auxiliary Regeneration Device" 69 "Engine Emission Aftertreatement System" 68 "Aftertreatment system gas measurement" 67 "Electrical System Controller" 66 "I/O Controller" 65 "Gas Flow Measurement" 64 "Endurance Braking" 63 "Engine Valve Controller" 62 "On-Board Diagnostic Unit" 61 "File Server/Printer" 60 "Cab Display" 59 "Starter" 58 "Fan Drive Control" 57 "Steering Column Unit" 56 "Communications Unit, Radio" 55 "Communications Unit, Satellite" 54 "Communications Unit, Cellular" 53 "Alternator/Charging System" 52 "Chassis Controller" 51 "Forward-Looking Collision Warning System" 50 "Auxiliary Heater" 49 "Clutch/Converter Control" 48 "Ramp Control" 47 "Information System Controller" 46 "Oil Sensor Unit" 45 "Vehicle Dynamic Stability Control" 44 "Exhaust Emission Control" 43 "Transmission Display" ;
VAL_ 2566838526 VehicleSystem 0 "Non-specific System" 127 "Not Available" ;
VAL_ 2566838526 ManufacturerCode 381 "B&G" 374 "Northern Lights" 373 "Electronic Design" 371 "Delphi" 370 "Heinzmann GmbH & Co. KG" 369 "Power Torque Engineering Ltd" 368 "HANSENHOF_electronic" 367 "Fliegl Agrartechnik" 366 "Viewnyx Corp." 365 "Digi-Star, LLC" 364 "OEM Controls Inc." 363 "BEI Duncan" 362 "Alois Poettinger Maschinenfabrik GmbH" 361 "InMach" 360 "HJS Fahrzeugtechnik GmbH & Co KG" 359 "Ludwig Bergmann GmbH" 358 "Victron Energy BV" 357 "Hardi International A/S" 356 "Fischer Panda Generators, Inc" 355 "Mastervolt International B.V." 354 "Junkkari OY" 353 "Hegemon Electronics, Inc." 352 "SAME DEUTZ-FAHR" 351 "Thrane & Thrane" 350 "Noris Marine Systems GmbH & Co KG" 349 "Suonentiet" 348 "Amazonen Werke H. Dreyer" 347 "Honeywell" 346 "Control Solutions" 345 "Korean Maritime University" 344 "Parvus Corporation" 343 "Baumer Group" 342 "THOMAS MAGNETE GmbH" 341 "Boning GmbH & Co" 340 "Continental AG" 339 "Competence Center ISOBUS e.V." 338 "GRAF-SYTECO" 337 "Carraro S.p.A." 336 "APE s.r.o." 335 "Evo Electric Ltd" 334 "Takata-Petri AG" 333 "Hadley Products Corporation" 332 "HWH Corporation" 331 "Horton, Inc." 330 "Kidde Aerospace and Defense" 329 "Deif A/S" 328 "Qwerty Electronik AB" 252 "Sensor-Technik Wiedemann GmbH" 251 "German Agricultural Society" 250 "Kuhn Group" 249 "Schaltbau GmbH" 233 "Yacht Monitoring Solutions Inc." 232 "TSD Integrated Controls" 1863 "Thomas G. Faria Co." 1862 "Sanshin" 1861 "Vector CANtech" 1860 "MMP" 1859 "Kvasar AB" 1858 "Litton" 1857 "Simrad" 1856 "Trimble" 1855 "Furuno USA" 1854 "Northstar Technologies" 1853 "Japan Radio Co." 1852 "Navionics" 1851 "Raymarine" 1850 "Teleflex" 222 "Generac Power Systems, Inc." 221 "SiE" 220 "Beede Electrical Instrument Company, Inc." 219 "Cat OEM Solutions" 218 "Gits Manufacturing Company" 217 "RM Michaelides Software & Elektronik GmbH" 216 "Paneltronics Inc." 215 "Aetna Engineering/Fireboy-Xintex" 214 "MC elettronica Srl" 213 "CNH Belgium N.V." 212 "Sure Power Industries, Inc." 211 "DNA Group" 210 "Iteris, Inc." 209 "Bell Equip. Co. SA (PTY) LTD" 208 "Drew Technologies, Inc." 207 "Otto Engineering" 206 "port GmbH" 205 "SmarTire Systems Inc" 204 "The Morey Corporation" 203 "MILtronik GmbH" 202 "Curtis Instruments, Inc." 201 "Disenos y Tecnologia S.A." 200 "MGM Brakes" 199 "Actia Corp." 198 "Mystic Valley Communications" 197 "Mechron Power Systems" 196 "LEMKEN GmbH & Co. KG" 195 "General Engine Products" 194 "TriMark Corporation" 193 "Nobletec" 192 "Floscan" 191 "XATA Corporation" 190 "Hella KGaA Hueck & Co." 189 "QUALCOMM" 188 "EMP Corp." 187 "Air-Weigh" 186 "Altronic, Inc." 185 "Beede Electrical Instrument Company" 184 "EIA Electronics" 183 "KDS Controls, Inc." 182 "Vehicle Systems Engineering B.V." 181 "Coretronics, Inc." 180 "Smart Power Systems" 179 "TeeJet Technologies Denmark" 178 "Siemens VDO Automotive AG" 177 "Diagnostic System Associates" 176 "Moritz Aerospace" 175 "Veris Technologies, Inc." 174 "AB Volvo Penta" 173 "Ryeso, Inc." 172 "Yanmar Marine USA" 171 "Wachendorff Elektronik GmbH & Co. KG" 170 "Computronics Corporation Ltd." 169 "Marlin Technologies Inc." 168 "Xantrex" 167 "JLG Industries Inc." 166 "Phoenix International" 165 "CPAC Systems AB" 164 "DaimlerChrysler Off-Highway" 163 "BRP Inc." 162 "Axiomatic Technologies" 161 "Offshore Systems (UK) Limited" 160 "Nido" 159 "NTech Industries Inc." 158 "Firestone Industrial Products Company" 157 "ISSPRO Inc." 156 "ITT Industries - Cannon" 155 "Vetronix Corporation" 154 "Westerbeke Corporation" 153 "Woodward, Industrial Controls Division" 152 "elobau GmbH & Co. KG" 151 "Raven Industries Inc. - Flow Controls Division" 150 "Fleetguard" 149 "Holset" 148 "Blue Water Data, Inc." 147 "Nautibus Electronic GmbH" 146 "Maxima Technologies" 145 "MurCal Controls" 144 "Mercury Marine" 143 "W. Gmeiner GmbH & Co." 142 "TRW Automotive (Commercial Steering Systems)" 141 "Thales Navigation Ltd." 140 "Lowrance Electronics, Inc." 139 "Caterpillar Trimble Control Technologies (CTCT), LLC" 138 "Georg Fritzmeier GmbH & Co. KG" 137 "Maretron" 136 "Komatsu Ltd." 135 "Airmar Technology Corporation" 134 "Iris Technology Ltd." 133 "Bucher Schoerling GmbH" 132 "Mulag-Fahrzeugwerk" 131 "ITT Industries" 130 "Nido - Universal Machines B.V." 129 "OMNEX Control Systems, Inc." 128 "Gerhard Duecker GmbH & Co. KG" 127 "Holland USA" 126 "Driver Tech" 125 "Nevada Automotive Test Center" 124 "Hydac Electronic" 123 "Basler Electric" 122 "FG Wilson (Engineering) Limited" 121 "HED (Hydro Electronic Devices, Inc.)" 120 "RDS Technology Ltd." 119 "IntegriNautics" 118 "Intron GmbH" 117 "HUSCO International" 116 "BEELINE Technologies" 115 "NACCO Materials Handling Group, Inc." 114 "EControls, Inc." 113 "Stress-Tek, Inc." 112 "MECALAC" 111 "Maschinenfabrik Bernhard Krone GmbH" 110 "EPIQ Sensor-Nite" 109 "TeeJet Technologies Denmark" 108 "WTK-Elecktronik GmbH" 107 "Grimme Landmaschinen GmbH & Co. KG" 106 "BAE Systems Controls, Inc." 105 "Kiepe Elektrik GmbH & Co. KG" 104 "Claas Selbstfahrende Erntemaschinen GmbH" 103 "Agrocom GmbH & Co. Agrarsystem KG" 102 "AGCO GmbH & Co." 101 "Sensoria" 100 "VDO Technik AG" 99 "International Transmissions Ltd (ITL)" 98 "Mueller-Elektronik GmbH & Co." 97 "Ag Leader Technology, Inc." 96 "Mech@tronic IT GmbH" 95 "Pacific Insight Electronics Corp." 94 "CNH Global N.V." 93 "Perkins Engines Company Ltd." 92 "Ag-Chem Equipment Co., Inc." 91 "BSG Bodensee Steuergeraete GmbH" 90 "Knorr-Bremse SfN GmbH" 89 "Kverneland Group, Electronics Division" 88 "Satloc Precision GPS" 87 "J.C. Bamford Excavators Ltd (JCB)" 86 "C.E. Niehoff & Company" 85 "Kohler Co." 84 "New Holland UK Limited" 83 "Eaton VORAD Technologies" 82 "Bobcat/Ingersoll-Rand" 81 "Fire Research Corp" 80 "Twin Disc, Inc." 79 "Daimler Benz AG - Engine Division (PBM)" 78 "Frank W. Murphy Manufacturing, Inc." 77 "Deere Power Systems Group" 76 "unused" 75 "Deere & Co. Agricultural Division" 74 "Eaton Axle-Brake Division" 73 "LeTourneau, Inc." 72 "Sisu Corporation" 71 "Vansco Electronics Ltd." 70 "Flex-Coil Limited" 69 "Trimble Navigation" 68 "Scania" 67 "Funk Manufacturing Company" 66 "John Deere Construction Equipment Division" 65 "MAN Nutzfahrzeuge AG" 64 "unused" 63 "ZF Industries Inc." 62 "Wabco" 61 "Volvo Truck Corp." 60 "Volvo Trucks North America Inc." 59 "VES Inc." 58 "SPX Corporation, OTC Division" 57 "Sauer-Danfoss Co." 56 "SAIC" 55 "Ryder System Inc." 54 "Meritor Wabco" 53 "Continental Automotive Systems US, Inc." 52 "Meritor Automotive, Inc." 51 "Robert Bosch GmbH" 50 "Robert Bosch Corp" 49 "RE America Inc." 48 "Pollak Alphabet" 47 "Phillips Semiconductor" 46 "Parasoft Computing Solutions" 45 "PACCAR" 44 "Nippondenso Co. Ltd." 43 "International Truck and Engine Corp. Vehicle Electronics" 42 "International Truck and Engine Corp. Engine Electronics" 41 "Motorola Inc." 40 "Motorola AIEG Inc." 39 "Microfirm Inc." 38 "Micro Processor Systems Inc." 37 "Mack Trucks Inc." 36 "Lucas Ltd." 35 "Kenworth Truck Co." 34 "Kelsey Hayes Co." 33 "John Deere" 32 "Jacobs Vehicle Systems" 31 "J Pollak Corp." 30 "Isuzu Motors Ltd." 29 "Hino Motors Ltd." 28 "Grote Ind. Inc." 27 "GMC" 26 "General Motors Corp., Service Technology Group" 25 "Daimler Trucks North America LLC" 24 "Ford Motor Co., Vehicle Controls" 23 "Ford Motor Co., Heavy Truck" 22 "Ford Motor Co., Electronic Concepts $ Systems" 21 "Echilin Inc., Midland Brake Inc." 20 "Eaton Ltd" 19 "Eaton Corp. Trucking Info Services" 18 "Eaton Corp, Transmission Division" 17 "Eaton Corp. Res & Dev" 16 "Eaton Corp." 15 "Dickey-John Corp." 14 "Detroit Diesel Corporation" 13 "Delco Electronics" 12 "Deere & Company, Precision Farming" 11 "Dearborn Group Inc." 10 "Cummins Engine Co." 9 "Chrysler Corp." 8 "Caterpillar Inc." 7 "Case Corp." 6 "Berifors Electronics AB" 5 "AMP Inc." 4 "Ametek-Dixson" 3 "Ametek, US Gauge Division" 2 "Allison Transmission, GMC" 1 "Allied Signal Inc." 0 "Reserved" 231 "Topcon Positioning Systems, Inc." 230 "Saucon Technologies" 229 "Garmin International Inc." 228 "ZF Marine Electronics" 227 "Lykketronic A/S" 226 "Monaco Coach Corporation" 225 "SKF" 224 "EMMI Network, S.L." 223 "Vaueo Retarder Co., Ltd." 263 "IMMI" 262 "HydraForce, Inc" 261 "Red Dot Corporation" 260 "Reichhardt GmbH" 259 "Jetter AG" 258 "ARAG" 257 "Honda Motor Co., Ltd" 256 "Tyco Electronics AMP" 255 "MEAS France" 254 "GE Sensing" 253 "Mobile Control Systems" 298 "Holley Performance" 297 "Zonar Systems Inc" 296 "micro dynamics GmbH" 295 "BEP Marine" 294 "Grayhill Inc." 293 "Spyder Controls Corp." 292 "IKUSI - Angel Iglesias S.A." 291 "Groeneveld Transport Efficiency BV" 290 "Kuebler GmbH" 289 "Watlow" 288 "Mitsubishi FUSO Truck & Bus Corp." 287 "NTech Industries, Inc" 286 "Coelmo srl" 285 "Sea Recovery Corp" 284 "Mobile Tech Chile" 283 "CWF Hamilton & Co Ltd" 282 "Medallion Instrumentation Systems" 281 "Precision Governors LLC" 311 "Patrick Power Products" 310 "TECNORD srl" 309 "Krauss-Maffei Wegmann GmbH & Co. KG" 308 "Cyntrx" 307 "MAS Technologies" 306 "Sleipner Motor AB" 305 "NovAtel Inc" 304 "EmpirBus AB" 303 "CTS Corporation" 302 "Nissin Kogyo Co., LTD" 301 "Parker Hannifin (UK) Ltd FDE group" 300 "Systron Donner Automotive" 299 "Rauch Landmaschinen GmbH" 280 "Leica Geosystems Pty Ltd" 279 "Geometris LP" 278 "Takata Electronics" 277 "LHP Telematics" 276 "Aqua-Hot Heating Systems" 275 "Navico Egersund AS" 274 "LTW Technology Co., LTD" 273 "Active Research Limited" 272 "Gross Mechanical Laboratories, Inc" 327 "Sonceboz SA" 326 "Akron Brass Company" 325 "ASM Automation Sensorik Messtechnik GmbH" 324 "Snap-on Diagnostics" 323 "Mobileye Vision Technologies Ltd." 322 "MICHENKA s.r.o." 321 "Ultra Electronics, Electrics" 320 "Miedema Landbouwwerktuigenfabriek B.V." 319 "Cadec Global" 318 "SAT Plan" 317 "Navtronics Bvba" 316 "ITT Flow Control" 315 "Icom Incorporated" 314 "CSM GmbH" 313 "Ilmor Engineering, Inc" 312 "Lectronix, Inc." 271 "Cole Hersee" 270 "Tennant" 269 "Saft America Inc.,  Space & Defense Division" 268 "Accurate Technologies" 267 "Red Lion Controls, Inc" 266 "International Thermal Research Ltd" 265 "MTS Sensor Technologie GmbH" 264 "Autolync" 248 "Cooper Standard Automotive Active Systems Group" 247 "ePULSE" 246 "Class 1, Inc" 245 "Capstan Ag Systems, Inc." 244 "Techno-Matic" 243 "eRide, Inc." 242 "Kokusandenki Co. Ltd" 241 "Schneider Automation SAS " 240 "Vanair Mfg" 239 "May & Scofield Ltd" 238 "ZF Friedrichshafen AG" 237 "Agtron Enterprises Inc" 236 "Norac Systems International Inc" 235 "SailorMade Marine Telemetry - Tetra Technology Ltd." 234 "Mondial electronic GmbH" ;
VAL_ 2566838526 VehicleSystem5 127 "Not Available" 0 "Ind. Process Control Stationary" ;
VAL_ 2566838526 VehicleSystem4 100 "Deck/Cargo/Fishing equip. sys" 90 "Environmental (HVAC) Systems" 80 "Instrumentation/General Systems" 70 "Communications Systems" 60 "Navigation Systems" 50 "Propulsion Systems" 40 "Steering Systems" 30 "Power Mgmt and lighting systems" 25 "Gateway" 20 "Safety Systems" 10 "System Tools" 127 "Not Available" 0 "Non-specific System" ;
VAL_ 2566838526 VehicleSystem3 8 "Grader" 7 "Four Wheel Drive Loader" 6 "Forklift" 5 "Excavator" 4 "Crawler" 3 "Backhoe" 2 "Articulated Dump Truck" 1 "Skid Steer Loader" 127 "Not Available" 0 "Non-specific System" ;
VAL_ 2566838526 VehicleSystem2 16 "Skidder" 15 "Earth Work" 14 "Special Crops" 13 "Powered Auxiliary Device" 12 "Farm Yard Operations" 11 "Transport/Trailer" 10 "Irrigation" 9 "Forage" 8 "Root Harvesters" 7 "Harvesters" 6 "Sprayers" 5 "Fertilizers" 4 "Planters/Seeders" 3 "Secondary Tillage" 2 "Tillage" 1 "Tractor" 127 "Not Available" 0 "Non-specific System" ;
VAL_ 2566838526 VehicleSystem1 2 "Trailer" 1 "Tractor" 127 "Not Available" 0 "Non-specific System" ;
VAL_ 2632777470 PGNumber 255 "NotAvailable" ;
VAL_ 2632777470 ControlByte 24 "EAbort" 23 "EEoMACK" 22 "EDPO" 21 "ECTS" 20 "ERTS" 255 "Abort" 32 "BAM" 19 "EoMA" 17 "CTS" 16 "RTS" ;
VAL_ 2566739198 FlashRedStopLamp 3 "Unavailable / Do Not Flash" 2 "Reserved" 1 "Fast Flash" 0 "Slow Flash" ;
VAL_ 2566739198 FlashProtectLamp 3 "Unavailable / Do Not Flash" 2 "Reserved" 1 "Fast Flash" 0 "Slow Flash" ;
VAL_ 2566739198 FlashMalfuncIndicatorLamp 3 "Unavailable / Do Not Flash" 2 "Reserved" 1 "Fast Flash" 0 "Slow Flash" ;
VAL_ 2566739198 FlashAmberWarningLamp 3 "Unavailable / Do Not Flash" 2 "Reserved" 1 "Fast Flash" 0 "Slow Flash" ;
VAL_ 2566739198 MalfunctionIndicatorLampStatus 3 "Not available" 2 "Reserved" 1 "Lamp on" 0 "Lamp off" ;
VAL_ 2566739198 AmberWarningLampStatus 3 "Not available" 2 "Reserved" 1 "Lamp on" 0 "Lamp off" ;
VAL_ 2566739198 RedStopLampState 3 "Not available" 2 "Reserved" 1 "Lamp on" 0 "Lamp off" ;
VAL_ 2566739198 ProtectLampStatus 3 "Not available" 2 "Reserved" 1 "Lamp on" 0 "Lamp off" ;
VAL_ 2566739454 FlashRedStopLamp 3 "Unavailable / Do Not Flash" 2 "Reserved" 1 "Fast Flash" 0 "Slow Flash" ;
VAL_ 2566739454 FlashProtectLamp 3 "Unavailable / Do Not Flash" 2 "Reserved" 1 "Fast Flash" 0 "Slow Flash" ;
VAL_ 2566739454 FlashMalfuncIndicatorLamp 3 "Unavailable / Do Not Flash" 2 "Reserved" 1 "Fast Flash" 0 "Slow Flash" ;
VAL_ 2566739454 FlashAmberWarningLamp 3 "Unavailable / Do Not Flash" 2 "Reserved" 1 "Fast Flash" 0 "Slow Flash" ;
VAL_ 2566739454 MalfunctionIndicatorLampStatus 3 "Not available" 2 "Reserved" 1 "Lamp on" 0 "Lamp off" ;
VAL_ 2566739454 AmberWarningLampStatus 3 "Not available" 2 "Reserved" 1 "Lamp on" 0 "Lamp off" ;
VAL_ 2566739454 RedStopLampState 3 "Not available" 2 "Reserved" 1 "Lamp on" 0 "Lamp off" ;
VAL_ 2566739454 ProtectLampStatus 3 "Not available" 2 "Reserved" 1 "Lamp on" 0 "Lamp off" ;
VAL_ 2566739710 FlashRedStopLamp 3 "Unavailable / Do Not Flash" 2 "Reserved" 1 "Fast Flash" 0 "Slow Flash" ;
VAL_ 2566739710 FlashProtectLamp 3 "Unavailable / Do Not Flash" 2 "Reserved" 1 "Fast Flash" 0 "Slow Flash" ;
VAL_ 2566739710 FlashMalfuncIndicatorLamp 3 "Unavailable / Do Not Flash" 2 "Reserved" 1 "Fast Flash" 0 "Slow Flash" ;
VAL_ 2566739710 FlashAmberWarningLamp 3 "Unavailable / Do Not Flash" 2 "Reserved" 1 "Fast Flash" 0 "Slow Flash" ;
VAL_ 2566739710 MalfunctionIndicatorLampStatus 3 "Not available" 2 "Reserved" 1 "Lamp on" 0 "Lamp off" ;
VAL_ 2566739710 AmberWarningLampStatus 3 "Not available" 2 "Reserved" 1 "Lamp on" 0 "Lamp off" ;
VAL_ 2566739710 RedStopLampState 3 "Not available" 2 "Reserved" 1 "Lamp on" 0 "Lamp off" ;
VAL_ 2566739710 ProtectLampStatus 3 "Not available" 2 "Reserved" 1 "Lamp on" 0 "Lamp off" ;
VAL_ 2566739966 FlashRedStopLamp 3 "Unavailable / Do Not Flash" 2 "Reserved" 1 "Fast Flash" 0 "Slow Flash" ;
VAL_ 2566739966 FlashProtectLamp 3 "Unavailable / Do Not Flash" 2 "Reserved" 1 "Fast Flash" 0 "Slow Flash" ;
VAL_ 2566739966 FlashMalfuncIndicatorLamp 3 "Unavailable / Do Not Flash" 2 "Reserved" 1 "Fast Flash" 0 "Slow Flash" ;
VAL_ 2566739966 FlashAmberWarningLamp 3 "Unavailable / Do Not Flash" 2 "Reserved" 1 "Fast Flash" 0 "Slow Flash" ;
VAL_ 2566739966 MalfunctionIndicatorLampStatus 3 "Not available" 2 "Reserved" 1 "Lamp on" 0 "Lamp off" ;
VAL_ 2566739966 AmberWarningLampStatus 3 "Not available" 2 "Reserved" 1 "Lamp on" 0 "Lamp off" ;
VAL_ 2566739966 RedStopLampState 3 "Not available" 2 "Reserved" 1 "Lamp on" 0 "Lamp off" ;
VAL_ 2566739966 ProtectLampStatus 3 "Not available" 2 "Reserved" 1 "Lamp on" 0 "Lamp off" ;
VAL_ 2566740222 FlashRedStopLamp 3 "Unavailable / Do Not Flash" 2 "Reserved" 1 "Fast Flash" 0 "Slow Flash" ;
VAL_ 2566740222 FlashProtectLamp 3 "Unavailable / Do Not Flash" 2 "Reserved" 1 "Fast Flash" 0 "Slow Flash" ;
VAL_ 2566740222 FlashMalfuncIndicatorLamp 3 "Unavailable / Do Not Flash" 2 "Reserved" 1 "Fast Flash" 0 "Slow Flash" ;
VAL_ 2566740222 FlashAmberWarningLamp 3 "Unavailable / Do Not Flash" 2 "Reserved" 1 "Fast Flash" 0 "Slow Flash" ;
VAL_ 2566740222 MalfunctionIndicatorLampStatus 3 "Not available" 2 "Reserved" 1 "Lamp on" 0 "Lamp off" ;
VAL_ 2566740222 AmberWarningLampStatus 3 "Not available" 2 "Reserved" 1 "Lamp on" 0 "Lamp off" ;
VAL_ 2566740222 RedStopLampState 3 "Not available" 2 "Reserved" 1 "Lamp on" 0 "Lamp off" ;
VAL_ 2566740222 ProtectLampStatus 3 "Not available" 2 "Reserved" 1 "Lamp on" 0 "Lamp off" ;
VAL_ 2566740478 FlashRedStopLamp 3 "Unavailable / Do Not Flash" 2 "Reserved" 1 "Fast Flash" 0 "Slow Flash" ;
VAL_ 2566740478 FlashProtectLamp 3 "Unavailable / Do Not Flash" 2 "Reserved" 1 "Fast Flash" 0 "Slow Flash" ;
VAL_ 2566740478 FlashMalfuncIndicatorLamp 3 "Unavailable / Do Not Flash" 2 "Reserved" 1 "Fast Flash" 0 "Slow Flash" ;
VAL_ 2566740478 FlashAmberWarningLamp 3 "Unavailable / Do Not Flash" 2 "Reserved" 1 "Fast Flash" 0 "Slow Flash" ;
VAL_ 2566740478 MalfunctionIndicatorLampStatus 3 "Not available" 2 "Reserved" 1 "Lamp on" 0 "Lamp off" ;
VAL_ 2566740478 AmberWarningLampStatus 3 "Not available" 2 "Reserved" 1 "Lamp on" 0 "Lamp off" ;
VAL_ 2566740478 RedStopLampState 3 "Not available" 2 "Reserved" 1 "Lamp on" 0 "Lamp off" ;
VAL_ 2566740478 ProtectLampStatus 3 "Not available" 2 "Reserved" 1 "Lamp on" 0 "Lamp off" ;
VAL_ 2566740734 FlashRedStopLamp 3 "Unavailable / Do Not Flash" 2 "Reserved" 1 "Fast Flash" 0 "Slow Flash" ;
VAL_ 2566740734 FlashProtectLamp 3 "Unavailable / Do Not Flash" 2 "Reserved" 1 "Fast Flash" 0 "Slow Flash" ;
VAL_ 2566740734 FlashMalfuncIndicatorLamp 3 "Unavailable / Do Not Flash" 2 "Reserved" 1 "Fast Flash" 0 "Slow Flash" ;
VAL_ 2566740734 FlashAmberWarningLamp 3 "Unavailable / Do Not Flash" 2 "Reserved" 1 "Fast Flash" 0 "Slow Flash" ;
VAL_ 2566740734 MalfunctionIndicatorLampStatus 3 "Not available" 2 "Reserved" 1 "Lamp on" 0 "Lamp off" ;
VAL_ 2566740734 AmberWarningLampStatus 3 "Not available" 2 "Reserved" 1 "Lamp on" 0 "Lamp off" ;
VAL_ 2566740734 RedStopLampState 3 "Not available" 2 "Reserved" 1 "Lamp on" 0 "Lamp off" ;
VAL_ 2566740734 ProtectLampStatus 3 "Not available" 2 "Reserved" 1 "Lamp on" 0 "Lamp off" ;
VAL_ 2566740990 FlashRedStopLamp 3 "Unavailable / Do Not Flash" 2 "Reserved" 1 "Fast Flash" 0 "Slow Flash" ;
VAL_ 2566740990 FlashProtectLamp 3 "Unavailable / Do Not Flash" 2 "Reserved" 1 "Fast Flash" 0 "Slow Flash" ;
VAL_ 2566740990 FlashMalfuncIndicatorLamp 3 "Unavailable / Do Not Flash" 2 "Reserved" 1 "Fast Flash" 0 "Slow Flash" ;
VAL_ 2566740990 FlashAmberWarningLamp 3 "Unavailable / Do Not Flash" 2 "Reserved" 1 "Fast Flash" 0 "Slow Flash" ;
VAL_ 2566740990 MalfunctionIndicatorLampStatus 3 "Not available" 2 "Reserved" 1 "Lamp on" 0 "Lamp off" ;
VAL_ 2566740990 AmberWarningLampStatus 3 "Not available" 2 "Reserved" 1 "Lamp on" 0 "Lamp off" ;
VAL_ 2566740990 RedStopLampState 3 "Not available" 2 "Reserved" 1 "Lamp on" 0 "Lamp off" ;
VAL_ 2566740990 ProtectLampStatus 3 "Not available" 2 "Reserved" 1 "Lamp on" 0 "Lamp off" ;
VAL_ 2566741246 FlashRedStopLamp 3 "Unavailable / Do Not Flash" 2 "Reserved" 1 "Fast Flash" 0 "Slow Flash" ;
VAL_ 2566741246 FlashProtectLamp 3 "Unavailable / Do Not Flash" 2 "Reserved" 1 "Fast Flash" 0 "Slow Flash" ;
VAL_ 2566741246 FlashMalfuncIndicatorLamp 3 "Unavailable / Do Not Flash" 2 "Reserved" 1 "Fast Flash" 0 "Slow Flash" ;
VAL_ 2566741246 FlashAmberWarningLamp 3 "Unavailable / Do Not Flash" 2 "Reserved" 1 "Fast Flash" 0 "Slow Flash" ;
VAL_ 2566741246 MalfunctionIndicatorLampStatus 3 "Not available" 2 "Reserved" 1 "Lamp on" 0 "Lamp off" ;
VAL_ 2566741246 AmberWarningLampStatus 3 "Not available" 2 "Reserved" 1 "Lamp on" 0 "Lamp off" ;
VAL_ 2566741246 RedStopLampState 3 "Not available" 2 "Reserved" 1 "Lamp on" 0 "Lamp off" ;
VAL_ 2566741246 ProtectLampStatus 3 "Not available" 2 "Reserved" 1 "Lamp on" 0 "Lamp off" ;
VAL_ 2566741502 FlashRedStopLamp 3 "Unavailable / Do Not Flash" 2 "Reserved" 1 "Fast Flash" 0 "Slow Flash" ;
VAL_ 2566741502 FlashProtectLamp 3 "Unavailable / Do Not Flash" 2 "Reserved" 1 "Fast Flash" 0 "Slow Flash" ;
VAL_ 2566741502 FlashMalfuncIndicatorLamp 3 "Unavailable / Do Not Flash" 2 "Reserved" 1 "Fast Flash" 0 "Slow Flash" ;
VAL_ 2566741502 FlashAmberWarningLamp 3 "Unavailable / Do Not Flash" 2 "Reserved" 1 "Fast Flash" 0 "Slow Flash" ;
VAL_ 2566741502 MalfunctionIndicatorLampStatus 3 "Not available" 2 "Reserved" 1 "Lamp on" 0 "Lamp off" ;
VAL_ 2566741502 AmberWarningLampStatus 3 "Not available" 2 "Reserved" 1 "Lamp on" 0 "Lamp off" ;
VAL_ 2566741502 RedStopLampState 3 "Not available" 2 "Reserved" 1 "Lamp on" 0 "Lamp off" ;
VAL_ 2566741502 ProtectLampStatus 3 "Not available" 2 "Reserved" 1 "Lamp on" 0 "Lamp off" ;
VAL_ 2566741758 FlashRedStopLamp 3 "Unavailable / Do Not Flash" 2 "Reserved" 1 "Fast Flash" 0 "Slow Flash" ;
VAL_ 2566741758 FlashProtectLamp 3 "Unavailable / Do Not Flash" 2 "Reserved" 1 "Fast Flash" 0 "Slow Flash" ;
VAL_ 2566741758 FlashMalfuncIndicatorLamp 3 "Unavailable / Do Not Flash" 2 "Reserved" 1 "Fast Flash" 0 "Slow Flash" ;
VAL_ 2566741758 FlashAmberWarningLamp 3 "Unavailable / Do Not Flash" 2 "Reserved" 1 "Fast Flash" 0 "Slow Flash" ;
VAL_ 2566741758 MalfunctionIndicatorLampStatus 3 "Not available" 2 "Reserved" 1 "Lamp on" 0 "Lamp off" ;
VAL_ 2566741758 AmberWarningLampStatus 3 "Not available" 2 "Reserved" 1 "Lamp on" 0 "Lamp off" ;
VAL_ 2566741758 RedStopLampState 3 "Not available" 2 "Reserved" 1 "Lamp on" 0 "Lamp off" ;
VAL_ 2566741758 ProtectLampStatus 3 "Not available" 2 "Reserved" 1 "Lamp on" 0 "Lamp off" ;
VAL_ 2566742014 FlashRedStopLamp 3 "Unavailable / Do Not Flash" 2 "Reserved" 1 "Fast Flash" 0 "Slow Flash" ;
VAL_ 2566742014 FlashProtectLamp 3 "Unavailable / Do Not Flash" 2 "Reserved" 1 "Fast Flash" 0 "Slow Flash" ;
VAL_ 2566742014 FlashMalfuncIndicatorLamp 3 "Unavailable / Do Not Flash" 2 "Reserved" 1 "Fast Flash" 0 "Slow Flash" ;
VAL_ 2566742014 FlashAmberWarningLamp 3 "Unavailable / Do Not Flash" 2 "Reserved" 1 "Fast Flash" 0 "Slow Flash" ;
VAL_ 2566742014 MalfunctionIndicatorLampStatus 3 "Not available" 2 "Reserved" 1 "Lamp on" 0 "Lamp off" ;
VAL_ 2566742014 AmberWarningLampStatus 3 "Not available" 2 "Reserved" 1 "Lamp on" 0 "Lamp off" ;
VAL_ 2566742014 RedStopLampState 3 "Not available" 2 "Reserved" 1 "Lamp on" 0 "Lamp off" ;
VAL_ 2566742014 ProtectLampStatus 3 "Not available" 2 "Reserved" 1 "Lamp on" 0 "Lamp off" ;
VAL_ 2560622334 FlashRedStopLamp 3 "Unavailable / Do Not Flash" 2 "Reserved" 1 "Fast Flash" 0 "Slow Flash" ;
VAL_ 2560622334 FlashProtectLamp 3 "Unavailable / Do Not Flash" 2 "Reserved" 1 "Fast Flash" 0 "Slow Flash" ;
VAL_ 2560622334 FlashMalfuncIndicatorLamp 3 "Unavailable / Do Not Flash" 2 "Reserved" 1 "Fast Flash" 0 "Slow Flash" ;
VAL_ 2560622334 FlashAmberWarningLamp 3 "Unavailable / Do Not Flash" 2 "Reserved" 1 "Fast Flash" 0 "Slow Flash" ;
VAL_ 2560622334 MalfunctionIndicatorLampStatus 3 "Not available" 2 "Reserved" 1 "Lamp on" 0 "Lamp off" ;
VAL_ 2560622334 AmberWarningLampStatus 3 "Not available" 2 "Reserved" 1 "Lamp on" 0 "Lamp off" ;
VAL_ 2560622334 RedStopLampState 3 "Not available" 2 "Reserved" 1 "Lamp on" 0 "Lamp off" ;
VAL_ 2560622334 ProtectLampStatus 3 "Not available" 2 "Reserved" 1 "Lamp on" 0 "Lamp off" ;
VAL_ 2566750462 FlashRedStopLamp 3 "Unavailable / Do Not Flash" 2 "Reserved" 1 "Fast Flash" 0 "Slow Flash" ;
VAL_ 2566750462 FlashProtectLamp 3 "Unavailable / Do Not Flash" 2 "Reserved" 1 "Fast Flash" 0 "Slow Flash" ;
VAL_ 2566750462 FlashMalfuncIndicatorLamp 3 "Unavailable / Do Not Flash" 2 "Reserved" 1 "Fast Flash" 0 "Slow Flash" ;
VAL_ 2566750462 FlashAmberWarningLamp 3 "Unavailable / Do Not Flash" 2 "Reserved" 1 "Fast Flash" 0 "Slow Flash" ;
VAL_ 2566750462 MalfunctionIndicatorLampStatus 3 "Not available" 2 "Reserved" 1 "Lamp on" 0 "Lamp off" ;
VAL_ 2566750462 AmberWarningLampStatus 3 "Not available" 2 "Reserved" 1 "Lamp on" 0 "Lamp off" ;
VAL_ 2566750462 RedStopLampState 3 "Not available" 2 "Reserved" 1 "Lamp on" 0 "Lamp off" ;
VAL_ 2566750462 ProtectLampStatus 3 "Not available" 2 "Reserved" 1 "Lamp on" 0 "Lamp off" ;
VAL_ 2566750974 FlashRedStopLamp 3 "Unavailable / Do Not Flash" 2 "Reserved" 1 "Fast Flash" 0 "Slow Flash" ;
VAL_ 2566750974 FlashProtectLamp 3 "Unavailable / Do Not Flash" 2 "Reserved" 1 "Fast Flash" 0 "Slow Flash" ;
VAL_ 2566750974 FlashMalfuncIndicatorLamp 3 "Unavailable / Do Not Flash" 2 "Reserved" 1 "Fast Flash" 0 "Slow Flash" ;
VAL_ 2566750974 FlashAmberWarningLamp 3 "Unavailable / Do Not Flash" 2 "Reserved" 1 "Fast Flash" 0 "Slow Flash" ;
VAL_ 2566750974 MalfunctionIndicatorLampStatus 3 "Not available" 2 "Reserved" 1 "Lamp on" 0 "Lamp off" ;
VAL_ 2566750974 AmberWarningLampStatus 3 "Not available" 2 "Reserved" 1 "Lamp on" 0 "Lamp off" ;
VAL_ 2566750974 RedStopLampState 3 "Not available" 2 "Reserved" 1 "Lamp on" 0 "Lamp off" ;
VAL_ 2566750974 ProtectLampStatus 3 "Not available" 2 "Reserved" 1 "Lamp on" 0 "Lamp off" ;
